VERSION ""

NS_ :

BS_:

BU_: GFM2_BCCMB ACCMB GFM3_DCACB FHCM SOBDMB_AWDC DCACA_GAS DCACA_HEV DCDC_LISB BCMC_CPDB DCMR_EAWD DCMR_ELSD BECMB_EPM PACM GFM_CPLR OBCC AFCM SOBDM_BCCM GWM _delete BCM ACCM GFM2_UIM ICM DCDC_HEV BECM SOBDMD_AHCM_PTC GENERIC TSTR

BO_ 533 APIM_Send_Signals_2_HS1: 8 GWM
 SG_ ClrExitAsstEnbl_D_RqMnu : 60|2@0+ (1,0) [0|3] "SED"  GENERIC
 SG_ PaakMyKey_D_Rq : 7|2@0+ (1,0) [0|3] "SED"  BCM
 SG_ AutoEpbZoomView_B_Stat : 32|1@0+ (1,0) [0|1] "SED"  GENERIC
 SG_ AutoEpbButtn_B_Stat : 19|1@0+ (1,0) [0|1] "SED"  GENERIC
 SG_ DcacPw_D_Rq : 62|2@0+ (1,0) [0|3] "SED"  GENERIC
 SG_ DcacPwReset_B_Rq : 63|1@0+ (1,0) [0|1] "SED"  GENERIC
 SG_ OtaTrg_D_Stat : 41|2@0+ (1,0) [0|3] "SED"  GENERIC
 SG_ DcacPwLoButtn_B_Stat : 13|1@0+ (1,0) [0|1] "SED"  GENERIC
 SG_ DcacPwOffButtn_B_Stat : 12|1@0+ (1,0) [0|1] "SED"  GENERIC
 SG_ DcacPwHiButtn_B_Stat : 14|1@0+ (1,0) [0|1] "SED"  GENERIC
 SG_ DcacPwResetButtn_B_Stat : 11|1@0+ (1,0) [0|1] "SED"  GENERIC
 SG_ DcacPwButtn_B_Falt : 15|1@0+ (1,0) [0|1] "SED"  GENERIC
 SG_ OnbChrgGoTTouch_D_Rq : 43|2@0+ (1,0) [0|3] "SED" Vector__XXX
 SG_ OnbChrgGoTPrcond_D_Rq : 34|2@0+ (1,0) [0|3] "SED" Vector__XXX
 SG_ OnbChrgGoTOn_D_Rq : 25|2@0+ (1,0) [0|3] "SED" Vector__XXX
 SG_ OnbChrgGoTMnte_D_Rq : 47|4@0+ (1,0) [0|15] "minute" Vector__XXX
 SG_ OnbChrgGoTHr_T_Rq : 39|5@0+ (1,0) [0|29] "hour" Vector__XXX
 SG_ OnbChrgGoTExtHtr_D_Rq : 27|2@0+ (1,0) [0|3] "SED" Vector__XXX
 SG_ OnbChrgGoTElement_D_Rq : 31|4@0+ (1,0) [0|15] "Unitless" Vector__XXX
 SG_ OnbChrgGoTDelete_B_Rq : 17|1@0+ (1,0) [0|1] "SED" Vector__XXX
 SG_ OnbChrgClearAll_B_Rq : 18|1@0+ (1,0) [0|1] "SED" Vector__XXX
 SG_ OnbChrgGoTUpdate_B_Rq : 16|1@0+ (1,0) [0|1] "SED" Vector__XXX
 SG_ TrlrAidMde_D_Rq : 5|2@0+ (1,0) [0|3] "SED"  GENERIC
 SG_ TCU_Init_Actvtn_St : 1|2@0+ (1,0) [0|3] "SED"  GENERIC
 SG_ TCU_Final_Actvtn_St : 3|2@0+ (1,0) [0|3] "SED"  GENERIC
 SG_ TrlrAlarmButtn_B_Stat : 50|1@0+ (1,0) [0|1] "SED"  GENERIC
 SG_ DcacMdeButtn_B_Stat : 8|1@0+ (1,0) [0|1] "SED"  GENERIC
 SG_ LghtAmbDrvMde_D_Rq : 49|2@0+ (1,0) [0|3] "SED"  BCM
 SG_ DcacGfciTestBttn_B_Stat : 9|1@0+ (1,0) [0|1] "SED"  GENERIC
 SG_ TrlrHitch_D_RqMnu : 23|4@0+ (1,0) [0|15] "SED"  GENERIC
 SG_ TrlrBrkGain_No_Rq : 55|5@0+ (0.5,0) [0|15.5] "unitless"  GENERIC
 SG_ DcacPwButtn_B_Stat : 10|1@0+ (1,0) [0|1] "SED"  GENERIC

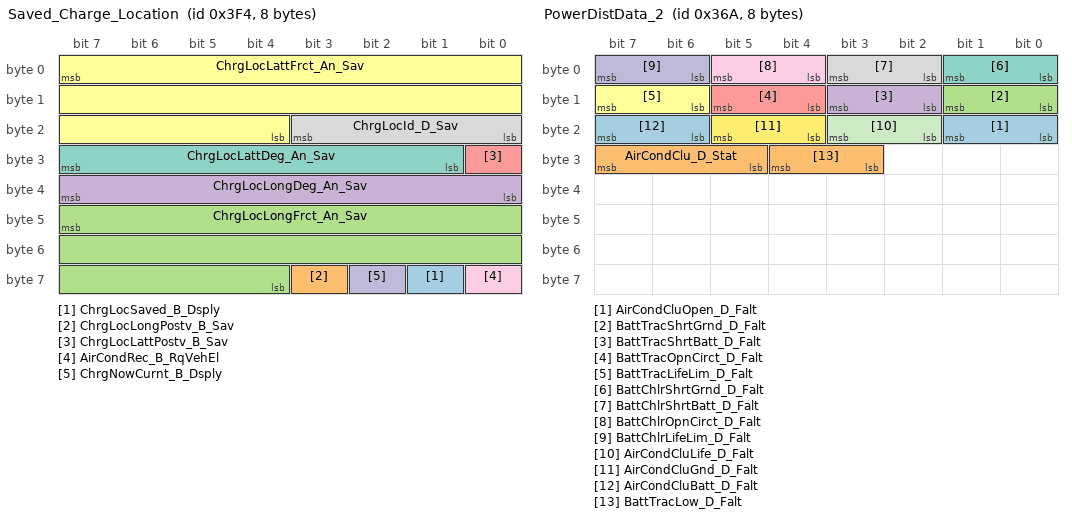
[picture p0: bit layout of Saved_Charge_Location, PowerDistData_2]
BO_ 1012 Saved_Charge_Location: 8 GWM
 SG_ ChrgLocSaved_B_Dsply : 57|1@0+ (1,0) [0|1] "SED"  GENERIC
 SG_ ChrgLocLongPostv_B_Sav : 59|1@0+ (1,0) [0|1] "SED"  GENERIC
 SG_ ChrgLocLongFrct_An_Sav : 47|20@0+ (1E-006,0) [0|1.048575] "degrees"  GENERIC
 SG_ ChrgLocLongDeg_An_Sav : 39|8@0+ (1,0) [0|255] "degrees"  GENERIC
 SG_ ChrgLocLattPostv_B_Sav : 24|1@0+ (1,0) [0|1] "SED"  GENERIC
 SG_ ChrgLocLattFrct_An_Sav : 7|20@0+ (1E-006,0) [0|1.048575] "degrees"  GENERIC
 SG_ ChrgLocLattDeg_An_Sav : 31|7@0+ (1,0) [0|127] "unitless"  GENERIC
 SG_ ChrgLocId_D_Sav : 19|4@0+ (1,0) [0|15] "unitless"  GENERIC
 SG_ AirCondRec_B_RqVehEl : 56|1@0+ (1,0) [0|1] "SED"  GENERIC
 SG_ ChrgNowCurnt_B_Dsply : 58|1@0+ (1,0) [0|1] "SED"  SOBDM_BCCM

BO_ 1711 DCMR_Rapid_Data_Response_4: 8 DCMR_EAWD
 SG_ UUDTDCMRResponse4 : 7|64@0+ (1,0) [0|1.84467440737096E+019] "unitless"  TSTR

BO_ 1710 DCMR_Rapid_Data_Response_3: 8 DCMR_EAWD
 SG_ UUDTDCMRResponse3 : 7|64@0+ (1,0) [0|1.84467440737096E+019] "unitless"  TSTR

BO_ 1709 DCMR_Rapid_Data_Response_2: 8 DCMR_EAWD
 SG_ UUDTDCMRResponse2 : 7|64@0+ (1,0) [0|1.84467440737096E+019] "unitless"  TSTR

BO_ 1708 DCMR_Rapid_Data_Response_1: 8 DCMR_EAWD
 SG_ UUDTDCMRResponse1 : 7|64@0+ (1,0) [0|1.84467440737096E+019] "unitless"  TSTR

BO_ 874 PowerDistData_2: 8 BCMC_CPDB
 SG_ AirCondCluOpen_D_Falt : 17|2@0+ (1,0) [0|3] "SED"  GWM
 SG_ AirCondClu_D_Stat : 31|3@0+ (1,0) [0|7] "SED"  GWM
 SG_ BattTracShrtGrnd_D_Falt : 9|2@0+ (1,0) [0|3] "SED"  GWM
 SG_ BattTracShrtBatt_D_Falt : 11|2@0+ (1,0) [0|3] "SED"  GWM
 SG_ BattTracOpnCirct_D_Falt : 13|2@0+ (1,0) [0|3] "SED"  GWM
 SG_ BattTracLifeLim_D_Falt : 15|2@0+ (1,0) [0|3] "SED"  GWM
 SG_ BattChlrShrtGrnd_D_Falt : 1|2@0+ (1,0) [0|3] "SED"  GWM
 SG_ BattChlrShrtBatt_D_Falt : 3|2@0+ (1,0) [0|3] "SED"  GWM
 SG_ BattChlrOpnCirct_D_Falt : 5|2@0+ (1,0) [0|3] "SED"  GWM
 SG_ BattChlrLifeLim_D_Falt : 7|2@0+ (1,0) [0|3] "SED"  GWM
 SG_ AirCondCluLife_D_Falt : 19|2@0+ (1,0) [0|3] "SED"  GWM
 SG_ AirCondCluGnd_D_Falt : 21|2@0+ (1,0) [0|3] "SED"  GWM
 SG_ AirCondCluBatt_D_Falt : 23|2@0+ (1,0) [0|3] "SED"  GWM
 SG_ BattTracLow_D_Falt : 28|2@0+ (1,0) [0|3] "SED"  GWM

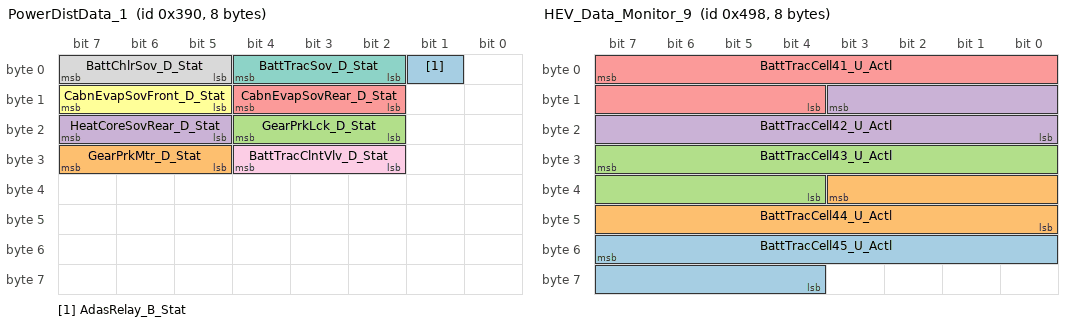
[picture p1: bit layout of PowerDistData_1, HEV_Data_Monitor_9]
BO_ 912 PowerDistData_1: 8 BCMC_CPDB
 SG_ AdasRelay_B_Stat : 1|1@0+ (1,0) [0|1] "SED"  GWM
 SG_ GearPrkMtr_D_Stat : 31|3@0+ (1,0) [0|7] "SED"  GWM
 SG_ GearPrkLck_D_Stat : 20|3@0+ (1,0) [0|7] "SED"  GWM
 SG_ HeatCoreSovRear_D_Stat : 23|3@0+ (1,0) [0|7] "SED"  GWM
 SG_ CabnEvapSovRear_D_Stat : 12|3@0+ (1,0) [0|7] "SED"  GWM
 SG_ CabnEvapSovFront_D_Stat : 15|3@0+ (1,0) [0|7] "SED"  GWM
 SG_ BattTracSov_D_Stat : 4|3@0+ (1,0) [0|7] "SED"  GWM
 SG_ BattChlrSov_D_Stat : 7|3@0+ (1,0) [0|7] "SED"  GWM
 SG_ BattTracClntVlv_D_Stat : 28|3@0+ (1,0) [0|7] "SED"  GWM

BO_ 1920 TesterPhysicalReqSGM: 8 TSTR
 SG_ TesterPhysicalReqSGM : 7|64@0+ (1,0) [0|1.84467E+019] "unitless" Vector__XXX

BO_ 1176 HEV_Data_Monitor_9: 8 BECM
 SG_ BattTracCell45_U_Actl : 55|12@0+ (0.001,1) [1|5.093] "volt"  GWM
 SG_ BattTracCell44_U_Actl : 35|12@0+ (0.001,1) [1|5.093] "volt"  GWM
 SG_ BattTracCell43_U_Actl : 31|12@0+ (0.001,1) [1|5.093] "volt"  GWM
 SG_ BattTracCell42_U_Actl : 11|12@0+ (0.001,1) [1|5.093] "volt"  GWM
 SG_ BattTracCell41_U_Actl : 7|12@0+ (0.001,1) [1|5.093] "volt"  GWM

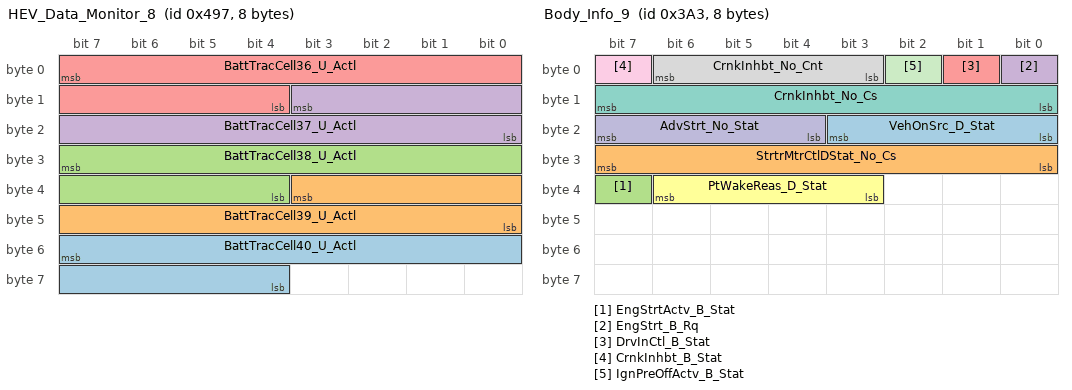
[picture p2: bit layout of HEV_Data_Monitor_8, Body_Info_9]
BO_ 1175 HEV_Data_Monitor_8: 8 BECM
 SG_ BattTracCell40_U_Actl : 55|12@0+ (0.001,1) [1|5.093] "volt"  GWM
 SG_ BattTracCell39_U_Actl : 35|12@0+ (0.001,1) [1|5.093] "volt"  GWM
 SG_ BattTracCell38_U_Actl : 31|12@0+ (0.001,1) [1|5.093] "volt"  GWM
 SG_ BattTracCell37_U_Actl : 11|12@0+ (0.001,1) [1|5.093] "volt"  GWM
 SG_ BattTracCell36_U_Actl : 7|12@0+ (0.001,1) [1|5.093] "volt"  GWM

BO_ 931 Body_Info_9: 8 BCM
 SG_ VehOnSrc_D_Stat : 19|4@0+ (1,0) [0|15] "SED"  BCMC_CPDB,GWM,FHCM,SOBDMB_AWDC
 SG_ StrtrMtrCtlDStat_No_Cs : 31|8@0+ (1,0) [0|255] "unitless"  GWM,SOBDMB_AWDC
 SG_ EngStrtActv_B_Stat : 39|1@0+ (1,0) [0|1] "SED"  GWM,SOBDMB_AWDC
 SG_ EngStrt_B_Rq : 0|1@0+ (1,0) [0|1] "SED"  GWM,SOBDMB_AWDC
 SG_ DrvInCtl_B_Stat : 1|1@0+ (1,0) [0|1] "SED"  GWM,SOBDMB_AWDC
 SG_ PtWakeReas_D_Stat : 38|4@0+ (1,0) [0|15] "SED"  GWM
 SG_ CrnkInhbt_No_Cs : 15|8@0+ (1,0) [0|255] "Unitless"  GWM
 SG_ CrnkInhbt_No_Cnt : 6|4@0+ (1,0) [0|15] "Unitless"  GWM,SOBDMB_AWDC
 SG_ CrnkInhbt_B_Stat : 7|1@0+ (1,0) [0|1] "SED"  GWM,SOBDMB_AWDC
 SG_ AdvStrt_No_Stat : 23|4@0+ (1,0) [0|15] "unitless"  GWM,SOBDMB_AWDC
 SG_ IgnPreOffActv_B_Stat : 2|1@0+ (1,0) [0|1] "SED"  GWM

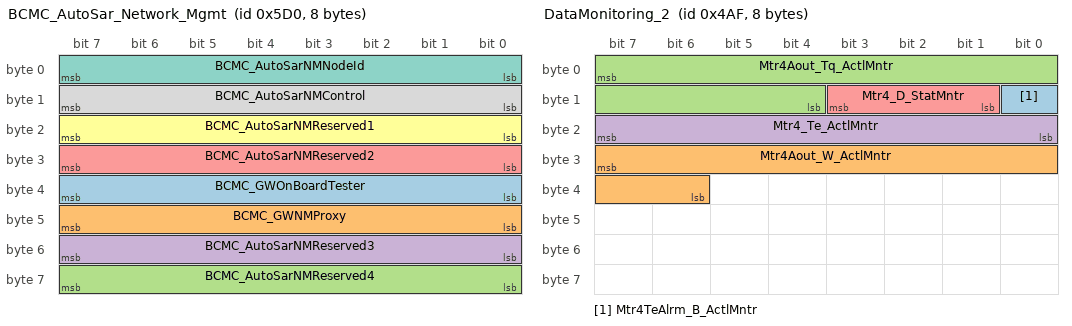
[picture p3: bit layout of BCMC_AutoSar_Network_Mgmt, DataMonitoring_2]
BO_ 1488 BCMC_AutoSar_Network_Mgmt: 8 BCMC_CPDB
 SG_ BCMC_GWOnBoardTester : 39|8@0+ (1,0) [0|255] "unitless"  GWM
 SG_ BCMC_GWNMProxy : 47|8@0+ (1,0) [0|255] "unitless"  GWM
 SG_ BCMC_AutoSarNMReserved4 : 63|8@0+ (1,0) [0|255] "unitless"  GWM
 SG_ BCMC_AutoSarNMReserved3 : 55|8@0+ (1,0) [0|255] "unitless"  GWM
 SG_ BCMC_AutoSarNMReserved2 : 31|8@0+ (1,0) [0|255] "unitless"  GWM
 SG_ BCMC_AutoSarNMReserved1 : 23|8@0+ (1,0) [0|255] "unitless"  GWM
 SG_ BCMC_AutoSarNMNodeId : 7|8@0+ (1,0) [0|255] "unitless"  GWM
 SG_ BCMC_AutoSarNMControl : 15|8@0+ (1,0) [0|255] "unitless"  GWM

BO_ 1776 TesterPhysicalReqBCMC_CPDB: 8 TSTR
 SG_ TesterPhysicalReqBCMC_CPDB : 7|64@0+ (1,0) [0|1.84467E+019] "unitless"  BCMC_CPDB

BO_ 1784 TesterPhysicalResBCMC_CPDB: 8 BCMC_CPDB
 SG_ TesterPhysicalResBCMC_CPDB : 7|64@0+ (1,0) [0|1.84467E+019] "unitless"  TSTR

BO_ 1247 PowerDistData_4: 8 BCMC_CPDB
 SG_ TrlrBrkCtl3_B_Falt : 2|1@0+ (1,0) [0|1] "SED"  GWM
 SG_ StopLampBRqTrlrAft_No_Cs : 15|8@0+ (1,0) [0|255] "Unitless"  GWM
 SG_ StopLampBRqTrlrAft_No_Cnt : 6|4@0+ (1,0) [0|15] "Unitless"  GWM
 SG_ StopLamp_B_RqTrlrAft : 7|1@0+ (1,0) [0|1] "SED"  GWM

BO_ 1167 DataMonitoring_1: 8 SOBDMB_AWDC
 SG_ PrplAxlScnd_Tq_ActlMntr : 31|16@0+ (4,-131072) [-131072|131060] "Nm"  GWM
 SG_ Inv4TeAlrm_B_ActlMntr : 16|1@0+ (1,0) [0|1] "SED"  GWM
 SG_ Inv4Ain_U_ActlMntr : 47|10@0+ (0.5,0) [0|510.5] "volt"  GWM
 SG_ Inv4Ain_I_ActlMntr : 15|15@0+ (0.1,-1000) [-1000|2276.5] "ampere"  GWM
 SG_ Inv4_Te_ActlMntr : 7|8@0+ (1,-40) [-40|213] "degC"  GWM

BO_ 1199 DataMonitoring_2: 8 SOBDMB_AWDC
 SG_ Mtr4TeAlrm_B_ActlMntr : 8|1@0+ (1,0) [0|1] "SED"  GWM
 SG_ Mtr4Aout_W_ActlMntr : 31|10@0+ (6.28,-3209) [-3209|3209.16] "radians/sec"  GWM
 SG_ Mtr4Aout_Tq_ActlMntr : 7|12@0+ (1,-2047) [-2047|2048] "Nm"  GWM
 SG_ Mtr4_Te_ActlMntr : 23|8@0+ (1,-40) [-40|213] "degC"  GWM
 SG_ Mtr4_D_StatMntr : 11|3@0+ (1,0) [0|7] "SED"  GWM

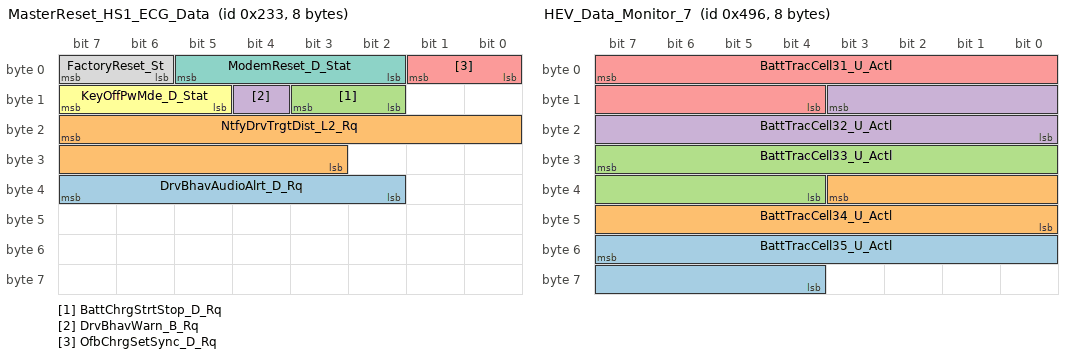
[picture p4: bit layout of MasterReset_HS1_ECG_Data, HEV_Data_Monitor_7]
BO_ 563 MasterReset_HS1_ECG_Data: 8 GWM
 SG_ DrvBhavAudioAlrt_D_Rq : 39|6@0+ (1,0) [0|63] "SED"  GENERIC
 SG_ NtfyDrvTrgtDist_L2_Rq : 23|13@0+ (0.1,0) [0|818.9] "Km"  GENERIC
 SG_ BattChrgStrtStop_D_Rq : 11|2@0+ (1,0) [0|3] "SED"  GENERIC
 SG_ DrvBhavWarn_B_Rq : 12|1@0+ (1,0) [0|1] "SED"  GENERIC
 SG_ OfbChrgSetSync_D_Rq : 1|2@0+ (1,0) [0|3] "SED"  GENERIC
 SG_ KeyOffPwMde_D_Stat : 15|3@0+ (1,0) [0|7] "SED"  GENERIC
 SG_ ModemReset_D_Stat : 5|4@0+ (1,0) [0|15] "SED"  GENERIC
 SG_ FactoryReset_St : 7|2@0+ (1,0) [0|3] "SED"  GENERIC

BO_ 1705 SOBDMB_RapidDataResponse_2: 8 SOBDMB_AWDC
 SG_ UUDTSOBDMBResponse2 : 7|64@0+ (1,0) [0|1.84467440737096E+019] "unitless"  TSTR

BO_ 1704 SOBDMB_RapidDataResponse_1: 8 SOBDMB_AWDC
 SG_ UUDTSOBDMBResponse1 : 7|64@0+ (1,0) [0|1.84467440737096E+019] "unitless"  TSTR

BO_ 1174 HEV_Data_Monitor_7: 8 BECM
 SG_ BattTracCell35_U_Actl : 55|12@0+ (0.001,1) [1|5.093] "volt"  GWM
 SG_ BattTracCell34_U_Actl : 35|12@0+ (0.001,1) [1|5.093] "volt"  GWM
 SG_ BattTracCell33_U_Actl : 31|12@0+ (0.001,1) [1|5.093] "volt"  GWM
 SG_ BattTracCell32_U_Actl : 11|12@0+ (0.001,1) [1|5.093] "volt"  GWM
 SG_ BattTracCell31_U_Actl : 7|12@0+ (0.001,1) [1|5.093] "volt"  GWM

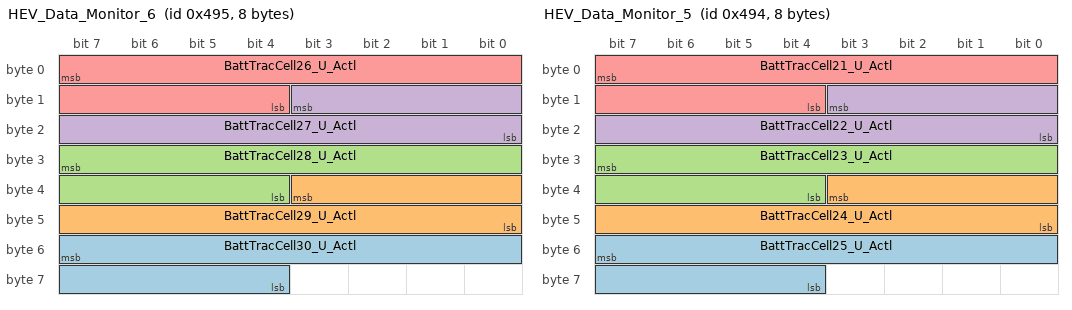
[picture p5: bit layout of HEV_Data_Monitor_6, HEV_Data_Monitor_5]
BO_ 1173 HEV_Data_Monitor_6: 8 BECM
 SG_ BattTracCell30_U_Actl : 55|12@0+ (0.001,1) [1|5.093] "volt"  GWM
 SG_ BattTracCell29_U_Actl : 35|12@0+ (0.001,1) [1|5.093] "volt"  GWM
 SG_ BattTracCell28_U_Actl : 31|12@0+ (0.001,1) [1|5.093] "volt"  GWM
 SG_ BattTracCell27_U_Actl : 11|12@0+ (0.001,1) [1|5.093] "volt"  GWM
 SG_ BattTracCell26_U_Actl : 7|12@0+ (0.001,1) [1|5.093] "volt"  GWM

BO_ 1172 HEV_Data_Monitor_5: 8 BECM
 SG_ BattTracCell25_U_Actl : 55|12@0+ (0.001,1) [1|5.093] "volt"  GWM
 SG_ BattTracCell24_U_Actl : 35|12@0+ (0.001,1) [1|5.093] "volt"  GWM
 SG_ BattTracCell23_U_Actl : 31|12@0+ (0.001,1) [1|5.093] "volt"  GWM
 SG_ BattTracCell22_U_Actl : 11|12@0+ (0.001,1) [1|5.093] "volt"  GWM
 SG_ BattTracCell21_U_Actl : 7|12@0+ (0.001,1) [1|5.093] "volt"  GWM

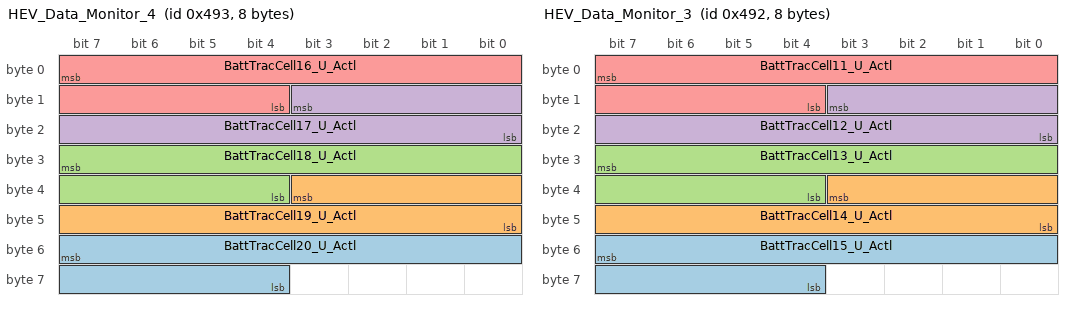
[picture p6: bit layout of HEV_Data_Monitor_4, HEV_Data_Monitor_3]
BO_ 1171 HEV_Data_Monitor_4: 8 BECM
 SG_ BattTracCell20_U_Actl : 55|12@0+ (0.001,1) [1|5.093] "volt"  GWM
 SG_ BattTracCell19_U_Actl : 35|12@0+ (0.001,1) [1|5.093] "volt"  GWM
 SG_ BattTracCell18_U_Actl : 31|12@0+ (0.001,1) [1|5.093] "volt"  GWM
 SG_ BattTracCell17_U_Actl : 11|12@0+ (0.001,1) [1|5.093] "volt"  GWM
 SG_ BattTracCell16_U_Actl : 7|12@0+ (0.001,1) [1|5.093] "volt"  GWM

BO_ 1170 HEV_Data_Monitor_3: 8 BECM
 SG_ BattTracCell15_U_Actl : 55|12@0+ (0.001,1) [1|5.093] "volt"  GWM
 SG_ BattTracCell14_U_Actl : 35|12@0+ (0.001,1) [1|5.093] "volt"  GWM
 SG_ BattTracCell13_U_Actl : 31|12@0+ (0.001,1) [1|5.093] "volt"  GWM
 SG_ BattTracCell12_U_Actl : 11|12@0+ (0.001,1) [1|5.093] "volt"  GWM
 SG_ BattTracCell11_U_Actl : 7|12@0+ (0.001,1) [1|5.093] "volt"  GWM

BO_ 1191 HEV_Data_Monitor_23: 8 BECM
 SG_ BattTracTe14_Te_Actl : 7|8@0+ (1,-50) [-50|203] "degC"  GWM
 SG_ BattTracTe19_Te_Actl : 47|8@0+ (1,-50) [-50|203] "degC"  GWM
 SG_ BattTracTe18_Te_Actl : 39|8@0+ (1,-50) [-50|203] "degC"  GWM
 SG_ BattTracTe17_Te_Actl : 31|8@0+ (1,-50) [-50|203] "degC"  GWM
 SG_ BattTracTe16_Te_Actl : 23|8@0+ (1,-50) [-50|203] "degC"  GWM
 SG_ BattTracTe15_Te_Actl : 15|8@0+ (1,-50) [-50|203] "degC"  GWM

BO_ 1189 HEV_Data_Monitor_22: 8 BECM
 SG_ BattTracUMxArry_No_Actl : 52|5@0+ (1,0) [0|30] "unitless"  GWM,OBCC
 SG_ BattTracCellUMx_No_Actl : 63|8@0+ (1,0) [0|253] "Unitless"  GWM,OBCC
 SG_ BattChrgUMx_B_Falt : 53|1@0+ (1,0) [0|1] "SED"  GWM
 SG_ BattTracCellUMn_No_Actl : 15|8@0+ (1,0) [0|253] "Unitless"  GWM
 SG_ BattTracCellCnt_No_Actl : 7|8@0+ (1,0) [0|253] "Unitless"  GWM
 SG_ BattChrgIsltn_B_Falt : 47|1@0+ (1,0) [0|1] "SED"  GWM,OBCC
 SG_ BattTracCellDiff_B_Falt : 43|1@0+ (1,0) [0|1] "SED"  GWM
 SG_ BattChrgSocMx_B_Falt : 44|1@0+ (1,0) [0|1] "SED"  GWM,OBCC
 SG_ BattChrgSocMn_B_Falt : 45|1@0+ (1,0) [0|1] "SED"  GWM,OBCC
 SG_ BattChrgSocErrtc_B_Falt : 46|1@0+ (1,0) [0|1] "SED"  GWM
 SG_ BattTracUMx_B_Falt : 54|1@0+ (1,0) [0|1] "SED"  GWM,OBCC
 SG_ BattTracUMn_B_Falt : 55|1@0+ (1,0) [0|1] "SED"  GWM,OBCC
 SG_ BattTracTeMx_No_Actl : 39|8@0+ (1,0) [0|253] "Unitless"  GWM,OBCC
 SG_ BattTracTeMx_B_Falt : 40|1@0+ (1,0) [0|1] "SED"  GWM,OBCC
 SG_ BattTracTeMn_No_Actl : 31|8@0+ (1,0) [0|253] "Unitless"  GWM,OBCC
 SG_ BattTracTeDelta_B_Falt : 41|1@0+ (1,0) [0|1] "SED"  GWM
 SG_ BattTracTeCnt_No_Actl : 23|8@0+ (1,0) [0|253] "Unitless"  GWM
 SG_ BattTracSoftware_B_Falt : 42|1@0+ (1,0) [0|1] "SED"  GWM

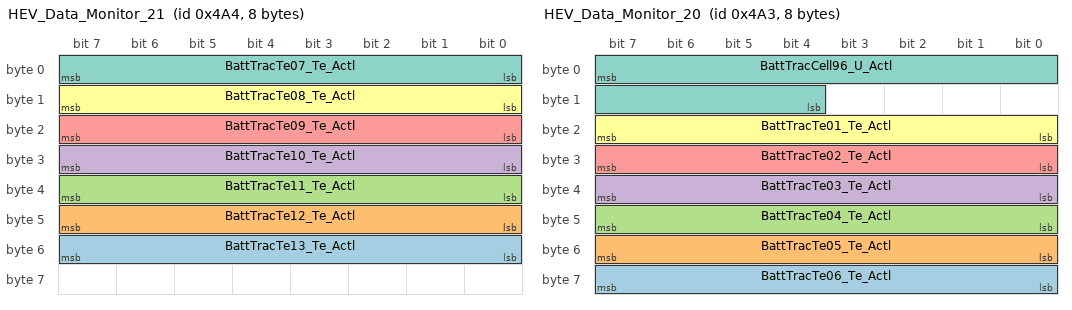
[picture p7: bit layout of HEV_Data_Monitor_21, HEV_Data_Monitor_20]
BO_ 1188 HEV_Data_Monitor_21: 8 BECM
 SG_ BattTracTe13_Te_Actl : 55|8@0+ (1,-50) [-50|203] "degC"  GWM
 SG_ BattTracTe12_Te_Actl : 47|8@0+ (1,-50) [-50|203] "degC"  GWM
 SG_ BattTracTe11_Te_Actl : 39|8@0+ (1,-50) [-50|203] "degC"  GWM
 SG_ BattTracTe10_Te_Actl : 31|8@0+ (1,-50) [-50|203] "degC"  GWM
 SG_ BattTracTe09_Te_Actl : 23|8@0+ (1,-50) [-50|203] "degC"  GWM
 SG_ BattTracTe08_Te_Actl : 15|8@0+ (1,-50) [-50|203] "degC"  GWM
 SG_ BattTracTe07_Te_Actl : 7|8@0+ (1,-50) [-50|203] "degC"  GWM

BO_ 1187 HEV_Data_Monitor_20: 8 BECM
 SG_ BattTracTe06_Te_Actl : 63|8@0+ (1,-50) [-50|203] "degC"  GWM
 SG_ BattTracTe05_Te_Actl : 55|8@0+ (1,-50) [-50|203] "degC"  GWM
 SG_ BattTracTe04_Te_Actl : 47|8@0+ (1,-50) [-50|203] "degC"  GWM
 SG_ BattTracTe03_Te_Actl : 39|8@0+ (1,-50) [-50|203] "degC"  GWM
 SG_ BattTracTe02_Te_Actl : 31|8@0+ (1,-50) [-50|203] "degC"  GWM
 SG_ BattTracTe01_Te_Actl : 23|8@0+ (1,-50) [-50|203] "degC"  GWM
 SG_ BattTracCell96_U_Actl : 7|12@0+ (0.001,1) [1|5.093] "volt"  GWM

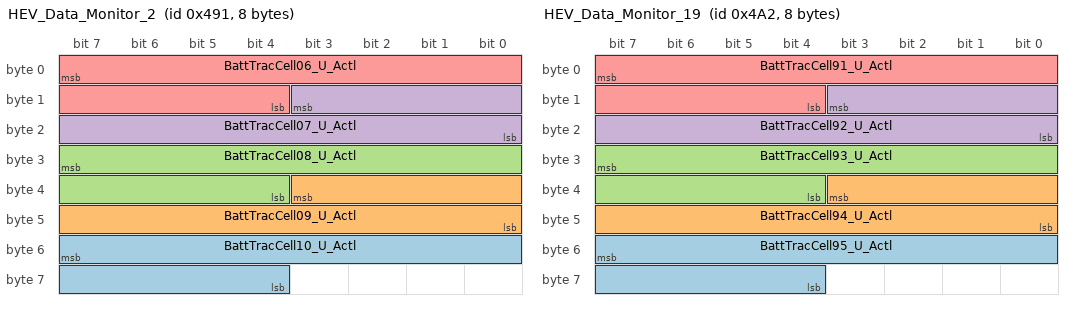
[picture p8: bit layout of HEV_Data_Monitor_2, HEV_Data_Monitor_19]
BO_ 1169 HEV_Data_Monitor_2: 8 BECM
 SG_ BattTracCell10_U_Actl : 55|12@0+ (0.001,1) [1|5.093] "volt"  GWM
 SG_ BattTracCell09_U_Actl : 35|12@0+ (0.001,1) [1|5.093] "volt"  GWM
 SG_ BattTracCell08_U_Actl : 31|12@0+ (0.001,1) [1|5.093] "volt"  GWM
 SG_ BattTracCell07_U_Actl : 11|12@0+ (0.001,1) [1|5.093] "volt"  GWM
 SG_ BattTracCell06_U_Actl : 7|12@0+ (0.001,1) [1|5.093] "volt"  GWM

BO_ 1186 HEV_Data_Monitor_19: 8 BECM
 SG_ BattTracCell95_U_Actl : 55|12@0+ (0.001,1) [1|5.093] "volt"  GWM
 SG_ BattTracCell94_U_Actl : 35|12@0+ (0.001,1) [1|5.093] "volt"  GWM
 SG_ BattTracCell93_U_Actl : 31|12@0+ (0.001,1) [1|5.093] "volt"  GWM
 SG_ BattTracCell92_U_Actl : 11|12@0+ (0.001,1) [1|5.093] "volt"  GWM
 SG_ BattTracCell91_U_Actl : 7|12@0+ (0.001,1) [1|5.093] "volt"  GWM

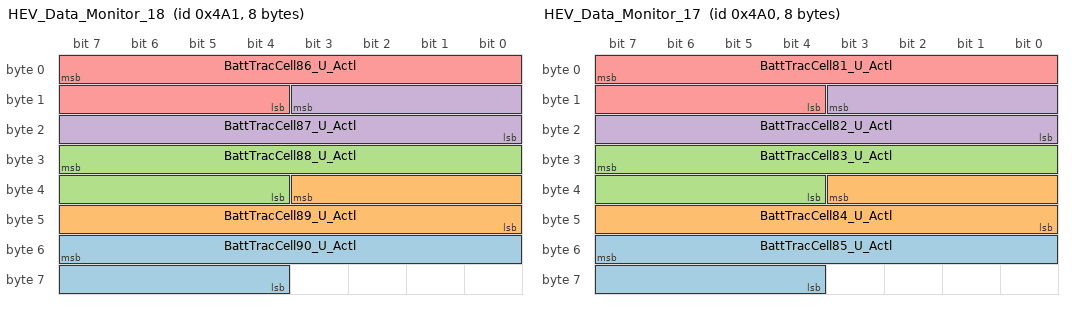
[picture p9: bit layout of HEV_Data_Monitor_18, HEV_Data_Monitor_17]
BO_ 1185 HEV_Data_Monitor_18: 8 BECM
 SG_ BattTracCell90_U_Actl : 55|12@0+ (0.001,1) [1|5.093] "volt"  GWM
 SG_ BattTracCell89_U_Actl : 35|12@0+ (0.001,1) [1|5.093] "volt"  GWM
 SG_ BattTracCell88_U_Actl : 31|12@0+ (0.001,1) [1|5.093] "volt"  GWM
 SG_ BattTracCell87_U_Actl : 11|12@0+ (0.001,1) [1|5.093] "volt"  GWM
 SG_ BattTracCell86_U_Actl : 7|12@0+ (0.001,1) [1|5.093] "volt"  GWM

BO_ 1184 HEV_Data_Monitor_17: 8 BECM
 SG_ BattTracCell85_U_Actl : 55|12@0+ (0.001,1) [1|5.093] "volt"  GWM
 SG_ BattTracCell84_U_Actl : 35|12@0+ (0.001,1) [1|5.093] "volt"  GWM
 SG_ BattTracCell83_U_Actl : 31|12@0+ (0.001,1) [1|5.093] "volt"  GWM
 SG_ BattTracCell82_U_Actl : 11|12@0+ (0.001,1) [1|5.093] "volt"  GWM
 SG_ BattTracCell81_U_Actl : 7|12@0+ (0.001,1) [1|5.093] "volt"  GWM

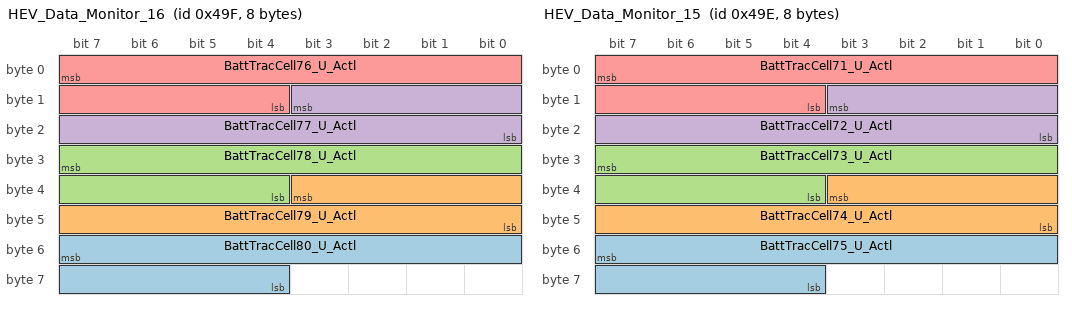
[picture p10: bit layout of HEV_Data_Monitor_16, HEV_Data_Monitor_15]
BO_ 1183 HEV_Data_Monitor_16: 8 BECM
 SG_ BattTracCell80_U_Actl : 55|12@0+ (0.001,1) [1|5.093] "volt"  GWM
 SG_ BattTracCell79_U_Actl : 35|12@0+ (0.001,1) [1|5.093] "volt"  GWM
 SG_ BattTracCell78_U_Actl : 31|12@0+ (0.001,1) [1|5.093] "volt"  GWM
 SG_ BattTracCell77_U_Actl : 11|12@0+ (0.001,1) [1|5.093] "volt"  GWM
 SG_ BattTracCell76_U_Actl : 7|12@0+ (0.001,1) [1|5.093] "volt"  GWM

BO_ 1182 HEV_Data_Monitor_15: 8 BECM
 SG_ BattTracCell75_U_Actl : 55|12@0+ (0.001,1) [1|5.093] "volt"  GWM
 SG_ BattTracCell74_U_Actl : 35|12@0+ (0.001,1) [1|5.093] "volt"  GWM
 SG_ BattTracCell73_U_Actl : 31|12@0+ (0.001,1) [1|5.093] "volt"  GWM
 SG_ BattTracCell72_U_Actl : 11|12@0+ (0.001,1) [1|5.093] "volt"  GWM
 SG_ BattTracCell71_U_Actl : 7|12@0+ (0.001,1) [1|5.093] "volt"  GWM

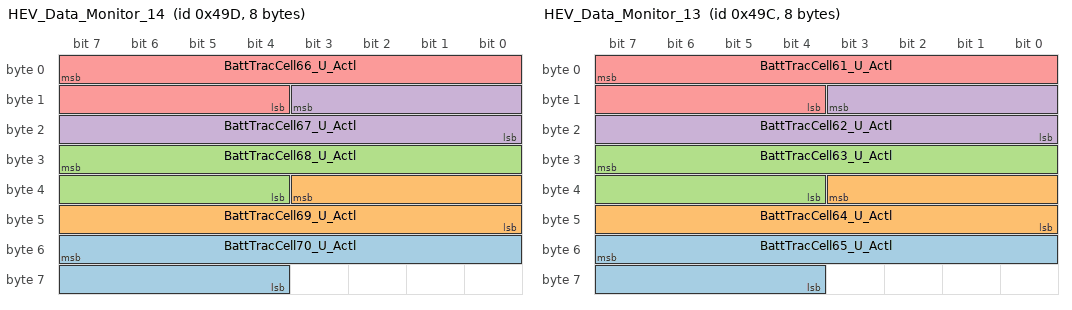
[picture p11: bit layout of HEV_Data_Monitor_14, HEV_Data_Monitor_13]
BO_ 1181 HEV_Data_Monitor_14: 8 BECM
 SG_ BattTracCell70_U_Actl : 55|12@0+ (0.001,1) [1|5.093] "volt"  GWM
 SG_ BattTracCell69_U_Actl : 35|12@0+ (0.001,1) [1|5.093] "volt"  GWM
 SG_ BattTracCell68_U_Actl : 31|12@0+ (0.001,1) [1|5.093] "volt"  GWM
 SG_ BattTracCell67_U_Actl : 11|12@0+ (0.001,1) [1|5.093] "volt"  GWM
 SG_ BattTracCell66_U_Actl : 7|12@0+ (0.001,1) [1|5.093] "volt"  GWM

BO_ 1180 HEV_Data_Monitor_13: 8 BECM
 SG_ BattTracCell65_U_Actl : 55|12@0+ (0.001,1) [1|5.093] "volt"  GWM
 SG_ BattTracCell64_U_Actl : 35|12@0+ (0.001,1) [1|5.093] "volt"  GWM
 SG_ BattTracCell63_U_Actl : 31|12@0+ (0.001,1) [1|5.093] "volt"  GWM
 SG_ BattTracCell62_U_Actl : 11|12@0+ (0.001,1) [1|5.093] "volt"  GWM
 SG_ BattTracCell61_U_Actl : 7|12@0+ (0.001,1) [1|5.093] "volt"  GWM

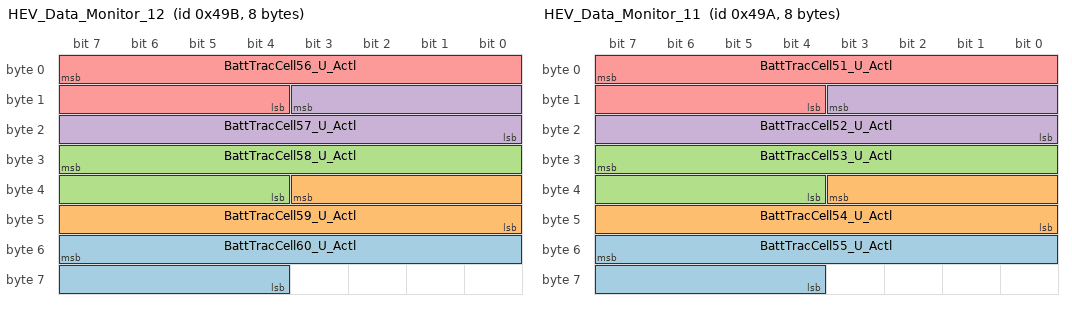
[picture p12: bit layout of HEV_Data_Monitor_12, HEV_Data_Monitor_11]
BO_ 1179 HEV_Data_Monitor_12: 8 BECM
 SG_ BattTracCell60_U_Actl : 55|12@0+ (0.001,1) [1|5.093] "volt"  GWM
 SG_ BattTracCell59_U_Actl : 35|12@0+ (0.001,1) [1|5.093] "volt"  GWM
 SG_ BattTracCell58_U_Actl : 31|12@0+ (0.001,1) [1|5.093] "volt"  GWM
 SG_ BattTracCell57_U_Actl : 11|12@0+ (0.001,1) [1|5.093] "volt"  GWM
 SG_ BattTracCell56_U_Actl : 7|12@0+ (0.001,1) [1|5.093] "volt"  GWM

BO_ 1178 HEV_Data_Monitor_11: 8 BECM
 SG_ BattTracCell55_U_Actl : 55|12@0+ (0.001,1) [1|5.093] "volt"  GWM
 SG_ BattTracCell54_U_Actl : 35|12@0+ (0.001,1) [1|5.093] "volt"  GWM
 SG_ BattTracCell53_U_Actl : 31|12@0+ (0.001,1) [1|5.093] "volt"  GWM
 SG_ BattTracCell52_U_Actl : 11|12@0+ (0.001,1) [1|5.093] "volt"  GWM
 SG_ BattTracCell51_U_Actl : 7|12@0+ (0.001,1) [1|5.093] "volt"  GWM

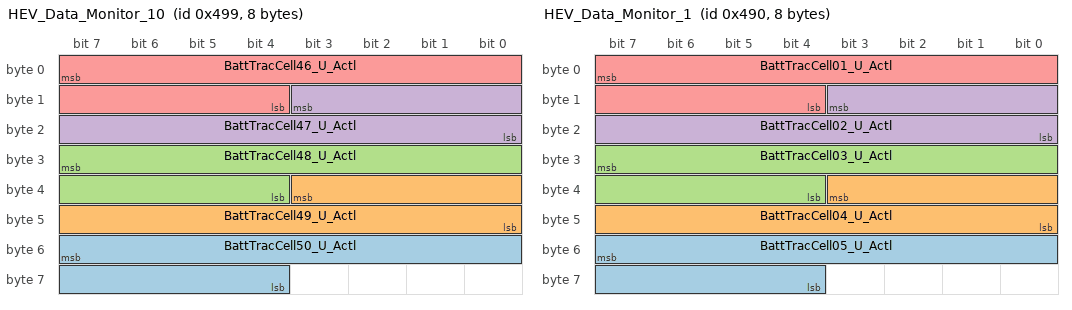
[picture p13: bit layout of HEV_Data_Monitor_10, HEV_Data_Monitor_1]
BO_ 1177 HEV_Data_Monitor_10: 8 BECM
 SG_ BattTracCell50_U_Actl : 55|12@0+ (0.001,1) [1|5.093] "volt"  GWM
 SG_ BattTracCell49_U_Actl : 35|12@0+ (0.001,1) [1|5.093] "volt"  GWM
 SG_ BattTracCell48_U_Actl : 31|12@0+ (0.001,1) [1|5.093] "volt"  GWM
 SG_ BattTracCell47_U_Actl : 11|12@0+ (0.001,1) [1|5.093] "volt"  GWM
 SG_ BattTracCell46_U_Actl : 7|12@0+ (0.001,1) [1|5.093] "volt"  GWM

BO_ 1168 HEV_Data_Monitor_1: 8 BECM
 SG_ BattTracCell05_U_Actl : 55|12@0+ (0.001,1) [1|5.093] "volt"  GWM
 SG_ BattTracCell04_U_Actl : 35|12@0+ (0.001,1) [1|5.093] "volt"  GWM
 SG_ BattTracCell03_U_Actl : 31|12@0+ (0.001,1) [1|5.093] "volt"  GWM
 SG_ BattTracCell02_U_Actl : 11|12@0+ (0.001,1) [1|5.093] "volt"  GWM
 SG_ BattTracCell01_U_Actl : 7|12@0+ (0.001,1) [1|5.093] "volt"  GWM

BO_ 1768 TesterPhysicalResACCMB: 8 ACCMB
 SG_ TesterPhysicalResACCMB : 7|64@0+ (1,0) [0|1.84467E+019] "unitless"  TSTR

BO_ 1760 TesterPhysicalReqACCMB: 8 TSTR
 SG_ TesterPhysicalReqACCMB : 7|64@0+ (1,0) [0|1.84467E+019] "unitless"  ACCMB

BO_ 1807 TesterPhysicalResGFM3DCACB: 8 GFM3_DCACB
 SG_ TesterPhysicalResGFM3DCACB : 7|64@0+ (1,0) [0|1.84467E+019] "unitless"  TSTR

BO_ 1799 TesterPhysicalReqGFM3DCACB: 8 TSTR
 SG_ TesterPhysicalReqGFM3DCACB : 7|64@0+ (1,0) [0|1.84467E+019] "unitless"  GFM3_DCACB

BO_ 2612224204 PARSEDPushDCDCtoGWM_ECG: 8 DCDC_LISB
 SG_ PARSEDPushDCDCtoGWM_ECG : 7|29@0+ (1,0) [0|536870911] "unitless"  GWM

BO_ 2611175628 PARSEDPhysDCDCtoGWM_ECG: 8 DCDC_LISB
 SG_ PARSEDPhysDCDCtoGWM_ECG : 7|29@0+ (1,0) [0|536870911] "unitless"  GWM

BO_ 2610114776 OTAPhysGWM_ECGtoDCDC: 8 GWM
 SG_ OTAPhysGWM_ECGtoDCDC : 7|29@0+ (1,0) [0|536870911] "unitless"  DCDC_LISB

BO_ 2610127052 OTAPhysDCDCtoGWM_ECG: 8 DCDC_LISB
 SG_ OTAPhysDCDCtoGWM_ECG : 7|29@0+ (1,0) [0|536870911] "unitless"  GWM

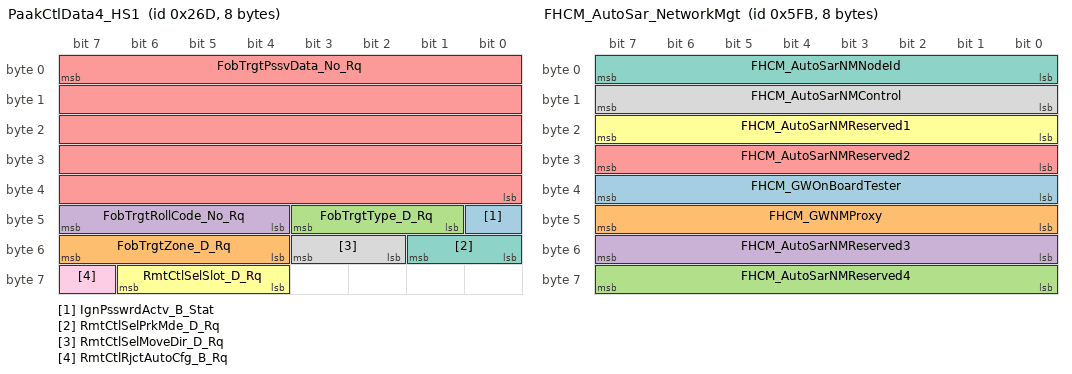
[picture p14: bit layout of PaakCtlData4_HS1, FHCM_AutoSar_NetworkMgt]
BO_ 621 PaakCtlData4_HS1: 8 GWM
 SG_ IgnPsswrdActv_B_Stat : 40|1@0+ (1,0) [0|1] "SED"  BCM
 SG_ FobTrgtZone_D_Rq : 55|4@0+ (1,0) [0|15] "SED"  BCM
 SG_ FobTrgtType_D_Rq : 43|3@0+ (1,0) [0|7] "SED"  BCM
 SG_ FobTrgtRollCode_No_Rq : 47|4@0+ (1,0) [0|15] "unitless"  BCM
 SG_ FobTrgtPssvData_No_Rq : 7|40@0+ (1,0) [0|1099511627775] "Encrypted"  BCM
 SG_ RmtCtlSelSlot_D_Rq : 62|3@0+ (1,0) [0|7] "SED"  GENERIC
 SG_ RmtCtlSelPrkMde_D_Rq : 49|2@0+ (1,0) [0|3] "SED"  GENERIC
 SG_ RmtCtlSelMoveDir_D_Rq : 51|2@0+ (1,0) [0|3] "SED"  GENERIC
 SG_ RmtCtlRjctAutoCfg_B_Rq : 63|1@0+ (1,0) [0|1] "SED"  GENERIC

BO_ 1763 TesterPhysicalReqFHCM: 8 TSTR
 SG_ TesterPhysicalReqFHCM : 7|64@0+ (1,0) [0|1.84467E+019] "unitless"  FHCM

BO_ 1771 TesterPhysicalResFHCM: 8 FHCM
 SG_ TesterPhysicalResFHCM : 7|64@0+ (1,0) [0|1.84467E+019] "unitless"  TSTR

BO_ 1531 FHCM_AutoSar_NetworkMgt: 8 FHCM
 SG_ FHCM_GWOnBoardTester : 39|8@0+ (1,0) [0|255] "unitless" Vector__XXX
 SG_ FHCM_GWNMProxy : 47|8@0+ (1,0) [0|255] "unitless" Vector__XXX
 SG_ FHCM_AutoSarNMReserved4 : 63|8@0+ (1,0) [0|255] "unitless" Vector__XXX
 SG_ FHCM_AutoSarNMReserved3 : 55|8@0+ (1,0) [0|255] "unitless" Vector__XXX
 SG_ FHCM_AutoSarNMReserved2 : 31|8@0+ (1,0) [0|255] "unitless" Vector__XXX
 SG_ FHCM_AutoSarNMReserved1 : 23|8@0+ (1,0) [0|255] "unitless" Vector__XXX
 SG_ FHCM_AutoSarNMNodeId : 7|8@0+ (1,0) [0|255] "unitless" Vector__XXX
 SG_ FHCM_AutoSarNMControl : 15|8@0+ (1,0) [0|255] "unitless" Vector__XXX

BO_ 2611163352 PARSEDPhysGWM_ECGtoDCDC: 8 GWM
 SG_ PARSEDPhysGWM_ECGtoDCDC : 7|29@0+ (1,0) [0|536870911] "unitless"  DCDC_LISB

BO_ 2612211928 PARSEDPushFcGWM_ECGtoDCDC: 8 GWM
 SG_ PARSEDPushFcGWM_ECGtoDCDC : 7|29@0+ (1,0) [0|536870911] "unitless"  DCDC_LISB

BO_ 1149 Battery_Traction_10: 8 BECM
 SG_ BattTracPerf_Pc_Dsply : 15|8@0+ (1,0) [0|253] "percent"  GWM
 SG_ BattTracPerf_Pc_Actl : 7|8@0+ (1,0) [0|253] "percent"  GWM

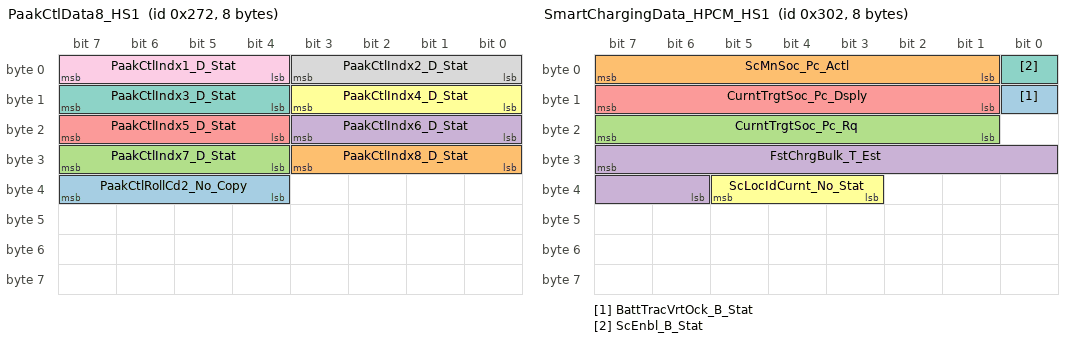
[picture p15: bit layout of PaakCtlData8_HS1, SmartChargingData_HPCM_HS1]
BO_ 626 PaakCtlData8_HS1: 8 GWM
 SG_ PaakCtlRollCd2_No_Copy : 39|4@0+ (1,0) [0|15] "unitless"  BCM
 SG_ PaakCtlIndx8_D_Stat : 27|4@0+ (1,0) [0|15] "SED"  BCM
 SG_ PaakCtlIndx7_D_Stat : 31|4@0+ (1,0) [0|15] "SED"  BCM
 SG_ PaakCtlIndx6_D_Stat : 19|4@0+ (1,0) [0|15] "SED"  BCM
 SG_ PaakCtlIndx5_D_Stat : 23|4@0+ (1,0) [0|15] "SED"  BCM
 SG_ PaakCtlIndx4_D_Stat : 11|4@0+ (1,0) [0|15] "SED"  BCM
 SG_ PaakCtlIndx3_D_Stat : 15|4@0+ (1,0) [0|15] "SED"  BCM
 SG_ PaakCtlIndx2_D_Stat : 3|4@0+ (1,0) [0|15] "SED"  BCM
 SG_ PaakCtlIndx1_D_Stat : 7|4@0+ (1,0) [0|15] "SED"  BCM

BO_ 1135 Battery_Traction_9: 8 BECM
 SG_ BattChrg_I2_Rq : 23|16@0+ (0.1,0) [0|6553.5] "ampere"  OBCC,SOBDM_BCCM
 SG_ BattChrg_I2_Mx : 7|16@0+ (0.1,0) [0|6553.5] "ampere"  OBCC,SOBDM_BCCM

BO_ 770 SmartChargingData_HPCM_HS1: 8 GWM
 SG_ BattTracVrtOck_B_Stat : 8|1@0+ (1,0) [0|1] "SED"  BECM
 SG_ ScMnSoc_Pc_Actl : 7|7@0+ (1,0) [0|127] "percent"  GENERIC
 SG_ CurntTrgtSoc_Pc_Rq : 23|7@0+ (1,0) [0|127] "percent"  BECM
 SG_ FstChrgBulk_T_Est : 31|10@0+ (1,0) [0|1023] "minute"  OBCC
 SG_ CurntTrgtSoc_Pc_Dsply : 15|7@0+ (1,0) [0|127] "percent"  GENERIC
 SG_ ScLocIdCurnt_No_Stat : 37|3@0+ (1,0) [0|7] "unitless"  GENERIC
 SG_ ScEnbl_B_Stat : 0|1@0+ (1,0) [0|1] "SED"  GENERIC

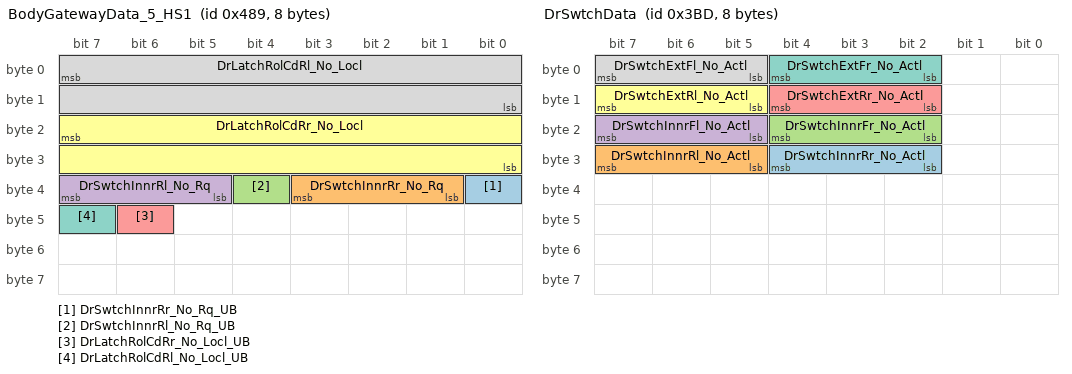
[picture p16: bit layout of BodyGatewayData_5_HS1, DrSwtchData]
BO_ 1161 BodyGatewayData_5_HS1: 8 GWM
 SG_ DrSwtchInnrRr_No_Rq_UB : 32|1@0+ (1,0) [0|1] "SED"  BCM
 SG_ DrSwtchInnrRr_No_Rq : 35|3@0+ (1,0) [0|7] "unitless"  BCM
 SG_ DrSwtchInnrRl_No_Rq_UB : 36|1@0+ (1,0) [0|1] "SED"  BCM
 SG_ DrSwtchInnrRl_No_Rq : 39|3@0+ (1,0) [0|7] "unitless"  BCM
 SG_ DrLatchRolCdRr_No_Locl_UB : 46|1@0+ (1,0) [0|1] "SED"  BCM
 SG_ DrLatchRolCdRr_No_Locl : 23|16@0+ (1,0) [0|65535] "unitless"  BCM
 SG_ DrLatchRolCdRl_No_Locl_UB : 47|1@0+ (1,0) [0|1] "SED"  BCM
 SG_ DrLatchRolCdRl_No_Locl : 7|16@0+ (1,0) [0|65535] "unitless"  BCM

BO_ 960 DrLatchRolCdData: 8 BCM
 SG_ DrLatchRolCdRr_No_Actl : 55|16@0+ (1,0) [0|65535] "unitless"  GWM
 SG_ DrLatchRolCdRl_No_Actl : 39|16@0+ (1,0) [0|65535] "unitless"  GWM
 SG_ DrLatchRolCdFr_No_Actl : 23|16@0+ (1,0) [0|65535] "unitless"  GWM
 SG_ DrLatchRolCdFl_No_Actl : 7|16@0+ (1,0) [0|65535] "unitless"  GWM

BO_ 957 DrSwtchData: 8 BCM
 SG_ DrSwtchInnrRr_No_Actl : 28|3@0+ (1,0) [0|7] "unitless"  GWM
 SG_ DrSwtchInnrRl_No_Actl : 31|3@0+ (1,0) [0|7] "unitless"  GWM
 SG_ DrSwtchInnrFr_No_Actl : 20|3@0+ (1,0) [0|7] "unitless"  GWM
 SG_ DrSwtchInnrFl_No_Actl : 23|3@0+ (1,0) [0|7] "unitless"  GWM
 SG_ DrSwtchExtRr_No_Actl : 12|3@0+ (1,0) [0|7] "unitless"  GWM
 SG_ DrSwtchExtRl_No_Actl : 15|3@0+ (1,0) [0|7] "unitless"  GWM
 SG_ DrSwtchExtFr_No_Actl : 4|3@0+ (1,0) [0|7] "unitless"  GWM
 SG_ DrSwtchExtFl_No_Actl : 7|3@0+ (1,0) [0|7] "unitless"  GWM

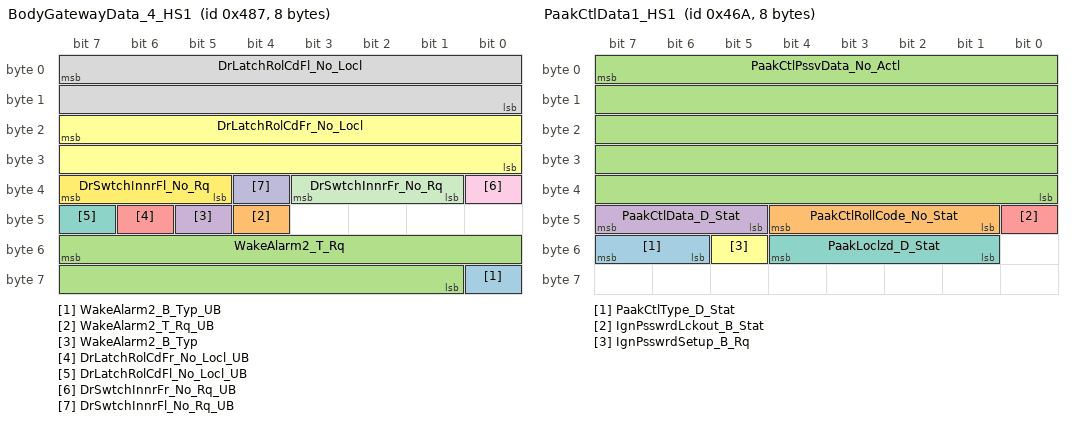
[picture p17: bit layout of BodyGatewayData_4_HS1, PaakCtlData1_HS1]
BO_ 1159 BodyGatewayData_4_HS1: 8 GWM
 SG_ WakeAlarm2_B_Typ_UB : 56|1@0+ (1,0) [0|1] "SED"  BCM
 SG_ WakeAlarm2_T_Rq_UB : 44|1@0+ (1,0) [0|1] "SED"  BCM
 SG_ WakeAlarm2_T_Rq : 55|15@0+ (1,0) [0|32767] "minute"  BCM
 SG_ WakeAlarm2_B_Typ : 45|1@0+ (1,0) [0|1] "SED"  BCM
 SG_ DrLatchRolCdFr_No_Locl_UB : 46|1@0+ (1,0) [0|1] "SED"  BCM
 SG_ DrLatchRolCdFr_No_Locl : 23|16@0+ (1,0) [0|65535] "unitless"  BCM
 SG_ DrLatchRolCdFl_No_Locl_UB : 47|1@0+ (1,0) [0|1] "SED"  BCM
 SG_ DrLatchRolCdFl_No_Locl : 7|16@0+ (1,0) [0|65535] "unitless"  BCM
 SG_ DrSwtchInnrFr_No_Rq_UB : 32|1@0+ (1,0) [0|1] "SED"  BCM
 SG_ DrSwtchInnrFl_No_Rq_UB : 36|1@0+ (1,0) [0|1] "SED"  BCM
 SG_ DrSwtchInnrFr_No_Rq : 35|3@0+ (1,0) [0|7] "unitless"  BCM
 SG_ DrSwtchInnrFl_No_Rq : 39|3@0+ (1,0) [0|7] "unitless"  BCM

BO_ 72 Global_PATS_Target2: 8 GWM
 SG_ immoTarget2Status : 7|3@0+ (1,0) [0|7] "SED"  BCM,GWM
 SG_ immoTarget2Data : 15|40@0+ (1,0) [0|1099511627775] "Encrypted"  BCM,GWM
 SG_ immoTarget2Cmd : 4|3@0+ (1,0) [0|7] "SED"  BCM,GWM

BO_ 2611175634 PARSEDPhysDCACAtoGWM_ECG: 8 DCACA_HEV
 SG_ PARSEDPhysDCACAtoGWM_ECG : 7|29@0+ (1,0) [0|536870911] "Unitless"  GWM

BO_ 2611169496 PARSEDPhysGWM_ECGtoDCACA: 8 GWM
 SG_ PARSEDPhysGWM_ECGtoDCACA : 7|29@0+ (1,0) [0|536870911] "unitless"  DCACA_GAS,DCACA_HEV

BO_ 2612224210 PARSEDPushDCACAtoGWM_ECG: 8 DCACA_HEV
 SG_ PARSEDPushDCACAtoGWM_ECG : 7|29@0+ (1,0) [0|536870911] "unitless"  GWM

BO_ 2612218072 PARSEDPushFcGWM_ECGtoDCACA: 8 GWM
 SG_ PARSEDPushFcGWM_ECGtoDCACA : 7|29@0+ (1,0) [0|536870911] "unitless"  DCACA_GAS,DCACA_HEV

BO_ 2610127058 OTAPhysDCACAtoGWM_ECG: 8 DCACA_HEV
 SG_ OTAPhysDCACAtoGWM_ECG : 7|29@0+ (1,0) [0|536870911] "unitless"  GWM

BO_ 2610120920 OTAPhysGWM_ECGtoDCACA: 8 GWM
 SG_ OTAPhysGWM_ECGtoDCACA : 7|29@0+ (1,0) [0|536870911] "unitless"  DCACA_GAS,DCACA_HEV

BO_ 1130 PaakCtlData1_HS1: 8 GWM
 SG_ PaakCtlType_D_Stat : 55|2@0+ (1,0) [0|3] "SED"  BCM
 SG_ PaakCtlRollCode_No_Stat : 44|4@0+ (1,0) [0|15] "unitless"  BCM
 SG_ PaakCtlPssvData_No_Actl : 7|40@0+ (1,0) [0|1099511627775] "unitless"  BCM
 SG_ PaakCtlData_D_Stat : 47|3@0+ (1,0) [0|7] "SED"  BCM
 SG_ IgnPsswrdLckout_B_Stat : 40|1@0+ (1,0) [0|1] "SED"  GENERIC
 SG_ IgnPsswrdSetup_B_Rq : 53|1@0+ (1,0) [0|1] "SED"  GENERIC
 SG_ PaakLoclzd_D_Stat : 52|4@0+ (1,0) [0|15] "SED"  BCM

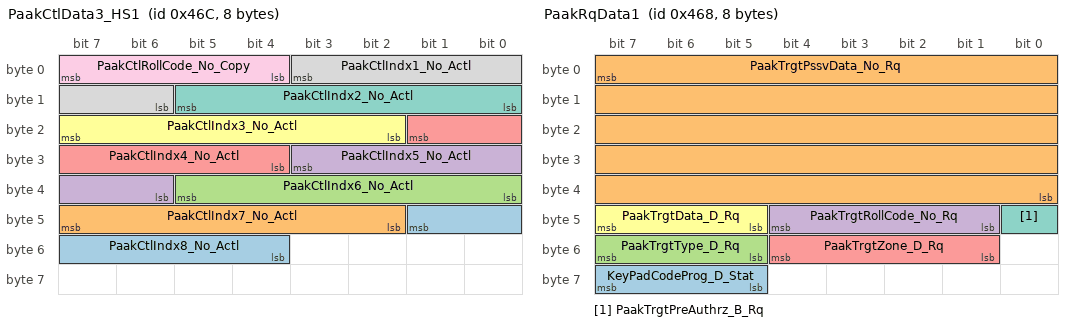
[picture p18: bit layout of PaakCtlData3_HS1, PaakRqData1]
BO_ 1132 PaakCtlData3_HS1: 8 GWM
 SG_ PaakCtlIndx8_No_Actl : 41|6@0+ (1,0) [0|63] "unitless"  BCM
 SG_ PaakCtlIndx7_No_Actl : 47|6@0+ (1,0) [0|63] "unitless"  BCM
 SG_ PaakCtlIndx6_No_Actl : 37|6@0+ (1,0) [0|63] "unitless"  BCM
 SG_ PaakCtlIndx5_No_Actl : 27|6@0+ (1,0) [0|63] "unitless"  BCM
 SG_ PaakCtlIndx4_No_Actl : 17|6@0+ (1,0) [0|63] "unitless"  BCM
 SG_ PaakCtlIndx3_No_Actl : 23|6@0+ (1,0) [0|63] "unitless"  BCM
 SG_ PaakCtlIndx2_No_Actl : 13|6@0+ (1,0) [0|63] "unitless"  BCM
 SG_ PaakCtlIndx1_No_Actl : 3|6@0+ (1,0) [0|63] "unitless"  BCM
 SG_ PaakCtlRollCode_No_Copy : 7|4@0+ (1,0) [0|15] "unitless"  BCM

BO_ 1129 PaakRqData2: 8 BCM
 SG_ PaaKMyKeyChng_D_Stat : 55|2@0+ (1,0) [0|3] "SED"  GWM
 SG_ PaaKMyKeyChng_No_Actl : 53|6@0+ (1,0) [0|63] "unitless"  GWM
 SG_ PaakAddEraseIndx_No_Actl : 45|6@0+ (1,0) [0|63] "unitless"  GWM
 SG_ PaakAddErase_D_Stat : 47|2@0+ (1,0) [0|3] "SED"  GWM
 SG_ PaakTrgtActvData_No_Rq : 7|40@0+ (1,0) [0|1099511627775] "unitless"  GWM

BO_ 1131 PaakCtlData2_HS1: 8 GWM
 SG_ KeyPadCodeProg_D_Rq : 50|3@0+ (1,0) [0|7] "SED"  BCM
 SG_ PaakCnnct_D_Stat : 52|2@0+ (1,0) [0|3] "SED"  GENERIC
 SG_ PaakCtlActv_No_Actl : 42|6@0+ (1,0) [0|63] "unitless"  BCM
 SG_ PaakCtlActv_D_Rq : 47|5@0+ (1,0) [0|31] "SED"  BCM
 SG_ PaakCtlActvData_No_Actl : 7|40@0+ (1,0) [0|1099511627775] "unitless"  BCM

BO_ 1128 PaakRqData1: 8 BCM
 SG_ KeyPadCodeProg_D_Stat : 63|3@0+ (1,0) [0|7] "SED"  GWM
 SG_ PaakTrgtPssvData_No_Rq : 7|40@0+ (1,0) [0|1099511627775] "unitless"  GWM
 SG_ PaakTrgtType_D_Rq : 55|3@0+ (1,0) [0|7] "SED"  GWM
 SG_ PaakTrgtRollCode_No_Rq : 44|4@0+ (1,0) [0|15] "unitless"  GWM
 SG_ PaakTrgtZone_D_Rq : 52|4@0+ (1,0) [0|15] "SED"  GWM
 SG_ PaakTrgtData_D_Rq : 47|3@0+ (1,0) [0|7] "SED"  GWM
 SG_ PaakTrgtPreAuthrz_B_Rq : 40|1@0+ (1,0) [0|1] "SED"  GWM

BO_ 123 Battery_Traction_2: 8 BECM
 SG_ BattTrac_U2_Actl : 21|12@0+ (0.5,0) [0|2046.5] "volt"  OBCC,SOBDM_BCCM,SOBDMB_AWDC,GWM,DCDC_HEV,DCMR_EAWD
 SG_ BattTrac_I2_Actl : 7|18@0+ (0.05,-6553.52) [-6553.52|6553.53] "ampere"  OBCC,SOBDM_BCCM,GWM

BO_ 2612070616 PARSEDPushFcGWM_ECGtoBCMC: 8 GWM
 SG_ PARSEDPushFcGWM_BCMC : 7|29@0+ (1,0) [0|536870911] "unitless"  BCMC_CPDB

BO_ 2612224077 PARSEDPushOBCCtoGWM_ECG: 8 OBCC
 SG_ PARSEDPushOBCCtoGWM_ECG : 7|29@0+ (1,0) [0|536870911] "unitless"  GWM

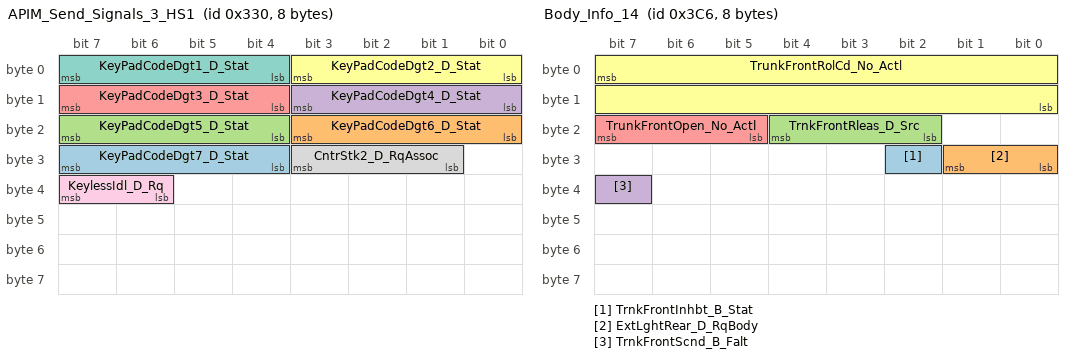
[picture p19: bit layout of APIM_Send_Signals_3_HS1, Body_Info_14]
BO_ 816 APIM_Send_Signals_3_HS1: 8 GWM
 SG_ KeyPadCodeDgt7_D_Stat : 31|4@0+ (1,0) [0|15] "SED"  BCM
 SG_ KeyPadCodeDgt6_D_Stat : 19|4@0+ (1,0) [0|15] "SED"  BCM
 SG_ KeyPadCodeDgt5_D_Stat : 23|4@0+ (1,0) [0|15] "SED"  BCM
 SG_ KeyPadCodeDgt4_D_Stat : 11|4@0+ (1,0) [0|15] "SED"  BCM
 SG_ KeyPadCodeDgt3_D_Stat : 15|4@0+ (1,0) [0|15] "SED"  BCM
 SG_ KeyPadCodeDgt2_D_Stat : 3|4@0+ (1,0) [0|15] "SED"  BCM
 SG_ KeyPadCodeDgt1_D_Stat : 7|4@0+ (1,0) [0|15] "SED"  BCM
 SG_ CntrStk2_D_RqAssoc : 27|3@0+ (1,0) [0|7] "SED"  BCM
 SG_ KeylessIdl_D_Rq : 39|2@0+ (1,0) [0|3] "SED"  BCM

BO_ 2611175501 PARSEDPhysOBCCtoGWM_ECG: 8 OBCC
 SG_ PARSEDPhysOBCCtoGWM_ECG : 7|29@0+ (1,0) [0|536870911] "Unitless"  GWM

BO_ 2611033304 PARSEDPhysGWM_ECGtoOBCC: 8 GWM
 SG_ PARSEDPhysGWM_ECGtoOBCC : 7|29@0+ (1,0) [0|536870911] "unitless"  OBCC

BO_ 2612066520 PARSEDPushFcGWM_ECGtoPACM: 8 GWM
 SG_ PARSEDPushFcGWM_ECGtoPACM : 7|29@0+ (1,0) [0|536870911] "unitless"  PACM

BO_ 2612081880 PARSEDPushFcGWM_ECGtoOBCC: 8 GWM
 SG_ PARSEDPushFcGWM_ECGtoOBCC : 7|29@0+ (1,0) [0|536870911] "unitless"  OBCC

BO_ 879 PowerDistData_3: 8 BCMC_CPDB
 SG_ WndwRearHeat_I_Actl : 7|11@0+ (0.1,0) [0|204.6] "ampere"  GWM
 SG_ WndwRearHeat_D_Stat : 12|3@0+ (1,0) [0|7] "SED"  GWM

BO_ 966 Body_Info_14: 8 BCM
 SG_ TrnkFrontInhbt_B_Stat : 26|1@0+ (1,0) [0|1] "SED"  GWM
 SG_ ExtLghtRear_D_RqBody : 25|2@0- (1,0) [0|3] "SED"  GWM
 SG_ TrnkFrontRleas_D_Src : 20|3@0+ (1,0) [0|7] "SED"  GWM
 SG_ TrnkFrontScnd_B_Falt : 39|1@0+ (1,0) [0|1] "SED"  GWM
 SG_ TrunkFrontOpen_No_Actl : 23|3@0+ (1,0) [0|7] "unitless"  FHCM,GWM
 SG_ TrunkFrontRolCd_No_Actl : 7|16@0+ (1,0) [0|65535] "unitless"  FHCM,GWM

BO_TX_BU_ 72 : DCMR_EAWD,SOBDMB_AWDC,GWM;
BO_TX_BU_ 2611175634 : DCACA_GAS,DCACA_HEV;
BO_TX_BU_ 2612224210 : DCACA_GAS,DCACA_HEV;
BO_TX_BU_ 2610127058 : DCACA_GAS,DCACA_HEV;
CM_ SG_ 931 CrnkInhbt_No_Cs "Signal not transmitted on gas and HEV variants.";
CM_ SG_ 931 CrnkInhbt_No_Cnt "Signal not transmitted on gas and HEV variants.";
CM_ SG_ 563 NtfyDrvTrgtDist_L2_Rq "Object.SetTripRangeAlert_Rq
This signal is meant to provide the customer settings for the target distance remote notification";
CM_ SG_ 1130 PaakCtlPssvData_No_Actl "Not transmitted on all vehicle variants";
CM_ SG_ 1129 PaakTrgtActvData_No_Rq "Not transmitted on all vehicle variants";
CM_ SG_ 1131 PaakCtlActvData_No_Actl "Not transmitted on all vehicle variants";
CM_ SG_ 1128 PaakTrgtPssvData_No_Rq "Not transmitted on all vehicle variants";
BA_DEF_ BO_  "FrameRouting" STRING ;
BA_DEF_ BO_  "FrameGatewayNetwork" STRING ;
BA_DEF_ BO_  "NetworkInitialization" ENUM  "No","Yes";
BA_DEF_ BO_  "FrameGatewayId" HEX 0 1407;
BA_DEF_ BO_  "EventRateOfChange" INT 10 10000;
BA_DEF_ BO_  "GenMsgStartDelayTime" INT 0 10000;
BA_DEF_ BO_  "GenMsgNrOfRepetition" INT 0 100;
BA_DEF_ BO_  "GenMsgDelayTime" INT 0 1000;
BA_DEF_ BO_  "GenMsgCycleTime" INT 0 100000;
BA_DEF_ BO_  "GenMsgSendType" ENUM  "FixedPeriodic","Event","EnabledPeriodic","NotUsed","NotUsed","EventPeriodic","NotUsed","NotUsed","NoMsgSendType";
BA_DEF_ SG_  "U_CD764_MY2022_Tx" ENUM  "No","Yes";
BA_DEF_ SG_  "U_U55X_MY2022_Tx" ENUM  "No","Yes";
BA_DEF_ SG_  "U_CD542_MY2021_Tx" ENUM  "No","Yes";
BA_DEF_ SG_  "ECGUsedTxSignal" ENUM  "No","Yes";
BA_DEF_ SG_  "U_T6_MCA_MY2020_Tx" ENUM  "No","Yes";
BA_DEF_ SG_  "U_P702_MY2021_Tx" ENUM  "No","Yes";
BA_DEF_ SG_  "U_CX727_MY2021_Tx" ENUM  "No","Yes";
BA_DEF_ SG_  "U_CD764_MY2022_Rx" ENUM  "No","Yes";
BA_DEF_ SG_  "U_U55X_MY2022_Rx" ENUM  "No","Yes";
BA_DEF_ SG_  "U_CD542_MY2021_Rx" ENUM  "No","Yes";
BA_DEF_ SG_  "ECGUsedRxSignal" ENUM  "No","Yes";
BA_DEF_ SG_  "U_T6_MCA_MY2020_Rx" ENUM  "No","Yes";
BA_DEF_ SG_  "U_P702_MY2021_Rx" ENUM  "No","Yes";
BA_DEF_ SG_  "U_CX727_MY2021_Rx" ENUM  "No","Yes";
BA_DEF_ SG_  "GenSigStartValue" HEX 0 268435455;
BA_DEF_ SG_  "MetaData" ENUM  "No","Yes";
BA_DEF_ SG_  "ContentDependant" ENUM  "No","Yes";
BA_DEF_ SG_  "GenSigStartValueInteger" INT 0 1000000000;
BA_DEF_ SG_  "UsedOnPgmDBC" ENUM  "No","Yes";
BA_DEF_ SG_  "WakeupSignal" ENUM  "No","Yes";
BA_DEF_ SG_  "GenSigInactiveValue" INT 0 100000;
BA_DEF_ SG_  "GenSigSendType" ENUM  "Cyclic","OnWrite","vector_leerstring","OnChange","vector_leerstring","IfActive","vector_leerstring","NoSigSendType";
BA_DEF_ BO_  "OvtpPushApplication" ENUM  "FALSE","TRUE";
BA_DEF_ BO_  "SCP_FreshnessValueLength" INT 0 512;
BA_DEF_ BO_  "SCP_FreshnessValueTxLength" INT 0 512;
BA_DEF_ BO_  "SCP_AuthInfoTxLength" INT 0 512;
BA_DEF_ BO_  "GenMsgRoutingTimeoutTime" INT 0 5000;
BA_DEF_ BO_  "MessageGateway" ENUM  "No","Yes";
BA_DEF_ BO_  "NmAsrMessage" ENUM  "No","Yes";
BA_DEF_ BO_  "TpApplType" STRING ;
BA_DEF_ BO_  "DiagState" ENUM  "No","Yes";
BA_DEF_ BO_  "TpTxIndex" INT 0 536870911;
BA_DEF_ BO_  "DiagRequest" ENUM  "No","Yes";
BA_DEF_ BO_  "DiagResponse" ENUM  "No","Yes";
BA_DEF_ BO_  "GenMsgILSupport" ENUM  "No","Yes";
BA_DEF_DEF_  "FrameRouting" "";
BA_DEF_DEF_  "FrameGatewayNetwork" "NONE";
BA_DEF_DEF_  "NetworkInitialization" "Yes";
BA_DEF_DEF_  "FrameGatewayId" 0;
BA_DEF_DEF_  "EventRateOfChange" 10000;
BA_DEF_DEF_  "GenMsgStartDelayTime" 0;
BA_DEF_DEF_  "GenMsgNrOfRepetition" 1;
BA_DEF_DEF_  "GenMsgDelayTime" 20;
BA_DEF_DEF_  "GenMsgCycleTime" 0;
BA_DEF_DEF_  "GenMsgSendType" "NoMsgSendType";
BA_DEF_DEF_  "U_CD764_MY2022_Tx" "No";
BA_DEF_DEF_  "U_U55X_MY2022_Tx" "No";
BA_DEF_DEF_  "U_CD542_MY2021_Tx" "No";
BA_DEF_DEF_  "ECGUsedTxSignal" "No";
BA_DEF_DEF_  "U_T6_MCA_MY2020_Tx" "No";
BA_DEF_DEF_  "U_P702_MY2021_Tx" "No";
BA_DEF_DEF_  "U_CX727_MY2021_Tx" "No";
BA_DEF_DEF_  "U_CD764_MY2022_Rx" "No";
BA_DEF_DEF_  "U_U55X_MY2022_Rx" "No";
BA_DEF_DEF_  "U_CD542_MY2021_Rx" "No";
BA_DEF_DEF_  "ECGUsedRxSignal" "No";
BA_DEF_DEF_  "U_T6_MCA_MY2020_Rx" "No";
BA_DEF_DEF_  "U_P702_MY2021_Rx" "No";
BA_DEF_DEF_  "U_CX727_MY2021_Rx" "No";
BA_DEF_DEF_  "GenSigStartValue" 0;
BA_DEF_DEF_  "MetaData" "No";
BA_DEF_DEF_  "ContentDependant" "No";
BA_DEF_DEF_  "GenSigStartValueInteger" 0;
BA_DEF_DEF_  "UsedOnPgmDBC" "Yes";
BA_DEF_DEF_  "WakeupSignal" "No";
BA_DEF_DEF_  "GenSigInactiveValue" 0;
BA_DEF_DEF_  "GenSigSendType" "NoSigSendType";
BA_DEF_DEF_  "OvtpPushApplication" "FALSE";
BA_DEF_DEF_  "SCP_FreshnessValueLength" 64;
BA_DEF_DEF_  "SCP_FreshnessValueTxLength" 11;
BA_DEF_DEF_  "SCP_AuthInfoTxLength" 53;
BA_DEF_DEF_  "GenMsgRoutingTimeoutTime" 0;
BA_DEF_DEF_  "MessageGateway" "No";
BA_DEF_DEF_  "NmAsrMessage" "No";
BA_DEF_DEF_  "TpApplType" "";
BA_DEF_DEF_  "DiagState" "No";
BA_DEF_DEF_  "TpTxIndex" 0;
BA_DEF_DEF_  "DiagRequest" "No";
BA_DEF_DEF_  "DiagResponse" "No";
BA_DEF_DEF_  "GenMsgILSupport" "Yes";
BA_ "FrameRouting" BO_ 533 "HS3_CAN,0x215;";
BA_ "FrameGatewayNetwork" BO_ 533 "HS3_CAN";
BA_ "FrameGatewayId" BO_ 533 533;
BA_ "FrameRouting" BO_ 1012 "FD1_CAN,0x3F4;";
BA_ "FrameGatewayNetwork" BO_ 1012 "FD1_CAN";
BA_ "FrameGatewayId" BO_ 1012 1012;
BA_ "NetworkInitialization" BO_ 1711 0;
BA_ "GenMsgSendType" BO_ 1711 1;
BA_ "TpApplType" BO_ 1711 "DiagUUDTResponse";
BA_ "GenMsgILSupport" BO_ 1711 0;
BA_ "NetworkInitialization" BO_ 1710 0;
BA_ "GenMsgSendType" BO_ 1710 1;
BA_ "TpApplType" BO_ 1710 "DiagUUDTResponse";
BA_ "GenMsgILSupport" BO_ 1710 0;
BA_ "NetworkInitialization" BO_ 1709 0;
BA_ "GenMsgSendType" BO_ 1709 1;
BA_ "TpApplType" BO_ 1709 "DiagUUDTResponse";
BA_ "GenMsgILSupport" BO_ 1709 0;
BA_ "NetworkInitialization" BO_ 1708 0;
BA_ "GenMsgSendType" BO_ 1708 1;
BA_ "TpApplType" BO_ 1708 "DiagUUDTResponse";
BA_ "GenMsgILSupport" BO_ 1708 0;
BA_ "GenMsgCycleTime" BO_ 874 1000;
BA_ "GenMsgSendType" BO_ 874 5;
BA_ "GenMsgCycleTime" BO_ 912 1000;
BA_ "GenMsgSendType" BO_ 912 5;
BA_ "NetworkInitialization" BO_ 1920 0;
BA_ "GenMsgDelayTime" BO_ 1920 0;
BA_ "GenMsgSendType" BO_ 1920 1;
BA_ "DiagRequest" BO_ 1920 1;
BA_ "GenMsgILSupport" BO_ 1920 0;
BA_ "GenMsgCycleTime" BO_ 1176 1000;
BA_ "GenMsgSendType" BO_ 1176 0;
BA_ "GenMsgCycleTime" BO_ 1175 1000;
BA_ "GenMsgSendType" BO_ 1175 0;
BA_ "GenMsgCycleTime" BO_ 931 60;
BA_ "GenMsgSendType" BO_ 931 0;
BA_ "NetworkInitialization" BO_ 1488 0;
BA_ "GenMsgCycleTime" BO_ 1488 1000;
BA_ "GenMsgSendType" BO_ 1488 0;
BA_ "NmAsrMessage" BO_ 1488 1;
BA_ "GenMsgILSupport" BO_ 1488 0;
BA_ "NetworkInitialization" BO_ 1776 0;
BA_ "GenMsgDelayTime" BO_ 1776 0;
BA_ "GenMsgSendType" BO_ 1776 1;
BA_ "DiagRequest" BO_ 1776 1;
BA_ "GenMsgILSupport" BO_ 1776 0;
BA_ "NetworkInitialization" BO_ 1784 0;
BA_ "GenMsgDelayTime" BO_ 1784 0;
BA_ "GenMsgSendType" BO_ 1784 1;
BA_ "DiagResponse" BO_ 1784 1;
BA_ "GenMsgILSupport" BO_ 1784 0;
BA_ "GenMsgCycleTime" BO_ 1247 100;
BA_ "GenMsgSendType" BO_ 1247 5;
BA_ "GenMsgCycleTime" BO_ 1167 1000;
BA_ "GenMsgSendType" BO_ 1167 0;
BA_ "GenMsgCycleTime" BO_ 1199 1000;
BA_ "GenMsgSendType" BO_ 1199 0;
BA_ "GenMsgCycleTime" BO_ 563 1000;
BA_ "GenMsgSendType" BO_ 563 5;
BA_ "NetworkInitialization" BO_ 1705 0;
BA_ "GenMsgDelayTime" BO_ 1705 0;
BA_ "GenMsgSendType" BO_ 1705 1;
BA_ "TpApplType" BO_ 1705 "DiagUUDTResponse";
BA_ "GenMsgILSupport" BO_ 1705 0;
BA_ "NetworkInitialization" BO_ 1704 0;
BA_ "GenMsgDelayTime" BO_ 1704 0;
BA_ "GenMsgSendType" BO_ 1704 1;
BA_ "TpApplType" BO_ 1704 "DiagUUDTResponse";
BA_ "GenMsgILSupport" BO_ 1704 0;
BA_ "GenMsgCycleTime" BO_ 1174 1000;
BA_ "GenMsgSendType" BO_ 1174 0;
BA_ "GenMsgCycleTime" BO_ 1173 1000;
BA_ "GenMsgSendType" BO_ 1173 0;
BA_ "GenMsgCycleTime" BO_ 1172 1000;
BA_ "GenMsgSendType" BO_ 1172 0;
BA_ "GenMsgCycleTime" BO_ 1171 1000;
BA_ "GenMsgSendType" BO_ 1171 0;
BA_ "GenMsgCycleTime" BO_ 1170 1000;
BA_ "GenMsgSendType" BO_ 1170 0;
BA_ "GenMsgCycleTime" BO_ 1191 1000;
BA_ "GenMsgSendType" BO_ 1191 0;
BA_ "GenMsgCycleTime" BO_ 1189 1000;
BA_ "GenMsgSendType" BO_ 1189 0;
BA_ "GenMsgCycleTime" BO_ 1188 1000;
BA_ "GenMsgSendType" BO_ 1188 0;
BA_ "GenMsgCycleTime" BO_ 1187 1000;
BA_ "GenMsgSendType" BO_ 1187 0;
BA_ "GenMsgCycleTime" BO_ 1169 1000;
BA_ "GenMsgSendType" BO_ 1169 0;
BA_ "GenMsgCycleTime" BO_ 1186 1000;
BA_ "GenMsgSendType" BO_ 1186 0;
BA_ "GenMsgCycleTime" BO_ 1185 1000;
BA_ "GenMsgSendType" BO_ 1185 0;
BA_ "GenMsgCycleTime" BO_ 1184 1000;
BA_ "GenMsgSendType" BO_ 1184 0;
BA_ "GenMsgCycleTime" BO_ 1183 1000;
BA_ "GenMsgSendType" BO_ 1183 0;
BA_ "GenMsgCycleTime" BO_ 1182 1000;
BA_ "GenMsgSendType" BO_ 1182 0;
BA_ "GenMsgCycleTime" BO_ 1181 1000;
BA_ "GenMsgSendType" BO_ 1181 0;
BA_ "GenMsgCycleTime" BO_ 1180 1000;
BA_ "GenMsgSendType" BO_ 1180 0;
BA_ "GenMsgCycleTime" BO_ 1179 1000;
BA_ "GenMsgSendType" BO_ 1179 0;
BA_ "GenMsgCycleTime" BO_ 1178 1000;
BA_ "GenMsgSendType" BO_ 1178 0;
BA_ "GenMsgCycleTime" BO_ 1177 1000;
BA_ "GenMsgSendType" BO_ 1177 0;
BA_ "GenMsgCycleTime" BO_ 1168 1000;
BA_ "GenMsgSendType" BO_ 1168 0;
BA_ "GenMsgDelayTime" BO_ 1768 0;
BA_ "GenMsgSendType" BO_ 1768 1;
BA_ "DiagResponse" BO_ 1768 1;
BA_ "GenMsgILSupport" BO_ 1768 0;
BA_ "NetworkInitialization" BO_ 1760 0;
BA_ "GenMsgDelayTime" BO_ 1760 0;
BA_ "GenMsgSendType" BO_ 1760 1;
BA_ "DiagRequest" BO_ 1760 1;
BA_ "GenMsgILSupport" BO_ 1760 0;
BA_ "GenMsgDelayTime" BO_ 1807 0;
BA_ "GenMsgSendType" BO_ 1807 1;
BA_ "DiagResponse" BO_ 1807 1;
BA_ "GenMsgILSupport" BO_ 1807 0;
BA_ "NetworkInitialization" BO_ 1799 0;
BA_ "GenMsgDelayTime" BO_ 1799 0;
BA_ "GenMsgSendType" BO_ 1799 1;
BA_ "DiagRequest" BO_ 1799 1;
BA_ "GenMsgILSupport" BO_ 1799 0;
BA_ "NetworkInitialization" BO_ 2612224204 0;
BA_ "GenMsgDelayTime" BO_ 2612224204 0;
BA_ "GenMsgSendType" BO_ 2612224204 1;
BA_ "OvtpPushApplication" BO_ 2612224204 1;
BA_ "TpTxIndex" BO_ 2612224204 464728280;
BA_ "NetworkInitialization" BO_ 2611175628 0;
BA_ "GenMsgDelayTime" BO_ 2611175628 0;
BA_ "GenMsgSendType" BO_ 2611175628 1;
BA_ "TpTxIndex" BO_ 2611175628 463679704;
BA_ "NetworkInitialization" BO_ 2610114776 0;
BA_ "GenMsgDelayTime" BO_ 2610114776 0;
BA_ "GenMsgSendType" BO_ 2610114776 1;
BA_ "TpTxIndex" BO_ 2610114776 462631128;
BA_ "NetworkInitialization" BO_ 2610127052 0;
BA_ "GenMsgDelayTime" BO_ 2610127052 0;
BA_ "GenMsgSendType" BO_ 2610127052 1;
BA_ "TpTxIndex" BO_ 2610127052 462631128;
BA_ "FrameRouting" BO_ 621 "HS4_CAN,0x26D;";
BA_ "FrameGatewayNetwork" BO_ 621 "HS4_CAN";
BA_ "FrameGatewayId" BO_ 621 621;
BA_ "NetworkInitialization" BO_ 1763 0;
BA_ "GenMsgDelayTime" BO_ 1763 0;
BA_ "GenMsgSendType" BO_ 1763 1;
BA_ "DiagRequest" BO_ 1763 1;
BA_ "GenMsgILSupport" BO_ 1763 0;
BA_ "NetworkInitialization" BO_ 1771 0;
BA_ "GenMsgDelayTime" BO_ 1771 0;
BA_ "GenMsgSendType" BO_ 1771 1;
BA_ "DiagResponse" BO_ 1771 1;
BA_ "GenMsgILSupport" BO_ 1771 0;
BA_ "NetworkInitialization" BO_ 1531 0;
BA_ "GenMsgCycleTime" BO_ 1531 1000;
BA_ "GenMsgSendType" BO_ 1531 0;
BA_ "NmAsrMessage" BO_ 1531 1;
BA_ "GenMsgILSupport" BO_ 1531 0;
BA_ "NetworkInitialization" BO_ 2611163352 0;
BA_ "GenMsgDelayTime" BO_ 2611163352 0;
BA_ "GenMsgSendType" BO_ 2611163352 1;
BA_ "TpTxIndex" BO_ 2611163352 463679704;
BA_ "NetworkInitialization" BO_ 2612211928 0;
BA_ "GenMsgDelayTime" BO_ 2612211928 0;
BA_ "GenMsgSendType" BO_ 2612211928 1;
BA_ "OvtpPushApplication" BO_ 2612211928 1;
BA_ "TpTxIndex" BO_ 2612211928 464728280;
BA_ "GenMsgCycleTime" BO_ 1149 1000;
BA_ "GenMsgSendType" BO_ 1149 0;
BA_ "FrameRouting" BO_ 626 "HS4_CAN,0x272;";
BA_ "FrameGatewayNetwork" BO_ 626 "HS4_CAN";
BA_ "FrameGatewayId" BO_ 626 626;
BA_ "GenMsgCycleTime" BO_ 1135 100;
BA_ "GenMsgSendType" BO_ 1135 0;
BA_ "FrameRouting" BO_ 770 "FD1_CAN,0x302;";
BA_ "FrameGatewayNetwork" BO_ 770 "FD1_CAN";
BA_ "FrameGatewayId" BO_ 770 770;
BA_ "GenMsgCycleTime" BO_ 1161 1000;
BA_ "GenMsgSendType" BO_ 1161 5;
BA_ "GenMsgCycleTime" BO_ 960 1000;
BA_ "GenMsgSendType" BO_ 960 5;
BA_ "GenMsgCycleTime" BO_ 957 1000;
BA_ "GenMsgSendType" BO_ 957 5;
BA_ "GenMsgCycleTime" BO_ 1159 1000;
BA_ "GenMsgSendType" BO_ 1159 5;
BA_ "FrameRouting" BO_ 72 "FD1_CAN,0x48;HS1_CAN,0x48";
BA_ "FrameGatewayNetwork" BO_ 72 "FD1_CAN";
BA_ "FrameGatewayId" BO_ 72 72;
BA_ "NetworkInitialization" BO_ 2611175634 0;
BA_ "GenMsgDelayTime" BO_ 2611175634 0;
BA_ "GenMsgSendType" BO_ 2611175634 1;
BA_ "TpTxIndex" BO_ 2611175634 463685848;
BA_ "NetworkInitialization" BO_ 2611169496 0;
BA_ "GenMsgDelayTime" BO_ 2611169496 0;
BA_ "GenMsgSendType" BO_ 2611169496 1;
BA_ "TpTxIndex" BO_ 2611169496 463685848;
BA_ "NetworkInitialization" BO_ 2612224210 0;
BA_ "GenMsgDelayTime" BO_ 2612224210 0;
BA_ "GenMsgSendType" BO_ 2612224210 1;
BA_ "OvtpPushApplication" BO_ 2612224210 1;
BA_ "TpTxIndex" BO_ 2612224210 464734424;
BA_ "NetworkInitialization" BO_ 2612218072 0;
BA_ "GenMsgDelayTime" BO_ 2612218072 0;
BA_ "GenMsgSendType" BO_ 2612218072 1;
BA_ "OvtpPushApplication" BO_ 2612218072 1;
BA_ "TpTxIndex" BO_ 2612218072 464734424;
BA_ "NetworkInitialization" BO_ 2610127058 0;
BA_ "GenMsgDelayTime" BO_ 2610127058 0;
BA_ "GenMsgSendType" BO_ 2610127058 1;
BA_ "TpTxIndex" BO_ 2610127058 462637272;
BA_ "NetworkInitialization" BO_ 2610120920 0;
BA_ "GenMsgDelayTime" BO_ 2610120920 0;
BA_ "GenMsgSendType" BO_ 2610120920 1;
BA_ "TpTxIndex" BO_ 2610120920 462637272;
BA_ "FrameRouting" BO_ 1130 "HS4_CAN,0x26A;";
BA_ "FrameGatewayNetwork" BO_ 1130 "HS4_CAN";
BA_ "FrameGatewayId" BO_ 1130 618;
BA_ "FrameRouting" BO_ 1132 "HS4_CAN,0x26C;";
BA_ "FrameGatewayNetwork" BO_ 1132 "HS4_CAN";
BA_ "FrameGatewayId" BO_ 1132 620;
BA_ "GenMsgCycleTime" BO_ 1129 200;
BA_ "GenMsgSendType" BO_ 1129 5;
BA_ "FrameRouting" BO_ 1131 "HS4_CAN,0x26B;";
BA_ "FrameGatewayNetwork" BO_ 1131 "HS4_CAN";
BA_ "FrameGatewayId" BO_ 1131 619;
BA_ "GenMsgCycleTime" BO_ 1128 200;
BA_ "GenMsgSendType" BO_ 1128 5;
BA_ "GenMsgDelayTime" BO_ 123 0;
BA_ "GenMsgCycleTime" BO_ 123 10;
BA_ "GenMsgSendType" BO_ 123 0;
BA_ "NetworkInitialization" BO_ 2612070616 0;
BA_ "GenMsgDelayTime" BO_ 2612070616 0;
BA_ "GenMsgSendType" BO_ 2612070616 1;
BA_ "OvtpPushApplication" BO_ 2612070616 1;
BA_ "TpTxIndex" BO_ 2612070616 464586968;
BA_ "NetworkInitialization" BO_ 2612224077 0;
BA_ "GenMsgDelayTime" BO_ 2612224077 0;
BA_ "GenMsgSendType" BO_ 2612224077 1;
BA_ "OvtpPushApplication" BO_ 2612224077 1;
BA_ "TpTxIndex" BO_ 2612224077 464598232;
BA_ "FrameRouting" BO_ 816 "HS3_CAN,0x330;";
BA_ "FrameGatewayNetwork" BO_ 816 "HS3_CAN";
BA_ "FrameGatewayId" BO_ 816 816;
BA_ "NetworkInitialization" BO_ 2611175501 0;
BA_ "GenMsgDelayTime" BO_ 2611175501 0;
BA_ "GenMsgSendType" BO_ 2611175501 1;
BA_ "TpTxIndex" BO_ 2611175501 463549656;
BA_ "NetworkInitialization" BO_ 2611033304 0;
BA_ "GenMsgDelayTime" BO_ 2611033304 0;
BA_ "GenMsgSendType" BO_ 2611033304 1;
BA_ "TpTxIndex" BO_ 2611033304 463549656;
BA_ "NetworkInitialization" BO_ 2612066520 0;
BA_ "GenMsgDelayTime" BO_ 2612066520 0;
BA_ "GenMsgSendType" BO_ 2612066520 1;
BA_ "OvtpPushApplication" BO_ 2612066520 1;
BA_ "TpTxIndex" BO_ 2612066520 464535768;
BA_ "NetworkInitialization" BO_ 2612081880 0;
BA_ "GenMsgDelayTime" BO_ 2612081880 0;
BA_ "GenMsgSendType" BO_ 2612081880 1;
BA_ "OvtpPushApplication" BO_ 2612081880 1;
BA_ "TpTxIndex" BO_ 2612081880 464598232;
BA_ "GenMsgCycleTime" BO_ 879 200;
BA_ "GenMsgSendType" BO_ 879 0;
BA_ "GenMsgCycleTime" BO_ 966 1000;
BA_ "GenMsgSendType" BO_ 966 5;
BA_ "U_CD764_MY2022_Rx" SG_ 533 PaakMyKey_D_Rq 1;
BA_ "U_U55X_MY2022_Rx" SG_ 533 PaakMyKey_D_Rq 1;
BA_ "U_CD542_MY2021_Rx" SG_ 533 PaakMyKey_D_Rq 1;
BA_ "U_T6_MCA_MY2020_Rx" SG_ 533 PaakMyKey_D_Rq 1;
BA_ "U_CX727_MY2021_Rx" SG_ 533 PaakMyKey_D_Rq 1;
BA_ "GenSigStartValue" SG_ 533 OnbChrgGoTOn_D_Rq 2;
BA_ "GenSigStartValueInteger" SG_ 533 OnbChrgGoTOn_D_Rq 2;
BA_ "GenSigStartValue" SG_ 533 OnbChrgGoTHr_T_Rq 30;
BA_ "GenSigStartValueInteger" SG_ 533 OnbChrgGoTHr_T_Rq 30;
BA_ "U_CD764_MY2022_Rx" SG_ 533 LghtAmbDrvMde_D_Rq 1;
BA_ "U_CD542_MY2021_Rx" SG_ 533 LghtAmbDrvMde_D_Rq 1;
BA_ "WakeupSignal" SG_ 533 LghtAmbDrvMde_D_Rq 1;
BA_ "GenSigStartValue" SG_ 1012 ChrgLocLongFrct_An_Sav 1048575;
BA_ "GenSigStartValueInteger" SG_ 1012 ChrgLocLongFrct_An_Sav 1048575;
BA_ "GenSigStartValue" SG_ 1012 ChrgLocLattFrct_An_Sav 1048575;
BA_ "GenSigStartValueInteger" SG_ 1012 ChrgLocLattFrct_An_Sav 1048575;
BA_ "U_CD542_MY2021_Rx" SG_ 1012 ChrgNowCurnt_B_Dsply 1;
BA_ "U_CX727_MY2021_Rx" SG_ 1012 ChrgNowCurnt_B_Dsply 1;
BA_ "U_CX727_MY2021_Tx" SG_ 1711 UUDTDCMRResponse4 1;
BA_ "GenSigSendType" SG_ 1711 UUDTDCMRResponse4 3;
BA_ "U_CX727_MY2021_Tx" SG_ 1710 UUDTDCMRResponse3 1;
BA_ "GenSigSendType" SG_ 1710 UUDTDCMRResponse3 3;
BA_ "U_CX727_MY2021_Tx" SG_ 1709 UUDTDCMRResponse2 1;
BA_ "GenSigSendType" SG_ 1709 UUDTDCMRResponse2 3;
BA_ "U_CX727_MY2021_Tx" SG_ 1708 UUDTDCMRResponse1 1;
BA_ "GenSigSendType" SG_ 1708 UUDTDCMRResponse1 3;
BA_ "U_CD764_MY2022_Tx" SG_ 874 AirCondCluOpen_D_Falt 1;
BA_ "U_U55X_MY2022_Tx" SG_ 874 AirCondCluOpen_D_Falt 1;
BA_ "U_CD542_MY2021_Tx" SG_ 874 AirCondCluOpen_D_Falt 1;
BA_ "U_T6_MCA_MY2020_Tx" SG_ 874 AirCondCluOpen_D_Falt 1;
BA_ "U_P702_MY2021_Tx" SG_ 874 AirCondCluOpen_D_Falt 1;
BA_ "GenSigSendType" SG_ 874 AirCondCluOpen_D_Falt 3;
BA_ "U_CD764_MY2022_Tx" SG_ 874 AirCondClu_D_Stat 1;
BA_ "U_U55X_MY2022_Tx" SG_ 874 AirCondClu_D_Stat 1;
BA_ "U_CD542_MY2021_Tx" SG_ 874 AirCondClu_D_Stat 1;
BA_ "U_T6_MCA_MY2020_Tx" SG_ 874 AirCondClu_D_Stat 1;
BA_ "U_P702_MY2021_Tx" SG_ 874 AirCondClu_D_Stat 1;
BA_ "GenSigSendType" SG_ 874 AirCondClu_D_Stat 3;
BA_ "U_U55X_MY2022_Tx" SG_ 874 BattTracShrtGrnd_D_Falt 1;
BA_ "U_CD542_MY2021_Tx" SG_ 874 BattTracShrtGrnd_D_Falt 1;
BA_ "U_P702_MY2021_Tx" SG_ 874 BattTracShrtGrnd_D_Falt 1;
BA_ "GenSigSendType" SG_ 874 BattTracShrtGrnd_D_Falt 3;
BA_ "U_U55X_MY2022_Tx" SG_ 874 BattTracShrtBatt_D_Falt 1;
BA_ "U_CD542_MY2021_Tx" SG_ 874 BattTracShrtBatt_D_Falt 1;
BA_ "U_P702_MY2021_Tx" SG_ 874 BattTracShrtBatt_D_Falt 1;
BA_ "GenSigSendType" SG_ 874 BattTracShrtBatt_D_Falt 3;
BA_ "U_U55X_MY2022_Tx" SG_ 874 BattTracOpnCirct_D_Falt 1;
BA_ "U_CD542_MY2021_Tx" SG_ 874 BattTracOpnCirct_D_Falt 1;
BA_ "U_P702_MY2021_Tx" SG_ 874 BattTracOpnCirct_D_Falt 1;
BA_ "GenSigSendType" SG_ 874 BattTracOpnCirct_D_Falt 3;
BA_ "U_U55X_MY2022_Tx" SG_ 874 BattTracLifeLim_D_Falt 1;
BA_ "U_CD542_MY2021_Tx" SG_ 874 BattTracLifeLim_D_Falt 1;
BA_ "U_P702_MY2021_Tx" SG_ 874 BattTracLifeLim_D_Falt 1;
BA_ "GenSigSendType" SG_ 874 BattTracLifeLim_D_Falt 3;
BA_ "U_U55X_MY2022_Tx" SG_ 874 BattChlrShrtGrnd_D_Falt 1;
BA_ "U_CD542_MY2021_Tx" SG_ 874 BattChlrShrtGrnd_D_Falt 1;
BA_ "U_P702_MY2021_Tx" SG_ 874 BattChlrShrtGrnd_D_Falt 1;
BA_ "U_CX727_MY2021_Tx" SG_ 874 BattChlrShrtGrnd_D_Falt 1;
BA_ "GenSigSendType" SG_ 874 BattChlrShrtGrnd_D_Falt 3;
BA_ "U_U55X_MY2022_Tx" SG_ 874 BattChlrShrtBatt_D_Falt 1;
BA_ "U_CD542_MY2021_Tx" SG_ 874 BattChlrShrtBatt_D_Falt 1;
BA_ "U_P702_MY2021_Tx" SG_ 874 BattChlrShrtBatt_D_Falt 1;
BA_ "U_CX727_MY2021_Tx" SG_ 874 BattChlrShrtBatt_D_Falt 1;
BA_ "GenSigSendType" SG_ 874 BattChlrShrtBatt_D_Falt 3;
BA_ "U_U55X_MY2022_Tx" SG_ 874 BattChlrOpnCirct_D_Falt 1;
BA_ "U_CD542_MY2021_Tx" SG_ 874 BattChlrOpnCirct_D_Falt 1;
BA_ "U_P702_MY2021_Tx" SG_ 874 BattChlrOpnCirct_D_Falt 1;
BA_ "U_CX727_MY2021_Tx" SG_ 874 BattChlrOpnCirct_D_Falt 1;
BA_ "GenSigSendType" SG_ 874 BattChlrOpnCirct_D_Falt 3;
BA_ "U_U55X_MY2022_Tx" SG_ 874 BattChlrLifeLim_D_Falt 1;
BA_ "U_CD542_MY2021_Tx" SG_ 874 BattChlrLifeLim_D_Falt 1;
BA_ "U_P702_MY2021_Tx" SG_ 874 BattChlrLifeLim_D_Falt 1;
BA_ "U_CX727_MY2021_Tx" SG_ 874 BattChlrLifeLim_D_Falt 1;
BA_ "GenSigSendType" SG_ 874 BattChlrLifeLim_D_Falt 3;
BA_ "U_CD764_MY2022_Tx" SG_ 874 AirCondCluLife_D_Falt 1;
BA_ "U_U55X_MY2022_Tx" SG_ 874 AirCondCluLife_D_Falt 1;
BA_ "U_CD542_MY2021_Tx" SG_ 874 AirCondCluLife_D_Falt 1;
BA_ "U_T6_MCA_MY2020_Tx" SG_ 874 AirCondCluLife_D_Falt 1;
BA_ "U_P702_MY2021_Tx" SG_ 874 AirCondCluLife_D_Falt 1;
BA_ "GenSigSendType" SG_ 874 AirCondCluLife_D_Falt 3;
BA_ "U_CD764_MY2022_Tx" SG_ 874 AirCondCluGnd_D_Falt 1;
BA_ "U_U55X_MY2022_Tx" SG_ 874 AirCondCluGnd_D_Falt 1;
BA_ "U_CD542_MY2021_Tx" SG_ 874 AirCondCluGnd_D_Falt 1;
BA_ "U_T6_MCA_MY2020_Tx" SG_ 874 AirCondCluGnd_D_Falt 1;
BA_ "U_P702_MY2021_Tx" SG_ 874 AirCondCluGnd_D_Falt 1;
BA_ "GenSigSendType" SG_ 874 AirCondCluGnd_D_Falt 3;
BA_ "U_CD764_MY2022_Tx" SG_ 874 AirCondCluBatt_D_Falt 1;
BA_ "U_U55X_MY2022_Tx" SG_ 874 AirCondCluBatt_D_Falt 1;
BA_ "U_CD542_MY2021_Tx" SG_ 874 AirCondCluBatt_D_Falt 1;
BA_ "U_T6_MCA_MY2020_Tx" SG_ 874 AirCondCluBatt_D_Falt 1;
BA_ "U_P702_MY2021_Tx" SG_ 874 AirCondCluBatt_D_Falt 1;
BA_ "GenSigSendType" SG_ 874 AirCondCluBatt_D_Falt 3;
BA_ "U_U55X_MY2022_Tx" SG_ 874 BattTracLow_D_Falt 1;
BA_ "U_CD542_MY2021_Tx" SG_ 874 BattTracLow_D_Falt 1;
BA_ "U_P702_MY2021_Tx" SG_ 874 BattTracLow_D_Falt 1;
BA_ "GenSigSendType" SG_ 874 BattTracLow_D_Falt 3;
BA_ "U_CD764_MY2022_Tx" SG_ 912 AdasRelay_B_Stat 1;
BA_ "U_U55X_MY2022_Tx" SG_ 912 AdasRelay_B_Stat 1;
BA_ "U_CD764_MY2022_Rx" SG_ 912 AdasRelay_B_Stat 1;
BA_ "U_CD542_MY2021_Rx" SG_ 912 AdasRelay_B_Stat 1;
BA_ "ECGUsedRxSignal" SG_ 912 AdasRelay_B_Stat 1;
BA_ "GenSigSendType" SG_ 912 AdasRelay_B_Stat 3;
BA_ "U_CD542_MY2021_Tx" SG_ 912 GearPrkMtr_D_Stat 1;
BA_ "U_CX727_MY2021_Tx" SG_ 912 GearPrkMtr_D_Stat 1;
BA_ "GenSigSendType" SG_ 912 GearPrkMtr_D_Stat 3;
BA_ "U_CD542_MY2021_Tx" SG_ 912 GearPrkLck_D_Stat 1;
BA_ "U_CX727_MY2021_Tx" SG_ 912 GearPrkLck_D_Stat 1;
BA_ "GenSigSendType" SG_ 912 GearPrkLck_D_Stat 3;
BA_ "GenSigSendType" SG_ 912 HeatCoreSovRear_D_Stat 3;
BA_ "U_U55X_MY2022_Tx" SG_ 912 CabnEvapSovRear_D_Stat 1;
BA_ "GenSigSendType" SG_ 912 CabnEvapSovRear_D_Stat 3;
BA_ "U_U55X_MY2022_Tx" SG_ 912 CabnEvapSovFront_D_Stat 1;
BA_ "U_CD542_MY2021_Tx" SG_ 912 CabnEvapSovFront_D_Stat 1;
BA_ "U_P702_MY2021_Tx" SG_ 912 CabnEvapSovFront_D_Stat 1;
BA_ "U_CX727_MY2021_Tx" SG_ 912 CabnEvapSovFront_D_Stat 1;
BA_ "GenSigSendType" SG_ 912 CabnEvapSovFront_D_Stat 3;
BA_ "GenSigSendType" SG_ 912 BattTracSov_D_Stat 3;
BA_ "U_U55X_MY2022_Tx" SG_ 912 BattChlrSov_D_Stat 1;
BA_ "U_CD542_MY2021_Tx" SG_ 912 BattChlrSov_D_Stat 1;
BA_ "U_P702_MY2021_Tx" SG_ 912 BattChlrSov_D_Stat 1;
BA_ "U_CX727_MY2021_Tx" SG_ 912 BattChlrSov_D_Stat 1;
BA_ "GenSigSendType" SG_ 912 BattChlrSov_D_Stat 3;
BA_ "U_U55X_MY2022_Tx" SG_ 912 BattTracClntVlv_D_Stat 1;
BA_ "U_CD542_MY2021_Tx" SG_ 912 BattTracClntVlv_D_Stat 1;
BA_ "U_P702_MY2021_Tx" SG_ 912 BattTracClntVlv_D_Stat 1;
BA_ "GenSigSendType" SG_ 912 BattTracClntVlv_D_Stat 3;
BA_ "GenSigSendType" SG_ 1920 TesterPhysicalReqSGM 3;
BA_ "U_CD542_MY2021_Tx" SG_ 1176 BattTracCell45_U_Actl 1;
BA_ "U_CX727_MY2021_Tx" SG_ 1176 BattTracCell45_U_Actl 1;
BA_ "U_U55X_MY2022_Rx" SG_ 1176 BattTracCell45_U_Actl 1;
BA_ "U_CD542_MY2021_Rx" SG_ 1176 BattTracCell45_U_Actl 1;
BA_ "ECGUsedRxSignal" SG_ 1176 BattTracCell45_U_Actl 1;
BA_ "GenSigStartValue" SG_ 1176 BattTracCell45_U_Actl 4094;
BA_ "GenSigStartValueInteger" SG_ 1176 BattTracCell45_U_Actl 4094;
BA_ "U_CD542_MY2021_Tx" SG_ 1176 BattTracCell44_U_Actl 1;
BA_ "U_CX727_MY2021_Tx" SG_ 1176 BattTracCell44_U_Actl 1;
BA_ "U_U55X_MY2022_Rx" SG_ 1176 BattTracCell44_U_Actl 1;
BA_ "U_CD542_MY2021_Rx" SG_ 1176 BattTracCell44_U_Actl 1;
BA_ "ECGUsedRxSignal" SG_ 1176 BattTracCell44_U_Actl 1;
BA_ "GenSigStartValue" SG_ 1176 BattTracCell44_U_Actl 4094;
BA_ "GenSigStartValueInteger" SG_ 1176 BattTracCell44_U_Actl 4094;
BA_ "U_CD542_MY2021_Tx" SG_ 1176 BattTracCell43_U_Actl 1;
BA_ "U_CX727_MY2021_Tx" SG_ 1176 BattTracCell43_U_Actl 1;
BA_ "U_U55X_MY2022_Rx" SG_ 1176 BattTracCell43_U_Actl 1;
BA_ "U_CD542_MY2021_Rx" SG_ 1176 BattTracCell43_U_Actl 1;
BA_ "ECGUsedRxSignal" SG_ 1176 BattTracCell43_U_Actl 1;
BA_ "GenSigStartValue" SG_ 1176 BattTracCell43_U_Actl 4094;
BA_ "GenSigStartValueInteger" SG_ 1176 BattTracCell43_U_Actl 4094;
BA_ "U_CD542_MY2021_Tx" SG_ 1176 BattTracCell42_U_Actl 1;
BA_ "U_CX727_MY2021_Tx" SG_ 1176 BattTracCell42_U_Actl 1;
BA_ "U_U55X_MY2022_Rx" SG_ 1176 BattTracCell42_U_Actl 1;
BA_ "U_CD542_MY2021_Rx" SG_ 1176 BattTracCell42_U_Actl 1;
BA_ "ECGUsedRxSignal" SG_ 1176 BattTracCell42_U_Actl 1;
BA_ "GenSigStartValue" SG_ 1176 BattTracCell42_U_Actl 4094;
BA_ "GenSigStartValueInteger" SG_ 1176 BattTracCell42_U_Actl 4094;
BA_ "U_CD542_MY2021_Tx" SG_ 1176 BattTracCell41_U_Actl 1;
BA_ "U_CX727_MY2021_Tx" SG_ 1176 BattTracCell41_U_Actl 1;
BA_ "U_U55X_MY2022_Rx" SG_ 1176 BattTracCell41_U_Actl 1;
BA_ "U_CD542_MY2021_Rx" SG_ 1176 BattTracCell41_U_Actl 1;
BA_ "ECGUsedRxSignal" SG_ 1176 BattTracCell41_U_Actl 1;
BA_ "GenSigStartValue" SG_ 1176 BattTracCell41_U_Actl 4094;
BA_ "GenSigStartValueInteger" SG_ 1176 BattTracCell41_U_Actl 4094;
BA_ "U_CD542_MY2021_Tx" SG_ 1175 BattTracCell40_U_Actl 1;
BA_ "U_CX727_MY2021_Tx" SG_ 1175 BattTracCell40_U_Actl 1;
BA_ "U_U55X_MY2022_Rx" SG_ 1175 BattTracCell40_U_Actl 1;
BA_ "U_CD542_MY2021_Rx" SG_ 1175 BattTracCell40_U_Actl 1;
BA_ "ECGUsedRxSignal" SG_ 1175 BattTracCell40_U_Actl 1;
BA_ "GenSigStartValue" SG_ 1175 BattTracCell40_U_Actl 4094;
BA_ "GenSigStartValueInteger" SG_ 1175 BattTracCell40_U_Actl 4094;
BA_ "U_CD542_MY2021_Tx" SG_ 1175 BattTracCell39_U_Actl 1;
BA_ "U_CX727_MY2021_Tx" SG_ 1175 BattTracCell39_U_Actl 1;
BA_ "U_U55X_MY2022_Rx" SG_ 1175 BattTracCell39_U_Actl 1;
BA_ "U_CD542_MY2021_Rx" SG_ 1175 BattTracCell39_U_Actl 1;
BA_ "ECGUsedRxSignal" SG_ 1175 BattTracCell39_U_Actl 1;
BA_ "GenSigStartValue" SG_ 1175 BattTracCell39_U_Actl 4094;
BA_ "GenSigStartValueInteger" SG_ 1175 BattTracCell39_U_Actl 4094;
BA_ "U_CD542_MY2021_Tx" SG_ 1175 BattTracCell38_U_Actl 1;
BA_ "U_CX727_MY2021_Tx" SG_ 1175 BattTracCell38_U_Actl 1;
BA_ "U_U55X_MY2022_Rx" SG_ 1175 BattTracCell38_U_Actl 1;
BA_ "U_CD542_MY2021_Rx" SG_ 1175 BattTracCell38_U_Actl 1;
BA_ "ECGUsedRxSignal" SG_ 1175 BattTracCell38_U_Actl 1;
BA_ "GenSigStartValue" SG_ 1175 BattTracCell38_U_Actl 4094;
BA_ "GenSigStartValueInteger" SG_ 1175 BattTracCell38_U_Actl 4094;
BA_ "U_CD542_MY2021_Tx" SG_ 1175 BattTracCell37_U_Actl 1;
BA_ "U_CX727_MY2021_Tx" SG_ 1175 BattTracCell37_U_Actl 1;
BA_ "U_U55X_MY2022_Rx" SG_ 1175 BattTracCell37_U_Actl 1;
BA_ "U_CD542_MY2021_Rx" SG_ 1175 BattTracCell37_U_Actl 1;
BA_ "ECGUsedRxSignal" SG_ 1175 BattTracCell37_U_Actl 1;
BA_ "GenSigStartValue" SG_ 1175 BattTracCell37_U_Actl 4094;
BA_ "GenSigStartValueInteger" SG_ 1175 BattTracCell37_U_Actl 4094;
BA_ "U_CD542_MY2021_Tx" SG_ 1175 BattTracCell36_U_Actl 1;
BA_ "U_CX727_MY2021_Tx" SG_ 1175 BattTracCell36_U_Actl 1;
BA_ "U_U55X_MY2022_Rx" SG_ 1175 BattTracCell36_U_Actl 1;
BA_ "U_CD542_MY2021_Rx" SG_ 1175 BattTracCell36_U_Actl 1;
BA_ "ECGUsedRxSignal" SG_ 1175 BattTracCell36_U_Actl 1;
BA_ "GenSigStartValue" SG_ 1175 BattTracCell36_U_Actl 4094;
BA_ "GenSigStartValueInteger" SG_ 1175 BattTracCell36_U_Actl 4094;
BA_ "U_CD764_MY2022_Tx" SG_ 931 VehOnSrc_D_Stat 1;
BA_ "U_U55X_MY2022_Tx" SG_ 931 VehOnSrc_D_Stat 1;
BA_ "U_CD542_MY2021_Tx" SG_ 931 VehOnSrc_D_Stat 1;
BA_ "U_T6_MCA_MY2020_Tx" SG_ 931 VehOnSrc_D_Stat 1;
BA_ "U_P702_MY2021_Tx" SG_ 931 VehOnSrc_D_Stat 1;
BA_ "U_CD764_MY2022_Rx" SG_ 931 VehOnSrc_D_Stat 1;
BA_ "U_U55X_MY2022_Rx" SG_ 931 VehOnSrc_D_Stat 1;
BA_ "U_T6_MCA_MY2020_Rx" SG_ 931 VehOnSrc_D_Stat 1;
BA_ "U_CD764_MY2022_Tx" SG_ 931 StrtrMtrCtlDStat_No_Cs 1;
BA_ "U_U55X_MY2022_Tx" SG_ 931 StrtrMtrCtlDStat_No_Cs 1;
BA_ "U_CD542_MY2021_Tx" SG_ 931 StrtrMtrCtlDStat_No_Cs 1;
BA_ "U_T6_MCA_MY2020_Tx" SG_ 931 StrtrMtrCtlDStat_No_Cs 1;
BA_ "U_P702_MY2021_Tx" SG_ 931 StrtrMtrCtlDStat_No_Cs 1;
BA_ "MetaData" SG_ 931 StrtrMtrCtlDStat_No_Cs 1;
BA_ "U_CD764_MY2022_Tx" SG_ 931 EngStrtActv_B_Stat 1;
BA_ "U_U55X_MY2022_Tx" SG_ 931 EngStrtActv_B_Stat 1;
BA_ "U_CD542_MY2021_Tx" SG_ 931 EngStrtActv_B_Stat 1;
BA_ "U_T6_MCA_MY2020_Tx" SG_ 931 EngStrtActv_B_Stat 1;
BA_ "U_P702_MY2021_Tx" SG_ 931 EngStrtActv_B_Stat 1;
BA_ "U_CD764_MY2022_Tx" SG_ 931 EngStrt_B_Rq 1;
BA_ "U_U55X_MY2022_Tx" SG_ 931 EngStrt_B_Rq 1;
BA_ "U_CD542_MY2021_Tx" SG_ 931 EngStrt_B_Rq 1;
BA_ "U_T6_MCA_MY2020_Tx" SG_ 931 EngStrt_B_Rq 1;
BA_ "U_P702_MY2021_Tx" SG_ 931 EngStrt_B_Rq 1;
BA_ "U_CD764_MY2022_Tx" SG_ 931 DrvInCtl_B_Stat 1;
BA_ "U_U55X_MY2022_Tx" SG_ 931 DrvInCtl_B_Stat 1;
BA_ "U_CD542_MY2021_Tx" SG_ 931 DrvInCtl_B_Stat 1;
BA_ "U_T6_MCA_MY2020_Tx" SG_ 931 DrvInCtl_B_Stat 1;
BA_ "U_P702_MY2021_Tx" SG_ 931 DrvInCtl_B_Stat 1;
BA_ "U_CD764_MY2022_Tx" SG_ 931 PtWakeReas_D_Stat 1;
BA_ "U_U55X_MY2022_Tx" SG_ 931 PtWakeReas_D_Stat 1;
BA_ "U_CD542_MY2021_Tx" SG_ 931 PtWakeReas_D_Stat 1;
BA_ "U_T6_MCA_MY2020_Tx" SG_ 931 PtWakeReas_D_Stat 1;
BA_ "U_P702_MY2021_Tx" SG_ 931 PtWakeReas_D_Stat 1;
BA_ "GenSigSendType" SG_ 931 PtWakeReas_D_Stat 3;
BA_ "U_CD764_MY2022_Tx" SG_ 931 CrnkInhbt_No_Cs 1;
BA_ "U_U55X_MY2022_Tx" SG_ 931 CrnkInhbt_No_Cs 1;
BA_ "U_CD542_MY2021_Tx" SG_ 931 CrnkInhbt_No_Cs 1;
BA_ "U_T6_MCA_MY2020_Tx" SG_ 931 CrnkInhbt_No_Cs 1;
BA_ "U_P702_MY2021_Tx" SG_ 931 CrnkInhbt_No_Cs 1;
BA_ "U_CX727_MY2021_Tx" SG_ 931 CrnkInhbt_No_Cs 1;
BA_ "MetaData" SG_ 931 CrnkInhbt_No_Cs 1;
BA_ "ContentDependant" SG_ 931 CrnkInhbt_No_Cs 1;
BA_ "U_CD764_MY2022_Tx" SG_ 931 CrnkInhbt_No_Cnt 1;
BA_ "U_U55X_MY2022_Tx" SG_ 931 CrnkInhbt_No_Cnt 1;
BA_ "U_CD542_MY2021_Tx" SG_ 931 CrnkInhbt_No_Cnt 1;
BA_ "U_T6_MCA_MY2020_Tx" SG_ 931 CrnkInhbt_No_Cnt 1;
BA_ "U_P702_MY2021_Tx" SG_ 931 CrnkInhbt_No_Cnt 1;
BA_ "U_CX727_MY2021_Tx" SG_ 931 CrnkInhbt_No_Cnt 1;
BA_ "MetaData" SG_ 931 CrnkInhbt_No_Cnt 1;
BA_ "ContentDependant" SG_ 931 CrnkInhbt_No_Cnt 1;
BA_ "U_CD764_MY2022_Tx" SG_ 931 CrnkInhbt_B_Stat 1;
BA_ "U_U55X_MY2022_Tx" SG_ 931 CrnkInhbt_B_Stat 1;
BA_ "U_CD542_MY2021_Tx" SG_ 931 CrnkInhbt_B_Stat 1;
BA_ "U_T6_MCA_MY2020_Tx" SG_ 931 CrnkInhbt_B_Stat 1;
BA_ "U_P702_MY2021_Tx" SG_ 931 CrnkInhbt_B_Stat 1;
BA_ "U_CX727_MY2021_Tx" SG_ 931 CrnkInhbt_B_Stat 1;
BA_ "GenSigStartValue" SG_ 931 CrnkInhbt_B_Stat 1;
BA_ "GenSigStartValueInteger" SG_ 931 CrnkInhbt_B_Stat 1;
BA_ "U_CD764_MY2022_Tx" SG_ 931 AdvStrt_No_Stat 1;
BA_ "U_U55X_MY2022_Tx" SG_ 931 AdvStrt_No_Stat 1;
BA_ "U_CD542_MY2021_Tx" SG_ 931 AdvStrt_No_Stat 1;
BA_ "U_T6_MCA_MY2020_Tx" SG_ 931 AdvStrt_No_Stat 1;
BA_ "U_CD764_MY2022_Tx" SG_ 931 IgnPreOffActv_B_Stat 1;
BA_ "U_U55X_MY2022_Tx" SG_ 931 IgnPreOffActv_B_Stat 1;
BA_ "U_CD542_MY2021_Tx" SG_ 931 IgnPreOffActv_B_Stat 1;
BA_ "U_T6_MCA_MY2020_Tx" SG_ 931 IgnPreOffActv_B_Stat 1;
BA_ "U_P702_MY2021_Tx" SG_ 931 IgnPreOffActv_B_Stat 1;
BA_ "U_CX727_MY2021_Tx" SG_ 931 IgnPreOffActv_B_Stat 1;
BA_ "U_CD764_MY2022_Tx" SG_ 1488 BCMC_GWOnBoardTester 1;
BA_ "U_U55X_MY2022_Tx" SG_ 1488 BCMC_GWOnBoardTester 1;
BA_ "U_CD542_MY2021_Tx" SG_ 1488 BCMC_GWOnBoardTester 1;
BA_ "U_T6_MCA_MY2020_Tx" SG_ 1488 BCMC_GWOnBoardTester 1;
BA_ "U_P702_MY2021_Tx" SG_ 1488 BCMC_GWOnBoardTester 1;
BA_ "U_CX727_MY2021_Tx" SG_ 1488 BCMC_GWOnBoardTester 1;
BA_ "GenSigStartValue" SG_ 1488 BCMC_GWOnBoardTester 255;
BA_ "ContentDependant" SG_ 1488 BCMC_GWOnBoardTester 1;
BA_ "GenSigStartValueInteger" SG_ 1488 BCMC_GWOnBoardTester 255;
BA_ "U_CD764_MY2022_Tx" SG_ 1488 BCMC_GWNMProxy 1;
BA_ "U_U55X_MY2022_Tx" SG_ 1488 BCMC_GWNMProxy 1;
BA_ "U_CD542_MY2021_Tx" SG_ 1488 BCMC_GWNMProxy 1;
BA_ "U_T6_MCA_MY2020_Tx" SG_ 1488 BCMC_GWNMProxy 1;
BA_ "U_P702_MY2021_Tx" SG_ 1488 BCMC_GWNMProxy 1;
BA_ "U_CX727_MY2021_Tx" SG_ 1488 BCMC_GWNMProxy 1;
BA_ "GenSigStartValue" SG_ 1488 BCMC_GWNMProxy 255;
BA_ "ContentDependant" SG_ 1488 BCMC_GWNMProxy 1;
BA_ "GenSigStartValueInteger" SG_ 1488 BCMC_GWNMProxy 255;
BA_ "U_CD764_MY2022_Tx" SG_ 1488 BCMC_AutoSarNMReserved4 1;
BA_ "U_U55X_MY2022_Tx" SG_ 1488 BCMC_AutoSarNMReserved4 1;
BA_ "U_CD542_MY2021_Tx" SG_ 1488 BCMC_AutoSarNMReserved4 1;
BA_ "U_T6_MCA_MY2020_Tx" SG_ 1488 BCMC_AutoSarNMReserved4 1;
BA_ "U_P702_MY2021_Tx" SG_ 1488 BCMC_AutoSarNMReserved4 1;
BA_ "U_CX727_MY2021_Tx" SG_ 1488 BCMC_AutoSarNMReserved4 1;
BA_ "GenSigStartValue" SG_ 1488 BCMC_AutoSarNMReserved4 255;
BA_ "ContentDependant" SG_ 1488 BCMC_AutoSarNMReserved4 1;
BA_ "GenSigStartValueInteger" SG_ 1488 BCMC_AutoSarNMReserved4 255;
BA_ "U_CD764_MY2022_Tx" SG_ 1488 BCMC_AutoSarNMReserved3 1;
BA_ "U_U55X_MY2022_Tx" SG_ 1488 BCMC_AutoSarNMReserved3 1;
BA_ "U_CD542_MY2021_Tx" SG_ 1488 BCMC_AutoSarNMReserved3 1;
BA_ "U_T6_MCA_MY2020_Tx" SG_ 1488 BCMC_AutoSarNMReserved3 1;
BA_ "U_P702_MY2021_Tx" SG_ 1488 BCMC_AutoSarNMReserved3 1;
BA_ "U_CX727_MY2021_Tx" SG_ 1488 BCMC_AutoSarNMReserved3 1;
BA_ "GenSigStartValue" SG_ 1488 BCMC_AutoSarNMReserved3 255;
BA_ "ContentDependant" SG_ 1488 BCMC_AutoSarNMReserved3 1;
BA_ "GenSigStartValueInteger" SG_ 1488 BCMC_AutoSarNMReserved3 255;
BA_ "U_CD764_MY2022_Tx" SG_ 1488 BCMC_AutoSarNMReserved2 1;
BA_ "U_U55X_MY2022_Tx" SG_ 1488 BCMC_AutoSarNMReserved2 1;
BA_ "U_CD542_MY2021_Tx" SG_ 1488 BCMC_AutoSarNMReserved2 1;
BA_ "U_T6_MCA_MY2020_Tx" SG_ 1488 BCMC_AutoSarNMReserved2 1;
BA_ "U_P702_MY2021_Tx" SG_ 1488 BCMC_AutoSarNMReserved2 1;
BA_ "U_CX727_MY2021_Tx" SG_ 1488 BCMC_AutoSarNMReserved2 1;
BA_ "GenSigStartValue" SG_ 1488 BCMC_AutoSarNMReserved2 255;
BA_ "ContentDependant" SG_ 1488 BCMC_AutoSarNMReserved2 1;
BA_ "GenSigStartValueInteger" SG_ 1488 BCMC_AutoSarNMReserved2 255;
BA_ "U_CD764_MY2022_Tx" SG_ 1488 BCMC_AutoSarNMReserved1 1;
BA_ "U_U55X_MY2022_Tx" SG_ 1488 BCMC_AutoSarNMReserved1 1;
BA_ "U_CD542_MY2021_Tx" SG_ 1488 BCMC_AutoSarNMReserved1 1;
BA_ "U_T6_MCA_MY2020_Tx" SG_ 1488 BCMC_AutoSarNMReserved1 1;
BA_ "U_P702_MY2021_Tx" SG_ 1488 BCMC_AutoSarNMReserved1 1;
BA_ "U_CX727_MY2021_Tx" SG_ 1488 BCMC_AutoSarNMReserved1 1;
BA_ "GenSigStartValue" SG_ 1488 BCMC_AutoSarNMReserved1 255;
BA_ "ContentDependant" SG_ 1488 BCMC_AutoSarNMReserved1 1;
BA_ "GenSigStartValueInteger" SG_ 1488 BCMC_AutoSarNMReserved1 255;
BA_ "U_CD764_MY2022_Tx" SG_ 1488 BCMC_AutoSarNMNodeId 1;
BA_ "U_U55X_MY2022_Tx" SG_ 1488 BCMC_AutoSarNMNodeId 1;
BA_ "U_CD542_MY2021_Tx" SG_ 1488 BCMC_AutoSarNMNodeId 1;
BA_ "U_T6_MCA_MY2020_Tx" SG_ 1488 BCMC_AutoSarNMNodeId 1;
BA_ "U_P702_MY2021_Tx" SG_ 1488 BCMC_AutoSarNMNodeId 1;
BA_ "U_CX727_MY2021_Tx" SG_ 1488 BCMC_AutoSarNMNodeId 1;
BA_ "GenSigStartValue" SG_ 1488 BCMC_AutoSarNMNodeId 208;
BA_ "ContentDependant" SG_ 1488 BCMC_AutoSarNMNodeId 1;
BA_ "GenSigStartValueInteger" SG_ 1488 BCMC_AutoSarNMNodeId 208;
BA_ "U_CD764_MY2022_Tx" SG_ 1488 BCMC_AutoSarNMControl 1;
BA_ "U_U55X_MY2022_Tx" SG_ 1488 BCMC_AutoSarNMControl 1;
BA_ "U_CD542_MY2021_Tx" SG_ 1488 BCMC_AutoSarNMControl 1;
BA_ "U_T6_MCA_MY2020_Tx" SG_ 1488 BCMC_AutoSarNMControl 1;
BA_ "U_P702_MY2021_Tx" SG_ 1488 BCMC_AutoSarNMControl 1;
BA_ "U_CX727_MY2021_Tx" SG_ 1488 BCMC_AutoSarNMControl 1;
BA_ "ContentDependant" SG_ 1488 BCMC_AutoSarNMControl 1;
BA_ "U_CD764_MY2022_Rx" SG_ 1776 TesterPhysicalReqBCMC_CPDB 1;
BA_ "U_U55X_MY2022_Rx" SG_ 1776 TesterPhysicalReqBCMC_CPDB 1;
BA_ "U_CD542_MY2021_Rx" SG_ 1776 TesterPhysicalReqBCMC_CPDB 1;
BA_ "U_T6_MCA_MY2020_Rx" SG_ 1776 TesterPhysicalReqBCMC_CPDB 1;
BA_ "U_P702_MY2021_Rx" SG_ 1776 TesterPhysicalReqBCMC_CPDB 1;
BA_ "U_CX727_MY2021_Rx" SG_ 1776 TesterPhysicalReqBCMC_CPDB 1;
BA_ "GenSigSendType" SG_ 1776 TesterPhysicalReqBCMC_CPDB 3;
BA_ "U_CD764_MY2022_Tx" SG_ 1784 TesterPhysicalResBCMC_CPDB 1;
BA_ "U_U55X_MY2022_Tx" SG_ 1784 TesterPhysicalResBCMC_CPDB 1;
BA_ "U_CD542_MY2021_Tx" SG_ 1784 TesterPhysicalResBCMC_CPDB 1;
BA_ "U_T6_MCA_MY2020_Tx" SG_ 1784 TesterPhysicalResBCMC_CPDB 1;
BA_ "U_P702_MY2021_Tx" SG_ 1784 TesterPhysicalResBCMC_CPDB 1;
BA_ "U_CX727_MY2021_Tx" SG_ 1784 TesterPhysicalResBCMC_CPDB 1;
BA_ "GenSigSendType" SG_ 1784 TesterPhysicalResBCMC_CPDB 3;
BA_ "GenSigSendType" SG_ 1247 TrlrBrkCtl3_B_Falt 3;
BA_ "MetaData" SG_ 1247 StopLampBRqTrlrAft_No_Cs 1;
BA_ "MetaData" SG_ 1247 StopLampBRqTrlrAft_No_Cnt 1;
BA_ "U_T6_MCA_MY2020_Tx" SG_ 1247 StopLamp_B_RqTrlrAft 1;
BA_ "GenSigSendType" SG_ 1247 StopLamp_B_RqTrlrAft 3;
BA_ "U_CD764_MY2022_Rx" SG_ 1167 PrplAxlScnd_Tq_ActlMntr 1;
BA_ "U_CD542_MY2021_Rx" SG_ 1167 PrplAxlScnd_Tq_ActlMntr 1;
BA_ "ECGUsedRxSignal" SG_ 1167 PrplAxlScnd_Tq_ActlMntr 1;
BA_ "GenSigStartValue" SG_ 1167 PrplAxlScnd_Tq_ActlMntr 32768;
BA_ "U_CD764_MY2022_Rx" SG_ 1167 Inv4TeAlrm_B_ActlMntr 1;
BA_ "U_CD542_MY2021_Rx" SG_ 1167 Inv4TeAlrm_B_ActlMntr 1;
BA_ "ECGUsedRxSignal" SG_ 1167 Inv4TeAlrm_B_ActlMntr 1;
BA_ "U_CD764_MY2022_Rx" SG_ 1167 Inv4Ain_U_ActlMntr 1;
BA_ "U_CD542_MY2021_Rx" SG_ 1167 Inv4Ain_U_ActlMntr 1;
BA_ "ECGUsedRxSignal" SG_ 1167 Inv4Ain_U_ActlMntr 1;
BA_ "U_CD764_MY2022_Rx" SG_ 1167 Inv4Ain_I_ActlMntr 1;
BA_ "U_CD542_MY2021_Rx" SG_ 1167 Inv4Ain_I_ActlMntr 1;
BA_ "ECGUsedRxSignal" SG_ 1167 Inv4Ain_I_ActlMntr 1;
BA_ "GenSigStartValue" SG_ 1167 Inv4Ain_I_ActlMntr 32766;
BA_ "U_CD764_MY2022_Rx" SG_ 1167 Inv4_Te_ActlMntr 1;
BA_ "U_CD542_MY2021_Rx" SG_ 1167 Inv4_Te_ActlMntr 1;
BA_ "ECGUsedRxSignal" SG_ 1167 Inv4_Te_ActlMntr 1;
BA_ "GenSigStartValue" SG_ 1167 Inv4_Te_ActlMntr 254;
BA_ "U_CD764_MY2022_Rx" SG_ 1199 Mtr4TeAlrm_B_ActlMntr 1;
BA_ "U_CD542_MY2021_Rx" SG_ 1199 Mtr4TeAlrm_B_ActlMntr 1;
BA_ "ECGUsedRxSignal" SG_ 1199 Mtr4TeAlrm_B_ActlMntr 1;
BA_ "U_CD764_MY2022_Rx" SG_ 1199 Mtr4Aout_W_ActlMntr 1;
BA_ "U_CD542_MY2021_Rx" SG_ 1199 Mtr4Aout_W_ActlMntr 1;
BA_ "ECGUsedRxSignal" SG_ 1199 Mtr4Aout_W_ActlMntr 1;
BA_ "GenSigStartValue" SG_ 1199 Mtr4Aout_W_ActlMntr 1023;
BA_ "U_CD764_MY2022_Rx" SG_ 1199 Mtr4Aout_Tq_ActlMntr 1;
BA_ "U_CD542_MY2021_Rx" SG_ 1199 Mtr4Aout_Tq_ActlMntr 1;
BA_ "ECGUsedRxSignal" SG_ 1199 Mtr4Aout_Tq_ActlMntr 1;
BA_ "GenSigStartValue" SG_ 1199 Mtr4Aout_Tq_ActlMntr 2047;
BA_ "U_CD764_MY2022_Rx" SG_ 1199 Mtr4_Te_ActlMntr 1;
BA_ "U_CD542_MY2021_Rx" SG_ 1199 Mtr4_Te_ActlMntr 1;
BA_ "ECGUsedRxSignal" SG_ 1199 Mtr4_Te_ActlMntr 1;
BA_ "GenSigStartValue" SG_ 1199 Mtr4_Te_ActlMntr 254;
BA_ "U_CD764_MY2022_Rx" SG_ 1199 Mtr4_D_StatMntr 1;
BA_ "U_CD542_MY2021_Rx" SG_ 1199 Mtr4_D_StatMntr 1;
BA_ "ECGUsedRxSignal" SG_ 1199 Mtr4_D_StatMntr 1;
BA_ "U_CD764_MY2022_Tx" SG_ 563 DrvBhavAudioAlrt_D_Rq 1;
BA_ "ECGUsedTxSignal" SG_ 563 DrvBhavAudioAlrt_D_Rq 1;
BA_ "GenSigSendType" SG_ 563 DrvBhavAudioAlrt_D_Rq 3;
BA_ "U_CD764_MY2022_Tx" SG_ 563 NtfyDrvTrgtDist_L2_Rq 1;
BA_ "U_CD542_MY2021_Tx" SG_ 563 NtfyDrvTrgtDist_L2_Rq 1;
BA_ "ECGUsedTxSignal" SG_ 563 NtfyDrvTrgtDist_L2_Rq 1;
BA_ "GenSigSendType" SG_ 563 NtfyDrvTrgtDist_L2_Rq 3;
BA_ "GenSigStartValue" SG_ 563 NtfyDrvTrgtDist_L2_Rq 8190;
BA_ "GenSigStartValueInteger" SG_ 563 NtfyDrvTrgtDist_L2_Rq 1;
BA_ "WakeupSignal" SG_ 563 NtfyDrvTrgtDist_L2_Rq 1;
BA_ "U_CD764_MY2022_Tx" SG_ 563 BattChrgStrtStop_D_Rq 1;
BA_ "U_CD542_MY2021_Tx" SG_ 563 BattChrgStrtStop_D_Rq 1;
BA_ "ECGUsedTxSignal" SG_ 563 BattChrgStrtStop_D_Rq 1;
BA_ "GenSigSendType" SG_ 563 BattChrgStrtStop_D_Rq 3;
BA_ "U_CD764_MY2022_Tx" SG_ 563 DrvBhavWarn_B_Rq 1;
BA_ "U_CD542_MY2021_Tx" SG_ 563 DrvBhavWarn_B_Rq 1;
BA_ "ECGUsedTxSignal" SG_ 563 DrvBhavWarn_B_Rq 1;
BA_ "GenSigSendType" SG_ 563 DrvBhavWarn_B_Rq 3;
BA_ "U_CD764_MY2022_Tx" SG_ 563 OfbChrgSetSync_D_Rq 1;
BA_ "U_CD542_MY2021_Tx" SG_ 563 OfbChrgSetSync_D_Rq 1;
BA_ "ECGUsedTxSignal" SG_ 563 OfbChrgSetSync_D_Rq 1;
BA_ "GenSigSendType" SG_ 563 OfbChrgSetSync_D_Rq 3;
BA_ "U_CD764_MY2022_Tx" SG_ 563 KeyOffPwMde_D_Stat 1;
BA_ "U_CD542_MY2021_Tx" SG_ 563 KeyOffPwMde_D_Stat 1;
BA_ "ECGUsedTxSignal" SG_ 563 KeyOffPwMde_D_Stat 1;
BA_ "GenSigSendType" SG_ 563 KeyOffPwMde_D_Stat 3;
BA_ "U_CD764_MY2022_Tx" SG_ 563 ModemReset_D_Stat 1;
BA_ "U_CD542_MY2021_Tx" SG_ 563 ModemReset_D_Stat 1;
BA_ "ECGUsedTxSignal" SG_ 563 ModemReset_D_Stat 1;
BA_ "GenSigSendType" SG_ 563 ModemReset_D_Stat 3;
BA_ "U_CD764_MY2022_Tx" SG_ 563 FactoryReset_St 1;
BA_ "U_CD542_MY2021_Tx" SG_ 563 FactoryReset_St 1;
BA_ "ECGUsedTxSignal" SG_ 563 FactoryReset_St 1;
BA_ "GenSigSendType" SG_ 563 FactoryReset_St 3;
BA_ "GenSigSendType" SG_ 1705 UUDTSOBDMBResponse2 3;
BA_ "GenSigSendType" SG_ 1704 UUDTSOBDMBResponse1 3;
BA_ "U_CD542_MY2021_Tx" SG_ 1174 BattTracCell35_U_Actl 1;
BA_ "U_CX727_MY2021_Tx" SG_ 1174 BattTracCell35_U_Actl 1;
BA_ "U_U55X_MY2022_Rx" SG_ 1174 BattTracCell35_U_Actl 1;
BA_ "U_CD542_MY2021_Rx" SG_ 1174 BattTracCell35_U_Actl 1;
BA_ "ECGUsedRxSignal" SG_ 1174 BattTracCell35_U_Actl 1;
BA_ "GenSigStartValue" SG_ 1174 BattTracCell35_U_Actl 4094;
BA_ "GenSigStartValueInteger" SG_ 1174 BattTracCell35_U_Actl 4094;
BA_ "U_CD542_MY2021_Tx" SG_ 1174 BattTracCell34_U_Actl 1;
BA_ "U_CX727_MY2021_Tx" SG_ 1174 BattTracCell34_U_Actl 1;
BA_ "U_U55X_MY2022_Rx" SG_ 1174 BattTracCell34_U_Actl 1;
BA_ "U_CD542_MY2021_Rx" SG_ 1174 BattTracCell34_U_Actl 1;
BA_ "ECGUsedRxSignal" SG_ 1174 BattTracCell34_U_Actl 1;
BA_ "GenSigStartValue" SG_ 1174 BattTracCell34_U_Actl 4094;
BA_ "GenSigStartValueInteger" SG_ 1174 BattTracCell34_U_Actl 4094;
BA_ "U_CD542_MY2021_Tx" SG_ 1174 BattTracCell33_U_Actl 1;
BA_ "U_CX727_MY2021_Tx" SG_ 1174 BattTracCell33_U_Actl 1;
BA_ "U_U55X_MY2022_Rx" SG_ 1174 BattTracCell33_U_Actl 1;
BA_ "U_CD542_MY2021_Rx" SG_ 1174 BattTracCell33_U_Actl 1;
BA_ "ECGUsedRxSignal" SG_ 1174 BattTracCell33_U_Actl 1;
BA_ "GenSigStartValue" SG_ 1174 BattTracCell33_U_Actl 4094;
BA_ "GenSigStartValueInteger" SG_ 1174 BattTracCell33_U_Actl 4094;
BA_ "U_CD542_MY2021_Tx" SG_ 1174 BattTracCell32_U_Actl 1;
BA_ "U_CX727_MY2021_Tx" SG_ 1174 BattTracCell32_U_Actl 1;
BA_ "U_U55X_MY2022_Rx" SG_ 1174 BattTracCell32_U_Actl 1;
BA_ "U_CD542_MY2021_Rx" SG_ 1174 BattTracCell32_U_Actl 1;
BA_ "ECGUsedRxSignal" SG_ 1174 BattTracCell32_U_Actl 1;
BA_ "GenSigStartValue" SG_ 1174 BattTracCell32_U_Actl 4094;
BA_ "GenSigStartValueInteger" SG_ 1174 BattTracCell32_U_Actl 4094;
BA_ "U_CD542_MY2021_Tx" SG_ 1174 BattTracCell31_U_Actl 1;
BA_ "U_CX727_MY2021_Tx" SG_ 1174 BattTracCell31_U_Actl 1;
BA_ "U_U55X_MY2022_Rx" SG_ 1174 BattTracCell31_U_Actl 1;
BA_ "U_CD542_MY2021_Rx" SG_ 1174 BattTracCell31_U_Actl 1;
BA_ "ECGUsedRxSignal" SG_ 1174 BattTracCell31_U_Actl 1;
BA_ "GenSigStartValue" SG_ 1174 BattTracCell31_U_Actl 4094;
BA_ "GenSigStartValueInteger" SG_ 1174 BattTracCell31_U_Actl 4094;
BA_ "U_CD542_MY2021_Tx" SG_ 1173 BattTracCell30_U_Actl 1;
BA_ "U_CX727_MY2021_Tx" SG_ 1173 BattTracCell30_U_Actl 1;
BA_ "U_U55X_MY2022_Rx" SG_ 1173 BattTracCell30_U_Actl 1;
BA_ "U_CD542_MY2021_Rx" SG_ 1173 BattTracCell30_U_Actl 1;
BA_ "ECGUsedRxSignal" SG_ 1173 BattTracCell30_U_Actl 1;
BA_ "GenSigStartValue" SG_ 1173 BattTracCell30_U_Actl 4094;
BA_ "GenSigStartValueInteger" SG_ 1173 BattTracCell30_U_Actl 4094;
BA_ "U_CD542_MY2021_Tx" SG_ 1173 BattTracCell29_U_Actl 1;
BA_ "U_CX727_MY2021_Tx" SG_ 1173 BattTracCell29_U_Actl 1;
BA_ "U_U55X_MY2022_Rx" SG_ 1173 BattTracCell29_U_Actl 1;
BA_ "U_CD542_MY2021_Rx" SG_ 1173 BattTracCell29_U_Actl 1;
BA_ "ECGUsedRxSignal" SG_ 1173 BattTracCell29_U_Actl 1;
BA_ "GenSigStartValue" SG_ 1173 BattTracCell29_U_Actl 4094;
BA_ "GenSigStartValueInteger" SG_ 1173 BattTracCell29_U_Actl 4094;
BA_ "U_CD542_MY2021_Tx" SG_ 1173 BattTracCell28_U_Actl 1;
BA_ "U_CX727_MY2021_Tx" SG_ 1173 BattTracCell28_U_Actl 1;
BA_ "U_U55X_MY2022_Rx" SG_ 1173 BattTracCell28_U_Actl 1;
BA_ "U_CD542_MY2021_Rx" SG_ 1173 BattTracCell28_U_Actl 1;
BA_ "ECGUsedRxSignal" SG_ 1173 BattTracCell28_U_Actl 1;
BA_ "GenSigStartValue" SG_ 1173 BattTracCell28_U_Actl 4094;
BA_ "GenSigStartValueInteger" SG_ 1173 BattTracCell28_U_Actl 4094;
BA_ "U_CD542_MY2021_Tx" SG_ 1173 BattTracCell27_U_Actl 1;
BA_ "U_CX727_MY2021_Tx" SG_ 1173 BattTracCell27_U_Actl 1;
BA_ "U_U55X_MY2022_Rx" SG_ 1173 BattTracCell27_U_Actl 1;
BA_ "U_CD542_MY2021_Rx" SG_ 1173 BattTracCell27_U_Actl 1;
BA_ "ECGUsedRxSignal" SG_ 1173 BattTracCell27_U_Actl 1;
BA_ "GenSigStartValue" SG_ 1173 BattTracCell27_U_Actl 4094;
BA_ "GenSigStartValueInteger" SG_ 1173 BattTracCell27_U_Actl 4094;
BA_ "U_CD542_MY2021_Tx" SG_ 1173 BattTracCell26_U_Actl 1;
BA_ "U_CX727_MY2021_Tx" SG_ 1173 BattTracCell26_U_Actl 1;
BA_ "U_U55X_MY2022_Rx" SG_ 1173 BattTracCell26_U_Actl 1;
BA_ "U_CD542_MY2021_Rx" SG_ 1173 BattTracCell26_U_Actl 1;
BA_ "ECGUsedRxSignal" SG_ 1173 BattTracCell26_U_Actl 1;
BA_ "GenSigStartValue" SG_ 1173 BattTracCell26_U_Actl 4094;
BA_ "GenSigStartValueInteger" SG_ 1173 BattTracCell26_U_Actl 4094;
BA_ "U_CD542_MY2021_Tx" SG_ 1172 BattTracCell25_U_Actl 1;
BA_ "U_CX727_MY2021_Tx" SG_ 1172 BattTracCell25_U_Actl 1;
BA_ "U_U55X_MY2022_Rx" SG_ 1172 BattTracCell25_U_Actl 1;
BA_ "U_CD542_MY2021_Rx" SG_ 1172 BattTracCell25_U_Actl 1;
BA_ "ECGUsedRxSignal" SG_ 1172 BattTracCell25_U_Actl 1;
BA_ "GenSigStartValue" SG_ 1172 BattTracCell25_U_Actl 4094;
BA_ "GenSigStartValueInteger" SG_ 1172 BattTracCell25_U_Actl 4094;
BA_ "U_CD542_MY2021_Tx" SG_ 1172 BattTracCell24_U_Actl 1;
BA_ "U_CX727_MY2021_Tx" SG_ 1172 BattTracCell24_U_Actl 1;
BA_ "U_U55X_MY2022_Rx" SG_ 1172 BattTracCell24_U_Actl 1;
BA_ "U_CD542_MY2021_Rx" SG_ 1172 BattTracCell24_U_Actl 1;
BA_ "ECGUsedRxSignal" SG_ 1172 BattTracCell24_U_Actl 1;
BA_ "GenSigStartValue" SG_ 1172 BattTracCell24_U_Actl 4094;
BA_ "GenSigStartValueInteger" SG_ 1172 BattTracCell24_U_Actl 4094;
BA_ "U_CD542_MY2021_Tx" SG_ 1172 BattTracCell23_U_Actl 1;
BA_ "U_CX727_MY2021_Tx" SG_ 1172 BattTracCell23_U_Actl 1;
BA_ "U_U55X_MY2022_Rx" SG_ 1172 BattTracCell23_U_Actl 1;
BA_ "U_CD542_MY2021_Rx" SG_ 1172 BattTracCell23_U_Actl 1;
BA_ "ECGUsedRxSignal" SG_ 1172 BattTracCell23_U_Actl 1;
BA_ "GenSigStartValue" SG_ 1172 BattTracCell23_U_Actl 4094;
BA_ "GenSigStartValueInteger" SG_ 1172 BattTracCell23_U_Actl 4094;
BA_ "U_CD542_MY2021_Tx" SG_ 1172 BattTracCell22_U_Actl 1;
BA_ "U_CX727_MY2021_Tx" SG_ 1172 BattTracCell22_U_Actl 1;
BA_ "U_U55X_MY2022_Rx" SG_ 1172 BattTracCell22_U_Actl 1;
BA_ "U_CD542_MY2021_Rx" SG_ 1172 BattTracCell22_U_Actl 1;
BA_ "ECGUsedRxSignal" SG_ 1172 BattTracCell22_U_Actl 1;
BA_ "GenSigStartValue" SG_ 1172 BattTracCell22_U_Actl 4094;
BA_ "GenSigStartValueInteger" SG_ 1172 BattTracCell22_U_Actl 4094;
BA_ "U_CD542_MY2021_Tx" SG_ 1172 BattTracCell21_U_Actl 1;
BA_ "U_CX727_MY2021_Tx" SG_ 1172 BattTracCell21_U_Actl 1;
BA_ "U_U55X_MY2022_Rx" SG_ 1172 BattTracCell21_U_Actl 1;
BA_ "U_CD542_MY2021_Rx" SG_ 1172 BattTracCell21_U_Actl 1;
BA_ "ECGUsedRxSignal" SG_ 1172 BattTracCell21_U_Actl 1;
BA_ "GenSigStartValue" SG_ 1172 BattTracCell21_U_Actl 4094;
BA_ "GenSigStartValueInteger" SG_ 1172 BattTracCell21_U_Actl 4094;
BA_ "U_CD542_MY2021_Tx" SG_ 1171 BattTracCell20_U_Actl 1;
BA_ "U_CX727_MY2021_Tx" SG_ 1171 BattTracCell20_U_Actl 1;
BA_ "U_U55X_MY2022_Rx" SG_ 1171 BattTracCell20_U_Actl 1;
BA_ "U_CD542_MY2021_Rx" SG_ 1171 BattTracCell20_U_Actl 1;
BA_ "ECGUsedRxSignal" SG_ 1171 BattTracCell20_U_Actl 1;
BA_ "GenSigStartValue" SG_ 1171 BattTracCell20_U_Actl 4094;
BA_ "GenSigStartValueInteger" SG_ 1171 BattTracCell20_U_Actl 4094;
BA_ "U_CD542_MY2021_Tx" SG_ 1171 BattTracCell19_U_Actl 1;
BA_ "U_CX727_MY2021_Tx" SG_ 1171 BattTracCell19_U_Actl 1;
BA_ "U_U55X_MY2022_Rx" SG_ 1171 BattTracCell19_U_Actl 1;
BA_ "U_CD542_MY2021_Rx" SG_ 1171 BattTracCell19_U_Actl 1;
BA_ "ECGUsedRxSignal" SG_ 1171 BattTracCell19_U_Actl 1;
BA_ "GenSigStartValue" SG_ 1171 BattTracCell19_U_Actl 4094;
BA_ "GenSigStartValueInteger" SG_ 1171 BattTracCell19_U_Actl 4094;
BA_ "U_CD542_MY2021_Tx" SG_ 1171 BattTracCell18_U_Actl 1;
BA_ "U_CX727_MY2021_Tx" SG_ 1171 BattTracCell18_U_Actl 1;
BA_ "U_U55X_MY2022_Rx" SG_ 1171 BattTracCell18_U_Actl 1;
BA_ "U_CD542_MY2021_Rx" SG_ 1171 BattTracCell18_U_Actl 1;
BA_ "ECGUsedRxSignal" SG_ 1171 BattTracCell18_U_Actl 1;
BA_ "GenSigStartValue" SG_ 1171 BattTracCell18_U_Actl 4094;
BA_ "GenSigStartValueInteger" SG_ 1171 BattTracCell18_U_Actl 4094;
BA_ "U_CD542_MY2021_Tx" SG_ 1171 BattTracCell17_U_Actl 1;
BA_ "U_CX727_MY2021_Tx" SG_ 1171 BattTracCell17_U_Actl 1;
BA_ "U_U55X_MY2022_Rx" SG_ 1171 BattTracCell17_U_Actl 1;
BA_ "U_CD542_MY2021_Rx" SG_ 1171 BattTracCell17_U_Actl 1;
BA_ "ECGUsedRxSignal" SG_ 1171 BattTracCell17_U_Actl 1;
BA_ "GenSigStartValue" SG_ 1171 BattTracCell17_U_Actl 4094;
BA_ "GenSigStartValueInteger" SG_ 1171 BattTracCell17_U_Actl 4094;
BA_ "U_CD542_MY2021_Tx" SG_ 1171 BattTracCell16_U_Actl 1;
BA_ "U_CX727_MY2021_Tx" SG_ 1171 BattTracCell16_U_Actl 1;
BA_ "U_U55X_MY2022_Rx" SG_ 1171 BattTracCell16_U_Actl 1;
BA_ "U_CD542_MY2021_Rx" SG_ 1171 BattTracCell16_U_Actl 1;
BA_ "ECGUsedRxSignal" SG_ 1171 BattTracCell16_U_Actl 1;
BA_ "GenSigStartValue" SG_ 1171 BattTracCell16_U_Actl 4094;
BA_ "GenSigStartValueInteger" SG_ 1171 BattTracCell16_U_Actl 4094;
BA_ "U_CD542_MY2021_Tx" SG_ 1170 BattTracCell15_U_Actl 1;
BA_ "U_CX727_MY2021_Tx" SG_ 1170 BattTracCell15_U_Actl 1;
BA_ "U_U55X_MY2022_Rx" SG_ 1170 BattTracCell15_U_Actl 1;
BA_ "U_CD542_MY2021_Rx" SG_ 1170 BattTracCell15_U_Actl 1;
BA_ "ECGUsedRxSignal" SG_ 1170 BattTracCell15_U_Actl 1;
BA_ "GenSigStartValue" SG_ 1170 BattTracCell15_U_Actl 4094;
BA_ "GenSigStartValueInteger" SG_ 1170 BattTracCell15_U_Actl 4094;
BA_ "U_CD542_MY2021_Tx" SG_ 1170 BattTracCell14_U_Actl 1;
BA_ "U_CX727_MY2021_Tx" SG_ 1170 BattTracCell14_U_Actl 1;
BA_ "U_U55X_MY2022_Rx" SG_ 1170 BattTracCell14_U_Actl 1;
BA_ "U_CD542_MY2021_Rx" SG_ 1170 BattTracCell14_U_Actl 1;
BA_ "ECGUsedRxSignal" SG_ 1170 BattTracCell14_U_Actl 1;
BA_ "GenSigStartValue" SG_ 1170 BattTracCell14_U_Actl 4094;
BA_ "GenSigStartValueInteger" SG_ 1170 BattTracCell14_U_Actl 4094;
BA_ "U_CD542_MY2021_Tx" SG_ 1170 BattTracCell13_U_Actl 1;
BA_ "U_CX727_MY2021_Tx" SG_ 1170 BattTracCell13_U_Actl 1;
BA_ "U_U55X_MY2022_Rx" SG_ 1170 BattTracCell13_U_Actl 1;
BA_ "U_CD542_MY2021_Rx" SG_ 1170 BattTracCell13_U_Actl 1;
BA_ "ECGUsedRxSignal" SG_ 1170 BattTracCell13_U_Actl 1;
BA_ "GenSigStartValue" SG_ 1170 BattTracCell13_U_Actl 4094;
BA_ "GenSigStartValueInteger" SG_ 1170 BattTracCell13_U_Actl 4094;
BA_ "U_CD542_MY2021_Tx" SG_ 1170 BattTracCell12_U_Actl 1;
BA_ "U_CX727_MY2021_Tx" SG_ 1170 BattTracCell12_U_Actl 1;
BA_ "U_U55X_MY2022_Rx" SG_ 1170 BattTracCell12_U_Actl 1;
BA_ "U_CD542_MY2021_Rx" SG_ 1170 BattTracCell12_U_Actl 1;
BA_ "ECGUsedRxSignal" SG_ 1170 BattTracCell12_U_Actl 1;
BA_ "GenSigStartValue" SG_ 1170 BattTracCell12_U_Actl 4094;
BA_ "GenSigStartValueInteger" SG_ 1170 BattTracCell12_U_Actl 4094;
BA_ "U_CD542_MY2021_Tx" SG_ 1170 BattTracCell11_U_Actl 1;
BA_ "U_CX727_MY2021_Tx" SG_ 1170 BattTracCell11_U_Actl 1;
BA_ "U_U55X_MY2022_Rx" SG_ 1170 BattTracCell11_U_Actl 1;
BA_ "U_CD542_MY2021_Rx" SG_ 1170 BattTracCell11_U_Actl 1;
BA_ "ECGUsedRxSignal" SG_ 1170 BattTracCell11_U_Actl 1;
BA_ "GenSigStartValue" SG_ 1170 BattTracCell11_U_Actl 4094;
BA_ "GenSigStartValueInteger" SG_ 1170 BattTracCell11_U_Actl 4094;
BA_ "U_CD542_MY2021_Tx" SG_ 1191 BattTracTe14_Te_Actl 1;
BA_ "U_CX727_MY2021_Tx" SG_ 1191 BattTracTe14_Te_Actl 1;
BA_ "U_U55X_MY2022_Rx" SG_ 1191 BattTracTe14_Te_Actl 1;
BA_ "U_CD542_MY2021_Rx" SG_ 1191 BattTracTe14_Te_Actl 1;
BA_ "ECGUsedRxSignal" SG_ 1191 BattTracTe14_Te_Actl 1;
BA_ "GenSigStartValue" SG_ 1191 BattTracTe14_Te_Actl 254;
BA_ "GenSigStartValueInteger" SG_ 1191 BattTracTe14_Te_Actl 254;
BA_ "U_CD542_MY2021_Tx" SG_ 1191 BattTracTe19_Te_Actl 1;
BA_ "U_CX727_MY2021_Tx" SG_ 1191 BattTracTe19_Te_Actl 1;
BA_ "U_U55X_MY2022_Rx" SG_ 1191 BattTracTe19_Te_Actl 1;
BA_ "U_CD542_MY2021_Rx" SG_ 1191 BattTracTe19_Te_Actl 1;
BA_ "ECGUsedRxSignal" SG_ 1191 BattTracTe19_Te_Actl 1;
BA_ "GenSigStartValue" SG_ 1191 BattTracTe19_Te_Actl 254;
BA_ "GenSigStartValueInteger" SG_ 1191 BattTracTe19_Te_Actl 254;
BA_ "U_CD542_MY2021_Tx" SG_ 1191 BattTracTe18_Te_Actl 1;
BA_ "U_CX727_MY2021_Tx" SG_ 1191 BattTracTe18_Te_Actl 1;
BA_ "U_U55X_MY2022_Rx" SG_ 1191 BattTracTe18_Te_Actl 1;
BA_ "U_CD542_MY2021_Rx" SG_ 1191 BattTracTe18_Te_Actl 1;
BA_ "ECGUsedRxSignal" SG_ 1191 BattTracTe18_Te_Actl 1;
BA_ "GenSigStartValue" SG_ 1191 BattTracTe18_Te_Actl 254;
BA_ "GenSigStartValueInteger" SG_ 1191 BattTracTe18_Te_Actl 254;
BA_ "U_CD542_MY2021_Tx" SG_ 1191 BattTracTe17_Te_Actl 1;
BA_ "U_CX727_MY2021_Tx" SG_ 1191 BattTracTe17_Te_Actl 1;
BA_ "U_U55X_MY2022_Rx" SG_ 1191 BattTracTe17_Te_Actl 1;
BA_ "U_CD542_MY2021_Rx" SG_ 1191 BattTracTe17_Te_Actl 1;
BA_ "ECGUsedRxSignal" SG_ 1191 BattTracTe17_Te_Actl 1;
BA_ "GenSigStartValue" SG_ 1191 BattTracTe17_Te_Actl 254;
BA_ "GenSigStartValueInteger" SG_ 1191 BattTracTe17_Te_Actl 254;
BA_ "U_CD542_MY2021_Tx" SG_ 1191 BattTracTe16_Te_Actl 1;
BA_ "U_CX727_MY2021_Tx" SG_ 1191 BattTracTe16_Te_Actl 1;
BA_ "U_U55X_MY2022_Rx" SG_ 1191 BattTracTe16_Te_Actl 1;
BA_ "U_CD542_MY2021_Rx" SG_ 1191 BattTracTe16_Te_Actl 1;
BA_ "ECGUsedRxSignal" SG_ 1191 BattTracTe16_Te_Actl 1;
BA_ "GenSigStartValue" SG_ 1191 BattTracTe16_Te_Actl 254;
BA_ "GenSigStartValueInteger" SG_ 1191 BattTracTe16_Te_Actl 254;
BA_ "U_CD542_MY2021_Tx" SG_ 1191 BattTracTe15_Te_Actl 1;
BA_ "U_CX727_MY2021_Tx" SG_ 1191 BattTracTe15_Te_Actl 1;
BA_ "U_U55X_MY2022_Rx" SG_ 1191 BattTracTe15_Te_Actl 1;
BA_ "U_CD542_MY2021_Rx" SG_ 1191 BattTracTe15_Te_Actl 1;
BA_ "ECGUsedRxSignal" SG_ 1191 BattTracTe15_Te_Actl 1;
BA_ "GenSigStartValue" SG_ 1191 BattTracTe15_Te_Actl 254;
BA_ "GenSigStartValueInteger" SG_ 1191 BattTracTe15_Te_Actl 254;
BA_ "U_CX727_MY2021_Tx" SG_ 1189 BattTracUMxArry_No_Actl 1;
BA_ "U_U55X_MY2022_Rx" SG_ 1189 BattTracUMxArry_No_Actl 1;
BA_ "U_CD542_MY2021_Rx" SG_ 1189 BattTracUMxArry_No_Actl 1;
BA_ "ECGUsedRxSignal" SG_ 1189 BattTracUMxArry_No_Actl 1;
BA_ "GenSigStartValue" SG_ 1189 BattTracUMxArry_No_Actl 31;
BA_ "GenSigStartValueInteger" SG_ 1189 BattTracUMxArry_No_Actl 31;
BA_ "U_CD542_MY2021_Tx" SG_ 1189 BattTracCellUMx_No_Actl 1;
BA_ "U_CX727_MY2021_Tx" SG_ 1189 BattTracCellUMx_No_Actl 1;
BA_ "U_U55X_MY2022_Rx" SG_ 1189 BattTracCellUMx_No_Actl 1;
BA_ "U_CD542_MY2021_Rx" SG_ 1189 BattTracCellUMx_No_Actl 1;
BA_ "ECGUsedRxSignal" SG_ 1189 BattTracCellUMx_No_Actl 1;
BA_ "GenSigStartValue" SG_ 1189 BattTracCellUMx_No_Actl 254;
BA_ "GenSigStartValueInteger" SG_ 1189 BattTracCellUMx_No_Actl 254;
BA_ "U_CD542_MY2021_Tx" SG_ 1189 BattChrgUMx_B_Falt 1;
BA_ "U_CX727_MY2021_Tx" SG_ 1189 BattChrgUMx_B_Falt 1;
BA_ "U_U55X_MY2022_Rx" SG_ 1189 BattChrgUMx_B_Falt 1;
BA_ "U_CD542_MY2021_Rx" SG_ 1189 BattChrgUMx_B_Falt 1;
BA_ "ECGUsedRxSignal" SG_ 1189 BattChrgUMx_B_Falt 1;
BA_ "U_CD542_MY2021_Tx" SG_ 1189 BattTracCellUMn_No_Actl 1;
BA_ "U_CX727_MY2021_Tx" SG_ 1189 BattTracCellUMn_No_Actl 1;
BA_ "U_U55X_MY2022_Rx" SG_ 1189 BattTracCellUMn_No_Actl 1;
BA_ "U_CD542_MY2021_Rx" SG_ 1189 BattTracCellUMn_No_Actl 1;
BA_ "ECGUsedRxSignal" SG_ 1189 BattTracCellUMn_No_Actl 1;
BA_ "GenSigStartValue" SG_ 1189 BattTracCellUMn_No_Actl 254;
BA_ "GenSigStartValueInteger" SG_ 1189 BattTracCellUMn_No_Actl 254;
BA_ "U_CD542_MY2021_Tx" SG_ 1189 BattTracCellCnt_No_Actl 1;
BA_ "U_CX727_MY2021_Tx" SG_ 1189 BattTracCellCnt_No_Actl 1;
BA_ "U_U55X_MY2022_Rx" SG_ 1189 BattTracCellCnt_No_Actl 1;
BA_ "U_CD542_MY2021_Rx" SG_ 1189 BattTracCellCnt_No_Actl 1;
BA_ "ECGUsedRxSignal" SG_ 1189 BattTracCellCnt_No_Actl 1;
BA_ "GenSigStartValue" SG_ 1189 BattTracCellCnt_No_Actl 254;
BA_ "GenSigStartValueInteger" SG_ 1189 BattTracCellCnt_No_Actl 254;
BA_ "U_CX727_MY2021_Tx" SG_ 1189 BattChrgIsltn_B_Falt 1;
BA_ "U_U55X_MY2022_Rx" SG_ 1189 BattChrgIsltn_B_Falt 1;
BA_ "U_CD542_MY2021_Rx" SG_ 1189 BattChrgIsltn_B_Falt 1;
BA_ "ECGUsedRxSignal" SG_ 1189 BattChrgIsltn_B_Falt 1;
BA_ "U_CD542_MY2021_Tx" SG_ 1189 BattTracCellDiff_B_Falt 1;
BA_ "U_CX727_MY2021_Tx" SG_ 1189 BattTracCellDiff_B_Falt 1;
BA_ "U_U55X_MY2022_Rx" SG_ 1189 BattTracCellDiff_B_Falt 1;
BA_ "U_CD542_MY2021_Rx" SG_ 1189 BattTracCellDiff_B_Falt 1;
BA_ "ECGUsedRxSignal" SG_ 1189 BattTracCellDiff_B_Falt 1;
BA_ "U_CD542_MY2021_Tx" SG_ 1189 BattChrgSocMx_B_Falt 1;
BA_ "U_CX727_MY2021_Tx" SG_ 1189 BattChrgSocMx_B_Falt 1;
BA_ "U_U55X_MY2022_Rx" SG_ 1189 BattChrgSocMx_B_Falt 1;
BA_ "U_CD542_MY2021_Rx" SG_ 1189 BattChrgSocMx_B_Falt 1;
BA_ "ECGUsedRxSignal" SG_ 1189 BattChrgSocMx_B_Falt 1;
BA_ "U_CD542_MY2021_Tx" SG_ 1189 BattChrgSocMn_B_Falt 1;
BA_ "U_CX727_MY2021_Tx" SG_ 1189 BattChrgSocMn_B_Falt 1;
BA_ "U_U55X_MY2022_Rx" SG_ 1189 BattChrgSocMn_B_Falt 1;
BA_ "U_CD542_MY2021_Rx" SG_ 1189 BattChrgSocMn_B_Falt 1;
BA_ "ECGUsedRxSignal" SG_ 1189 BattChrgSocMn_B_Falt 1;
BA_ "U_CD542_MY2021_Tx" SG_ 1189 BattChrgSocErrtc_B_Falt 1;
BA_ "U_CX727_MY2021_Tx" SG_ 1189 BattChrgSocErrtc_B_Falt 1;
BA_ "U_U55X_MY2022_Rx" SG_ 1189 BattChrgSocErrtc_B_Falt 1;
BA_ "U_CD542_MY2021_Rx" SG_ 1189 BattChrgSocErrtc_B_Falt 1;
BA_ "ECGUsedRxSignal" SG_ 1189 BattChrgSocErrtc_B_Falt 1;
BA_ "U_CD542_MY2021_Tx" SG_ 1189 BattTracUMx_B_Falt 1;
BA_ "U_CX727_MY2021_Tx" SG_ 1189 BattTracUMx_B_Falt 1;
BA_ "U_U55X_MY2022_Rx" SG_ 1189 BattTracUMx_B_Falt 1;
BA_ "U_CD542_MY2021_Rx" SG_ 1189 BattTracUMx_B_Falt 1;
BA_ "ECGUsedRxSignal" SG_ 1189 BattTracUMx_B_Falt 1;
BA_ "U_CD542_MY2021_Tx" SG_ 1189 BattTracUMn_B_Falt 1;
BA_ "U_CX727_MY2021_Tx" SG_ 1189 BattTracUMn_B_Falt 1;
BA_ "U_U55X_MY2022_Rx" SG_ 1189 BattTracUMn_B_Falt 1;
BA_ "U_CD542_MY2021_Rx" SG_ 1189 BattTracUMn_B_Falt 1;
BA_ "ECGUsedRxSignal" SG_ 1189 BattTracUMn_B_Falt 1;
BA_ "U_CD542_MY2021_Tx" SG_ 1189 BattTracTeMx_No_Actl 1;
BA_ "U_CX727_MY2021_Tx" SG_ 1189 BattTracTeMx_No_Actl 1;
BA_ "U_U55X_MY2022_Rx" SG_ 1189 BattTracTeMx_No_Actl 1;
BA_ "U_CD542_MY2021_Rx" SG_ 1189 BattTracTeMx_No_Actl 1;
BA_ "ECGUsedRxSignal" SG_ 1189 BattTracTeMx_No_Actl 1;
BA_ "GenSigStartValue" SG_ 1189 BattTracTeMx_No_Actl 254;
BA_ "GenSigStartValueInteger" SG_ 1189 BattTracTeMx_No_Actl 254;
BA_ "U_CD542_MY2021_Tx" SG_ 1189 BattTracTeMx_B_Falt 1;
BA_ "U_CX727_MY2021_Tx" SG_ 1189 BattTracTeMx_B_Falt 1;
BA_ "U_U55X_MY2022_Rx" SG_ 1189 BattTracTeMx_B_Falt 1;
BA_ "U_CD542_MY2021_Rx" SG_ 1189 BattTracTeMx_B_Falt 1;
BA_ "ECGUsedRxSignal" SG_ 1189 BattTracTeMx_B_Falt 1;
BA_ "U_CD542_MY2021_Tx" SG_ 1189 BattTracTeMn_No_Actl 1;
BA_ "U_CX727_MY2021_Tx" SG_ 1189 BattTracTeMn_No_Actl 1;
BA_ "U_U55X_MY2022_Rx" SG_ 1189 BattTracTeMn_No_Actl 1;
BA_ "U_CD542_MY2021_Rx" SG_ 1189 BattTracTeMn_No_Actl 1;
BA_ "ECGUsedRxSignal" SG_ 1189 BattTracTeMn_No_Actl 1;
BA_ "GenSigStartValue" SG_ 1189 BattTracTeMn_No_Actl 254;
BA_ "GenSigStartValueInteger" SG_ 1189 BattTracTeMn_No_Actl 254;
BA_ "U_CD542_MY2021_Tx" SG_ 1189 BattTracTeDelta_B_Falt 1;
BA_ "U_CX727_MY2021_Tx" SG_ 1189 BattTracTeDelta_B_Falt 1;
BA_ "U_U55X_MY2022_Rx" SG_ 1189 BattTracTeDelta_B_Falt 1;
BA_ "U_CD542_MY2021_Rx" SG_ 1189 BattTracTeDelta_B_Falt 1;
BA_ "ECGUsedRxSignal" SG_ 1189 BattTracTeDelta_B_Falt 1;
BA_ "U_CD542_MY2021_Tx" SG_ 1189 BattTracTeCnt_No_Actl 1;
BA_ "U_CX727_MY2021_Tx" SG_ 1189 BattTracTeCnt_No_Actl 1;
BA_ "U_U55X_MY2022_Rx" SG_ 1189 BattTracTeCnt_No_Actl 1;
BA_ "U_CD542_MY2021_Rx" SG_ 1189 BattTracTeCnt_No_Actl 1;
BA_ "ECGUsedRxSignal" SG_ 1189 BattTracTeCnt_No_Actl 1;
BA_ "GenSigStartValue" SG_ 1189 BattTracTeCnt_No_Actl 254;
BA_ "GenSigStartValueInteger" SG_ 1189 BattTracTeCnt_No_Actl 254;
BA_ "U_CD542_MY2021_Tx" SG_ 1189 BattTracSoftware_B_Falt 1;
BA_ "U_CX727_MY2021_Tx" SG_ 1189 BattTracSoftware_B_Falt 1;
BA_ "U_U55X_MY2022_Rx" SG_ 1189 BattTracSoftware_B_Falt 1;
BA_ "U_CD542_MY2021_Rx" SG_ 1189 BattTracSoftware_B_Falt 1;
BA_ "ECGUsedRxSignal" SG_ 1189 BattTracSoftware_B_Falt 1;
BA_ "U_CD542_MY2021_Tx" SG_ 1188 BattTracTe13_Te_Actl 1;
BA_ "U_CX727_MY2021_Tx" SG_ 1188 BattTracTe13_Te_Actl 1;
BA_ "U_U55X_MY2022_Rx" SG_ 1188 BattTracTe13_Te_Actl 1;
BA_ "U_CD542_MY2021_Rx" SG_ 1188 BattTracTe13_Te_Actl 1;
BA_ "ECGUsedRxSignal" SG_ 1188 BattTracTe13_Te_Actl 1;
BA_ "GenSigStartValue" SG_ 1188 BattTracTe13_Te_Actl 254;
BA_ "GenSigStartValueInteger" SG_ 1188 BattTracTe13_Te_Actl 254;
BA_ "U_CD542_MY2021_Tx" SG_ 1188 BattTracTe12_Te_Actl 1;
BA_ "U_CX727_MY2021_Tx" SG_ 1188 BattTracTe12_Te_Actl 1;
BA_ "U_U55X_MY2022_Rx" SG_ 1188 BattTracTe12_Te_Actl 1;
BA_ "U_CD542_MY2021_Rx" SG_ 1188 BattTracTe12_Te_Actl 1;
BA_ "ECGUsedRxSignal" SG_ 1188 BattTracTe12_Te_Actl 1;
BA_ "GenSigStartValue" SG_ 1188 BattTracTe12_Te_Actl 254;
BA_ "GenSigStartValueInteger" SG_ 1188 BattTracTe12_Te_Actl 254;
BA_ "U_CD542_MY2021_Tx" SG_ 1188 BattTracTe11_Te_Actl 1;
BA_ "U_CX727_MY2021_Tx" SG_ 1188 BattTracTe11_Te_Actl 1;
BA_ "U_U55X_MY2022_Rx" SG_ 1188 BattTracTe11_Te_Actl 1;
BA_ "U_CD542_MY2021_Rx" SG_ 1188 BattTracTe11_Te_Actl 1;
BA_ "ECGUsedRxSignal" SG_ 1188 BattTracTe11_Te_Actl 1;
BA_ "GenSigStartValue" SG_ 1188 BattTracTe11_Te_Actl 254;
BA_ "GenSigStartValueInteger" SG_ 1188 BattTracTe11_Te_Actl 254;
BA_ "U_CD542_MY2021_Tx" SG_ 1188 BattTracTe10_Te_Actl 1;
BA_ "U_CX727_MY2021_Tx" SG_ 1188 BattTracTe10_Te_Actl 1;
BA_ "U_U55X_MY2022_Rx" SG_ 1188 BattTracTe10_Te_Actl 1;
BA_ "U_CD542_MY2021_Rx" SG_ 1188 BattTracTe10_Te_Actl 1;
BA_ "ECGUsedRxSignal" SG_ 1188 BattTracTe10_Te_Actl 1;
BA_ "GenSigStartValue" SG_ 1188 BattTracTe10_Te_Actl 254;
BA_ "GenSigStartValueInteger" SG_ 1188 BattTracTe10_Te_Actl 254;
BA_ "U_CD542_MY2021_Tx" SG_ 1188 BattTracTe09_Te_Actl 1;
BA_ "U_CX727_MY2021_Tx" SG_ 1188 BattTracTe09_Te_Actl 1;
BA_ "U_U55X_MY2022_Rx" SG_ 1188 BattTracTe09_Te_Actl 1;
BA_ "U_CD542_MY2021_Rx" SG_ 1188 BattTracTe09_Te_Actl 1;
BA_ "ECGUsedRxSignal" SG_ 1188 BattTracTe09_Te_Actl 1;
BA_ "GenSigStartValue" SG_ 1188 BattTracTe09_Te_Actl 254;
BA_ "GenSigStartValueInteger" SG_ 1188 BattTracTe09_Te_Actl 254;
BA_ "U_CD542_MY2021_Tx" SG_ 1188 BattTracTe08_Te_Actl 1;
BA_ "U_CX727_MY2021_Tx" SG_ 1188 BattTracTe08_Te_Actl 1;
BA_ "U_U55X_MY2022_Rx" SG_ 1188 BattTracTe08_Te_Actl 1;
BA_ "U_CD542_MY2021_Rx" SG_ 1188 BattTracTe08_Te_Actl 1;
BA_ "ECGUsedRxSignal" SG_ 1188 BattTracTe08_Te_Actl 1;
BA_ "GenSigStartValue" SG_ 1188 BattTracTe08_Te_Actl 254;
BA_ "GenSigStartValueInteger" SG_ 1188 BattTracTe08_Te_Actl 254;
BA_ "U_CD542_MY2021_Tx" SG_ 1188 BattTracTe07_Te_Actl 1;
BA_ "U_CX727_MY2021_Tx" SG_ 1188 BattTracTe07_Te_Actl 1;
BA_ "U_U55X_MY2022_Rx" SG_ 1188 BattTracTe07_Te_Actl 1;
BA_ "U_CD542_MY2021_Rx" SG_ 1188 BattTracTe07_Te_Actl 1;
BA_ "ECGUsedRxSignal" SG_ 1188 BattTracTe07_Te_Actl 1;
BA_ "GenSigStartValue" SG_ 1188 BattTracTe07_Te_Actl 254;
BA_ "GenSigStartValueInteger" SG_ 1188 BattTracTe07_Te_Actl 254;
BA_ "U_CD542_MY2021_Tx" SG_ 1187 BattTracTe06_Te_Actl 1;
BA_ "U_CX727_MY2021_Tx" SG_ 1187 BattTracTe06_Te_Actl 1;
BA_ "U_U55X_MY2022_Rx" SG_ 1187 BattTracTe06_Te_Actl 1;
BA_ "U_CD542_MY2021_Rx" SG_ 1187 BattTracTe06_Te_Actl 1;
BA_ "ECGUsedRxSignal" SG_ 1187 BattTracTe06_Te_Actl 1;
BA_ "GenSigStartValue" SG_ 1187 BattTracTe06_Te_Actl 254;
BA_ "GenSigStartValueInteger" SG_ 1187 BattTracTe06_Te_Actl 254;
BA_ "U_CD542_MY2021_Tx" SG_ 1187 BattTracTe05_Te_Actl 1;
BA_ "U_CX727_MY2021_Tx" SG_ 1187 BattTracTe05_Te_Actl 1;
BA_ "U_U55X_MY2022_Rx" SG_ 1187 BattTracTe05_Te_Actl 1;
BA_ "U_CD542_MY2021_Rx" SG_ 1187 BattTracTe05_Te_Actl 1;
BA_ "ECGUsedRxSignal" SG_ 1187 BattTracTe05_Te_Actl 1;
BA_ "GenSigStartValue" SG_ 1187 BattTracTe05_Te_Actl 254;
BA_ "GenSigStartValueInteger" SG_ 1187 BattTracTe05_Te_Actl 254;
BA_ "U_CD542_MY2021_Tx" SG_ 1187 BattTracTe04_Te_Actl 1;
BA_ "U_CX727_MY2021_Tx" SG_ 1187 BattTracTe04_Te_Actl 1;
BA_ "U_U55X_MY2022_Rx" SG_ 1187 BattTracTe04_Te_Actl 1;
BA_ "U_CD542_MY2021_Rx" SG_ 1187 BattTracTe04_Te_Actl 1;
BA_ "ECGUsedRxSignal" SG_ 1187 BattTracTe04_Te_Actl 1;
BA_ "GenSigStartValue" SG_ 1187 BattTracTe04_Te_Actl 254;
BA_ "GenSigStartValueInteger" SG_ 1187 BattTracTe04_Te_Actl 254;
BA_ "U_CD542_MY2021_Tx" SG_ 1187 BattTracTe03_Te_Actl 1;
BA_ "U_CX727_MY2021_Tx" SG_ 1187 BattTracTe03_Te_Actl 1;
BA_ "U_U55X_MY2022_Rx" SG_ 1187 BattTracTe03_Te_Actl 1;
BA_ "U_CD542_MY2021_Rx" SG_ 1187 BattTracTe03_Te_Actl 1;
BA_ "ECGUsedRxSignal" SG_ 1187 BattTracTe03_Te_Actl 1;
BA_ "GenSigStartValue" SG_ 1187 BattTracTe03_Te_Actl 254;
BA_ "GenSigStartValueInteger" SG_ 1187 BattTracTe03_Te_Actl 254;
BA_ "U_CD542_MY2021_Tx" SG_ 1187 BattTracTe02_Te_Actl 1;
BA_ "U_CX727_MY2021_Tx" SG_ 1187 BattTracTe02_Te_Actl 1;
BA_ "U_U55X_MY2022_Rx" SG_ 1187 BattTracTe02_Te_Actl 1;
BA_ "U_CD542_MY2021_Rx" SG_ 1187 BattTracTe02_Te_Actl 1;
BA_ "ECGUsedRxSignal" SG_ 1187 BattTracTe02_Te_Actl 1;
BA_ "GenSigStartValue" SG_ 1187 BattTracTe02_Te_Actl 254;
BA_ "GenSigStartValueInteger" SG_ 1187 BattTracTe02_Te_Actl 254;
BA_ "U_CD542_MY2021_Tx" SG_ 1187 BattTracTe01_Te_Actl 1;
BA_ "U_CX727_MY2021_Tx" SG_ 1187 BattTracTe01_Te_Actl 1;
BA_ "U_U55X_MY2022_Rx" SG_ 1187 BattTracTe01_Te_Actl 1;
BA_ "U_CD542_MY2021_Rx" SG_ 1187 BattTracTe01_Te_Actl 1;
BA_ "ECGUsedRxSignal" SG_ 1187 BattTracTe01_Te_Actl 1;
BA_ "GenSigStartValue" SG_ 1187 BattTracTe01_Te_Actl 254;
BA_ "GenSigStartValueInteger" SG_ 1187 BattTracTe01_Te_Actl 254;
BA_ "U_CD542_MY2021_Tx" SG_ 1187 BattTracCell96_U_Actl 1;
BA_ "U_CX727_MY2021_Tx" SG_ 1187 BattTracCell96_U_Actl 1;
BA_ "U_U55X_MY2022_Rx" SG_ 1187 BattTracCell96_U_Actl 1;
BA_ "U_CD542_MY2021_Rx" SG_ 1187 BattTracCell96_U_Actl 1;
BA_ "ECGUsedRxSignal" SG_ 1187 BattTracCell96_U_Actl 1;
BA_ "GenSigStartValue" SG_ 1187 BattTracCell96_U_Actl 4094;
BA_ "GenSigStartValueInteger" SG_ 1187 BattTracCell96_U_Actl 4094;
BA_ "U_CD542_MY2021_Tx" SG_ 1169 BattTracCell10_U_Actl 1;
BA_ "U_CX727_MY2021_Tx" SG_ 1169 BattTracCell10_U_Actl 1;
BA_ "U_U55X_MY2022_Rx" SG_ 1169 BattTracCell10_U_Actl 1;
BA_ "U_CD542_MY2021_Rx" SG_ 1169 BattTracCell10_U_Actl 1;
BA_ "ECGUsedRxSignal" SG_ 1169 BattTracCell10_U_Actl 1;
BA_ "GenSigStartValue" SG_ 1169 BattTracCell10_U_Actl 4094;
BA_ "GenSigStartValueInteger" SG_ 1169 BattTracCell10_U_Actl 4094;
BA_ "U_CD542_MY2021_Tx" SG_ 1169 BattTracCell09_U_Actl 1;
BA_ "U_CX727_MY2021_Tx" SG_ 1169 BattTracCell09_U_Actl 1;
BA_ "U_U55X_MY2022_Rx" SG_ 1169 BattTracCell09_U_Actl 1;
BA_ "U_CD542_MY2021_Rx" SG_ 1169 BattTracCell09_U_Actl 1;
BA_ "ECGUsedRxSignal" SG_ 1169 BattTracCell09_U_Actl 1;
BA_ "GenSigStartValue" SG_ 1169 BattTracCell09_U_Actl 4094;
BA_ "GenSigStartValueInteger" SG_ 1169 BattTracCell09_U_Actl 4094;
BA_ "U_CD542_MY2021_Tx" SG_ 1169 BattTracCell08_U_Actl 1;
BA_ "U_CX727_MY2021_Tx" SG_ 1169 BattTracCell08_U_Actl 1;
BA_ "U_U55X_MY2022_Rx" SG_ 1169 BattTracCell08_U_Actl 1;
BA_ "U_CD542_MY2021_Rx" SG_ 1169 BattTracCell08_U_Actl 1;
BA_ "ECGUsedRxSignal" SG_ 1169 BattTracCell08_U_Actl 1;
BA_ "GenSigStartValue" SG_ 1169 BattTracCell08_U_Actl 4094;
BA_ "GenSigStartValueInteger" SG_ 1169 BattTracCell08_U_Actl 4094;
BA_ "U_CD542_MY2021_Tx" SG_ 1169 BattTracCell07_U_Actl 1;
BA_ "U_CX727_MY2021_Tx" SG_ 1169 BattTracCell07_U_Actl 1;
BA_ "U_U55X_MY2022_Rx" SG_ 1169 BattTracCell07_U_Actl 1;
BA_ "U_CD542_MY2021_Rx" SG_ 1169 BattTracCell07_U_Actl 1;
BA_ "ECGUsedRxSignal" SG_ 1169 BattTracCell07_U_Actl 1;
BA_ "GenSigStartValue" SG_ 1169 BattTracCell07_U_Actl 4094;
BA_ "GenSigStartValueInteger" SG_ 1169 BattTracCell07_U_Actl 4094;
BA_ "U_CD542_MY2021_Tx" SG_ 1169 BattTracCell06_U_Actl 1;
BA_ "U_CX727_MY2021_Tx" SG_ 1169 BattTracCell06_U_Actl 1;
BA_ "U_U55X_MY2022_Rx" SG_ 1169 BattTracCell06_U_Actl 1;
BA_ "U_CD542_MY2021_Rx" SG_ 1169 BattTracCell06_U_Actl 1;
BA_ "ECGUsedRxSignal" SG_ 1169 BattTracCell06_U_Actl 1;
BA_ "GenSigStartValue" SG_ 1169 BattTracCell06_U_Actl 4094;
BA_ "GenSigStartValueInteger" SG_ 1169 BattTracCell06_U_Actl 4094;
BA_ "U_CD542_MY2021_Tx" SG_ 1186 BattTracCell95_U_Actl 1;
BA_ "U_CX727_MY2021_Tx" SG_ 1186 BattTracCell95_U_Actl 1;
BA_ "U_U55X_MY2022_Rx" SG_ 1186 BattTracCell95_U_Actl 1;
BA_ "U_CD542_MY2021_Rx" SG_ 1186 BattTracCell95_U_Actl 1;
BA_ "ECGUsedRxSignal" SG_ 1186 BattTracCell95_U_Actl 1;
BA_ "GenSigStartValue" SG_ 1186 BattTracCell95_U_Actl 4094;
BA_ "GenSigStartValueInteger" SG_ 1186 BattTracCell95_U_Actl 4094;
BA_ "U_CD542_MY2021_Tx" SG_ 1186 BattTracCell94_U_Actl 1;
BA_ "U_CX727_MY2021_Tx" SG_ 1186 BattTracCell94_U_Actl 1;
BA_ "U_U55X_MY2022_Rx" SG_ 1186 BattTracCell94_U_Actl 1;
BA_ "U_CD542_MY2021_Rx" SG_ 1186 BattTracCell94_U_Actl 1;
BA_ "ECGUsedRxSignal" SG_ 1186 BattTracCell94_U_Actl 1;
BA_ "GenSigStartValue" SG_ 1186 BattTracCell94_U_Actl 4094;
BA_ "GenSigStartValueInteger" SG_ 1186 BattTracCell94_U_Actl 4094;
BA_ "U_CD542_MY2021_Tx" SG_ 1186 BattTracCell93_U_Actl 1;
BA_ "U_CX727_MY2021_Tx" SG_ 1186 BattTracCell93_U_Actl 1;
BA_ "U_U55X_MY2022_Rx" SG_ 1186 BattTracCell93_U_Actl 1;
BA_ "U_CD542_MY2021_Rx" SG_ 1186 BattTracCell93_U_Actl 1;
BA_ "ECGUsedRxSignal" SG_ 1186 BattTracCell93_U_Actl 1;
BA_ "GenSigStartValue" SG_ 1186 BattTracCell93_U_Actl 4094;
BA_ "GenSigStartValueInteger" SG_ 1186 BattTracCell93_U_Actl 4094;
BA_ "U_CD542_MY2021_Tx" SG_ 1186 BattTracCell92_U_Actl 1;
BA_ "U_CX727_MY2021_Tx" SG_ 1186 BattTracCell92_U_Actl 1;
BA_ "U_U55X_MY2022_Rx" SG_ 1186 BattTracCell92_U_Actl 1;
BA_ "U_CD542_MY2021_Rx" SG_ 1186 BattTracCell92_U_Actl 1;
BA_ "ECGUsedRxSignal" SG_ 1186 BattTracCell92_U_Actl 1;
BA_ "GenSigStartValue" SG_ 1186 BattTracCell92_U_Actl 4094;
BA_ "GenSigStartValueInteger" SG_ 1186 BattTracCell92_U_Actl 4094;
BA_ "U_CD542_MY2021_Tx" SG_ 1186 BattTracCell91_U_Actl 1;
BA_ "U_CX727_MY2021_Tx" SG_ 1186 BattTracCell91_U_Actl 1;
BA_ "U_U55X_MY2022_Rx" SG_ 1186 BattTracCell91_U_Actl 1;
BA_ "U_CD542_MY2021_Rx" SG_ 1186 BattTracCell91_U_Actl 1;
BA_ "ECGUsedRxSignal" SG_ 1186 BattTracCell91_U_Actl 1;
BA_ "GenSigStartValue" SG_ 1186 BattTracCell91_U_Actl 4094;
BA_ "GenSigStartValueInteger" SG_ 1186 BattTracCell91_U_Actl 4094;
BA_ "U_CD542_MY2021_Tx" SG_ 1185 BattTracCell90_U_Actl 1;
BA_ "U_CX727_MY2021_Tx" SG_ 1185 BattTracCell90_U_Actl 1;
BA_ "U_U55X_MY2022_Rx" SG_ 1185 BattTracCell90_U_Actl 1;
BA_ "U_CD542_MY2021_Rx" SG_ 1185 BattTracCell90_U_Actl 1;
BA_ "ECGUsedRxSignal" SG_ 1185 BattTracCell90_U_Actl 1;
BA_ "GenSigStartValue" SG_ 1185 BattTracCell90_U_Actl 4094;
BA_ "GenSigStartValueInteger" SG_ 1185 BattTracCell90_U_Actl 4094;
BA_ "U_CD542_MY2021_Tx" SG_ 1185 BattTracCell89_U_Actl 1;
BA_ "U_CX727_MY2021_Tx" SG_ 1185 BattTracCell89_U_Actl 1;
BA_ "U_U55X_MY2022_Rx" SG_ 1185 BattTracCell89_U_Actl 1;
BA_ "U_CD542_MY2021_Rx" SG_ 1185 BattTracCell89_U_Actl 1;
BA_ "ECGUsedRxSignal" SG_ 1185 BattTracCell89_U_Actl 1;
BA_ "GenSigStartValue" SG_ 1185 BattTracCell89_U_Actl 4094;
BA_ "GenSigStartValueInteger" SG_ 1185 BattTracCell89_U_Actl 4094;
BA_ "U_CD542_MY2021_Tx" SG_ 1185 BattTracCell88_U_Actl 1;
BA_ "U_CX727_MY2021_Tx" SG_ 1185 BattTracCell88_U_Actl 1;
BA_ "U_U55X_MY2022_Rx" SG_ 1185 BattTracCell88_U_Actl 1;
BA_ "U_CD542_MY2021_Rx" SG_ 1185 BattTracCell88_U_Actl 1;
BA_ "ECGUsedRxSignal" SG_ 1185 BattTracCell88_U_Actl 1;
BA_ "GenSigStartValue" SG_ 1185 BattTracCell88_U_Actl 4094;
BA_ "GenSigStartValueInteger" SG_ 1185 BattTracCell88_U_Actl 4094;
BA_ "U_CD542_MY2021_Tx" SG_ 1185 BattTracCell87_U_Actl 1;
BA_ "U_CX727_MY2021_Tx" SG_ 1185 BattTracCell87_U_Actl 1;
BA_ "U_U55X_MY2022_Rx" SG_ 1185 BattTracCell87_U_Actl 1;
BA_ "U_CD542_MY2021_Rx" SG_ 1185 BattTracCell87_U_Actl 1;
BA_ "ECGUsedRxSignal" SG_ 1185 BattTracCell87_U_Actl 1;
BA_ "GenSigStartValue" SG_ 1185 BattTracCell87_U_Actl 4094;
BA_ "GenSigStartValueInteger" SG_ 1185 BattTracCell87_U_Actl 4094;
BA_ "U_CD542_MY2021_Tx" SG_ 1185 BattTracCell86_U_Actl 1;
BA_ "U_CX727_MY2021_Tx" SG_ 1185 BattTracCell86_U_Actl 1;
BA_ "U_U55X_MY2022_Rx" SG_ 1185 BattTracCell86_U_Actl 1;
BA_ "U_CD542_MY2021_Rx" SG_ 1185 BattTracCell86_U_Actl 1;
BA_ "ECGUsedRxSignal" SG_ 1185 BattTracCell86_U_Actl 1;
BA_ "GenSigStartValue" SG_ 1185 BattTracCell86_U_Actl 4094;
BA_ "GenSigStartValueInteger" SG_ 1185 BattTracCell86_U_Actl 4094;
BA_ "U_CD542_MY2021_Tx" SG_ 1184 BattTracCell85_U_Actl 1;
BA_ "U_CX727_MY2021_Tx" SG_ 1184 BattTracCell85_U_Actl 1;
BA_ "U_U55X_MY2022_Rx" SG_ 1184 BattTracCell85_U_Actl 1;
BA_ "U_CD542_MY2021_Rx" SG_ 1184 BattTracCell85_U_Actl 1;
BA_ "ECGUsedRxSignal" SG_ 1184 BattTracCell85_U_Actl 1;
BA_ "GenSigStartValue" SG_ 1184 BattTracCell85_U_Actl 4094;
BA_ "GenSigStartValueInteger" SG_ 1184 BattTracCell85_U_Actl 4094;
BA_ "U_CD542_MY2021_Tx" SG_ 1184 BattTracCell84_U_Actl 1;
BA_ "U_CX727_MY2021_Tx" SG_ 1184 BattTracCell84_U_Actl 1;
BA_ "U_U55X_MY2022_Rx" SG_ 1184 BattTracCell84_U_Actl 1;
BA_ "U_CD542_MY2021_Rx" SG_ 1184 BattTracCell84_U_Actl 1;
BA_ "ECGUsedRxSignal" SG_ 1184 BattTracCell84_U_Actl 1;
BA_ "GenSigStartValue" SG_ 1184 BattTracCell84_U_Actl 4094;
BA_ "GenSigStartValueInteger" SG_ 1184 BattTracCell84_U_Actl 4094;
BA_ "U_CD542_MY2021_Tx" SG_ 1184 BattTracCell83_U_Actl 1;
BA_ "U_CX727_MY2021_Tx" SG_ 1184 BattTracCell83_U_Actl 1;
BA_ "U_U55X_MY2022_Rx" SG_ 1184 BattTracCell83_U_Actl 1;
BA_ "U_CD542_MY2021_Rx" SG_ 1184 BattTracCell83_U_Actl 1;
BA_ "ECGUsedRxSignal" SG_ 1184 BattTracCell83_U_Actl 1;
BA_ "GenSigStartValue" SG_ 1184 BattTracCell83_U_Actl 4094;
BA_ "GenSigStartValueInteger" SG_ 1184 BattTracCell83_U_Actl 4094;
BA_ "U_CD542_MY2021_Tx" SG_ 1184 BattTracCell82_U_Actl 1;
BA_ "U_CX727_MY2021_Tx" SG_ 1184 BattTracCell82_U_Actl 1;
BA_ "U_U55X_MY2022_Rx" SG_ 1184 BattTracCell82_U_Actl 1;
BA_ "U_CD542_MY2021_Rx" SG_ 1184 BattTracCell82_U_Actl 1;
BA_ "ECGUsedRxSignal" SG_ 1184 BattTracCell82_U_Actl 1;
BA_ "GenSigStartValue" SG_ 1184 BattTracCell82_U_Actl 4094;
BA_ "GenSigStartValueInteger" SG_ 1184 BattTracCell82_U_Actl 4094;
BA_ "U_CD542_MY2021_Tx" SG_ 1184 BattTracCell81_U_Actl 1;
BA_ "U_CX727_MY2021_Tx" SG_ 1184 BattTracCell81_U_Actl 1;
BA_ "U_U55X_MY2022_Rx" SG_ 1184 BattTracCell81_U_Actl 1;
BA_ "U_CD542_MY2021_Rx" SG_ 1184 BattTracCell81_U_Actl 1;
BA_ "ECGUsedRxSignal" SG_ 1184 BattTracCell81_U_Actl 1;
BA_ "GenSigStartValue" SG_ 1184 BattTracCell81_U_Actl 4094;
BA_ "GenSigStartValueInteger" SG_ 1184 BattTracCell81_U_Actl 4094;
BA_ "U_CD542_MY2021_Tx" SG_ 1183 BattTracCell80_U_Actl 1;
BA_ "U_CX727_MY2021_Tx" SG_ 1183 BattTracCell80_U_Actl 1;
BA_ "U_U55X_MY2022_Rx" SG_ 1183 BattTracCell80_U_Actl 1;
BA_ "U_CD542_MY2021_Rx" SG_ 1183 BattTracCell80_U_Actl 1;
BA_ "ECGUsedRxSignal" SG_ 1183 BattTracCell80_U_Actl 1;
BA_ "GenSigStartValue" SG_ 1183 BattTracCell80_U_Actl 4094;
BA_ "GenSigStartValueInteger" SG_ 1183 BattTracCell80_U_Actl 4094;
BA_ "U_CD542_MY2021_Tx" SG_ 1183 BattTracCell79_U_Actl 1;
BA_ "U_CX727_MY2021_Tx" SG_ 1183 BattTracCell79_U_Actl 1;
BA_ "U_U55X_MY2022_Rx" SG_ 1183 BattTracCell79_U_Actl 1;
BA_ "U_CD542_MY2021_Rx" SG_ 1183 BattTracCell79_U_Actl 1;
BA_ "ECGUsedRxSignal" SG_ 1183 BattTracCell79_U_Actl 1;
BA_ "GenSigStartValue" SG_ 1183 BattTracCell79_U_Actl 4094;
BA_ "GenSigStartValueInteger" SG_ 1183 BattTracCell79_U_Actl 4094;
BA_ "U_CD542_MY2021_Tx" SG_ 1183 BattTracCell78_U_Actl 1;
BA_ "U_CX727_MY2021_Tx" SG_ 1183 BattTracCell78_U_Actl 1;
BA_ "U_U55X_MY2022_Rx" SG_ 1183 BattTracCell78_U_Actl 1;
BA_ "U_CD542_MY2021_Rx" SG_ 1183 BattTracCell78_U_Actl 1;
BA_ "ECGUsedRxSignal" SG_ 1183 BattTracCell78_U_Actl 1;
BA_ "GenSigStartValue" SG_ 1183 BattTracCell78_U_Actl 4094;
BA_ "GenSigStartValueInteger" SG_ 1183 BattTracCell78_U_Actl 4094;
BA_ "U_CD542_MY2021_Tx" SG_ 1183 BattTracCell77_U_Actl 1;
BA_ "U_CX727_MY2021_Tx" SG_ 1183 BattTracCell77_U_Actl 1;
BA_ "U_U55X_MY2022_Rx" SG_ 1183 BattTracCell77_U_Actl 1;
BA_ "U_CD542_MY2021_Rx" SG_ 1183 BattTracCell77_U_Actl 1;
BA_ "ECGUsedRxSignal" SG_ 1183 BattTracCell77_U_Actl 1;
BA_ "GenSigStartValue" SG_ 1183 BattTracCell77_U_Actl 4094;
BA_ "GenSigStartValueInteger" SG_ 1183 BattTracCell77_U_Actl 4094;
BA_ "U_CD542_MY2021_Tx" SG_ 1183 BattTracCell76_U_Actl 1;
BA_ "U_CX727_MY2021_Tx" SG_ 1183 BattTracCell76_U_Actl 1;
BA_ "U_U55X_MY2022_Rx" SG_ 1183 BattTracCell76_U_Actl 1;
BA_ "U_CD542_MY2021_Rx" SG_ 1183 BattTracCell76_U_Actl 1;
BA_ "ECGUsedRxSignal" SG_ 1183 BattTracCell76_U_Actl 1;
BA_ "GenSigStartValue" SG_ 1183 BattTracCell76_U_Actl 4094;
BA_ "GenSigStartValueInteger" SG_ 1183 BattTracCell76_U_Actl 4094;
BA_ "U_CD542_MY2021_Tx" SG_ 1182 BattTracCell75_U_Actl 1;
BA_ "U_CX727_MY2021_Tx" SG_ 1182 BattTracCell75_U_Actl 1;
BA_ "U_U55X_MY2022_Rx" SG_ 1182 BattTracCell75_U_Actl 1;
BA_ "U_CD542_MY2021_Rx" SG_ 1182 BattTracCell75_U_Actl 1;
BA_ "ECGUsedRxSignal" SG_ 1182 BattTracCell75_U_Actl 1;
BA_ "GenSigStartValue" SG_ 1182 BattTracCell75_U_Actl 4094;
BA_ "GenSigStartValueInteger" SG_ 1182 BattTracCell75_U_Actl 4094;
BA_ "U_CD542_MY2021_Tx" SG_ 1182 BattTracCell74_U_Actl 1;
BA_ "U_CX727_MY2021_Tx" SG_ 1182 BattTracCell74_U_Actl 1;
BA_ "U_U55X_MY2022_Rx" SG_ 1182 BattTracCell74_U_Actl 1;
BA_ "U_CD542_MY2021_Rx" SG_ 1182 BattTracCell74_U_Actl 1;
BA_ "ECGUsedRxSignal" SG_ 1182 BattTracCell74_U_Actl 1;
BA_ "GenSigStartValue" SG_ 1182 BattTracCell74_U_Actl 4094;
BA_ "GenSigStartValueInteger" SG_ 1182 BattTracCell74_U_Actl 4094;
BA_ "U_CD542_MY2021_Tx" SG_ 1182 BattTracCell73_U_Actl 1;
BA_ "U_CX727_MY2021_Tx" SG_ 1182 BattTracCell73_U_Actl 1;
BA_ "U_U55X_MY2022_Rx" SG_ 1182 BattTracCell73_U_Actl 1;
BA_ "U_CD542_MY2021_Rx" SG_ 1182 BattTracCell73_U_Actl 1;
BA_ "ECGUsedRxSignal" SG_ 1182 BattTracCell73_U_Actl 1;
BA_ "GenSigStartValue" SG_ 1182 BattTracCell73_U_Actl 4094;
BA_ "GenSigStartValueInteger" SG_ 1182 BattTracCell73_U_Actl 4094;
BA_ "U_CD542_MY2021_Tx" SG_ 1182 BattTracCell72_U_Actl 1;
BA_ "U_CX727_MY2021_Tx" SG_ 1182 BattTracCell72_U_Actl 1;
BA_ "U_U55X_MY2022_Rx" SG_ 1182 BattTracCell72_U_Actl 1;
BA_ "U_CD542_MY2021_Rx" SG_ 1182 BattTracCell72_U_Actl 1;
BA_ "ECGUsedRxSignal" SG_ 1182 BattTracCell72_U_Actl 1;
BA_ "GenSigStartValue" SG_ 1182 BattTracCell72_U_Actl 4094;
BA_ "GenSigStartValueInteger" SG_ 1182 BattTracCell72_U_Actl 4094;
BA_ "U_CD542_MY2021_Tx" SG_ 1182 BattTracCell71_U_Actl 1;
BA_ "U_CX727_MY2021_Tx" SG_ 1182 BattTracCell71_U_Actl 1;
BA_ "U_U55X_MY2022_Rx" SG_ 1182 BattTracCell71_U_Actl 1;
BA_ "U_CD542_MY2021_Rx" SG_ 1182 BattTracCell71_U_Actl 1;
BA_ "ECGUsedRxSignal" SG_ 1182 BattTracCell71_U_Actl 1;
BA_ "GenSigStartValue" SG_ 1182 BattTracCell71_U_Actl 4094;
BA_ "GenSigStartValueInteger" SG_ 1182 BattTracCell71_U_Actl 4094;
BA_ "U_CD542_MY2021_Tx" SG_ 1181 BattTracCell70_U_Actl 1;
BA_ "U_CX727_MY2021_Tx" SG_ 1181 BattTracCell70_U_Actl 1;
BA_ "U_U55X_MY2022_Rx" SG_ 1181 BattTracCell70_U_Actl 1;
BA_ "U_CD542_MY2021_Rx" SG_ 1181 BattTracCell70_U_Actl 1;
BA_ "ECGUsedRxSignal" SG_ 1181 BattTracCell70_U_Actl 1;
BA_ "GenSigStartValue" SG_ 1181 BattTracCell70_U_Actl 4094;
BA_ "GenSigStartValueInteger" SG_ 1181 BattTracCell70_U_Actl 4094;
BA_ "U_CD542_MY2021_Tx" SG_ 1181 BattTracCell69_U_Actl 1;
BA_ "U_CX727_MY2021_Tx" SG_ 1181 BattTracCell69_U_Actl 1;
BA_ "U_U55X_MY2022_Rx" SG_ 1181 BattTracCell69_U_Actl 1;
BA_ "U_CD542_MY2021_Rx" SG_ 1181 BattTracCell69_U_Actl 1;
BA_ "ECGUsedRxSignal" SG_ 1181 BattTracCell69_U_Actl 1;
BA_ "GenSigStartValue" SG_ 1181 BattTracCell69_U_Actl 4094;
BA_ "GenSigStartValueInteger" SG_ 1181 BattTracCell69_U_Actl 4094;
BA_ "U_CD542_MY2021_Tx" SG_ 1181 BattTracCell68_U_Actl 1;
BA_ "U_CX727_MY2021_Tx" SG_ 1181 BattTracCell68_U_Actl 1;
BA_ "U_U55X_MY2022_Rx" SG_ 1181 BattTracCell68_U_Actl 1;
BA_ "U_CD542_MY2021_Rx" SG_ 1181 BattTracCell68_U_Actl 1;
BA_ "ECGUsedRxSignal" SG_ 1181 BattTracCell68_U_Actl 1;
BA_ "GenSigStartValue" SG_ 1181 BattTracCell68_U_Actl 4094;
BA_ "GenSigStartValueInteger" SG_ 1181 BattTracCell68_U_Actl 4094;
BA_ "U_CD542_MY2021_Tx" SG_ 1181 BattTracCell67_U_Actl 1;
BA_ "U_CX727_MY2021_Tx" SG_ 1181 BattTracCell67_U_Actl 1;
BA_ "U_U55X_MY2022_Rx" SG_ 1181 BattTracCell67_U_Actl 1;
BA_ "U_CD542_MY2021_Rx" SG_ 1181 BattTracCell67_U_Actl 1;
BA_ "ECGUsedRxSignal" SG_ 1181 BattTracCell67_U_Actl 1;
BA_ "GenSigStartValue" SG_ 1181 BattTracCell67_U_Actl 4094;
BA_ "GenSigStartValueInteger" SG_ 1181 BattTracCell67_U_Actl 4094;
BA_ "U_CD542_MY2021_Tx" SG_ 1181 BattTracCell66_U_Actl 1;
BA_ "U_CX727_MY2021_Tx" SG_ 1181 BattTracCell66_U_Actl 1;
BA_ "U_U55X_MY2022_Rx" SG_ 1181 BattTracCell66_U_Actl 1;
BA_ "U_CD542_MY2021_Rx" SG_ 1181 BattTracCell66_U_Actl 1;
BA_ "ECGUsedRxSignal" SG_ 1181 BattTracCell66_U_Actl 1;
BA_ "GenSigStartValue" SG_ 1181 BattTracCell66_U_Actl 4094;
BA_ "GenSigStartValueInteger" SG_ 1181 BattTracCell66_U_Actl 4094;
BA_ "U_CD542_MY2021_Tx" SG_ 1180 BattTracCell65_U_Actl 1;
BA_ "U_CX727_MY2021_Tx" SG_ 1180 BattTracCell65_U_Actl 1;
BA_ "U_U55X_MY2022_Rx" SG_ 1180 BattTracCell65_U_Actl 1;
BA_ "U_CD542_MY2021_Rx" SG_ 1180 BattTracCell65_U_Actl 1;
BA_ "ECGUsedRxSignal" SG_ 1180 BattTracCell65_U_Actl 1;
BA_ "GenSigStartValue" SG_ 1180 BattTracCell65_U_Actl 4094;
BA_ "GenSigStartValueInteger" SG_ 1180 BattTracCell65_U_Actl 4094;
BA_ "U_CD542_MY2021_Tx" SG_ 1180 BattTracCell64_U_Actl 1;
BA_ "U_CX727_MY2021_Tx" SG_ 1180 BattTracCell64_U_Actl 1;
BA_ "U_U55X_MY2022_Rx" SG_ 1180 BattTracCell64_U_Actl 1;
BA_ "U_CD542_MY2021_Rx" SG_ 1180 BattTracCell64_U_Actl 1;
BA_ "ECGUsedRxSignal" SG_ 1180 BattTracCell64_U_Actl 1;
BA_ "GenSigStartValue" SG_ 1180 BattTracCell64_U_Actl 4094;
BA_ "GenSigStartValueInteger" SG_ 1180 BattTracCell64_U_Actl 4094;
BA_ "U_CD542_MY2021_Tx" SG_ 1180 BattTracCell63_U_Actl 1;
BA_ "U_CX727_MY2021_Tx" SG_ 1180 BattTracCell63_U_Actl 1;
BA_ "U_U55X_MY2022_Rx" SG_ 1180 BattTracCell63_U_Actl 1;
BA_ "U_CD542_MY2021_Rx" SG_ 1180 BattTracCell63_U_Actl 1;
BA_ "ECGUsedRxSignal" SG_ 1180 BattTracCell63_U_Actl 1;
BA_ "GenSigStartValue" SG_ 1180 BattTracCell63_U_Actl 4094;
BA_ "GenSigStartValueInteger" SG_ 1180 BattTracCell63_U_Actl 4094;
BA_ "U_CD542_MY2021_Tx" SG_ 1180 BattTracCell62_U_Actl 1;
BA_ "U_CX727_MY2021_Tx" SG_ 1180 BattTracCell62_U_Actl 1;
BA_ "U_U55X_MY2022_Rx" SG_ 1180 BattTracCell62_U_Actl 1;
BA_ "U_CD542_MY2021_Rx" SG_ 1180 BattTracCell62_U_Actl 1;
BA_ "ECGUsedRxSignal" SG_ 1180 BattTracCell62_U_Actl 1;
BA_ "GenSigStartValue" SG_ 1180 BattTracCell62_U_Actl 4094;
BA_ "GenSigStartValueInteger" SG_ 1180 BattTracCell62_U_Actl 4094;
BA_ "U_CD542_MY2021_Tx" SG_ 1180 BattTracCell61_U_Actl 1;
BA_ "U_CX727_MY2021_Tx" SG_ 1180 BattTracCell61_U_Actl 1;
BA_ "U_U55X_MY2022_Rx" SG_ 1180 BattTracCell61_U_Actl 1;
BA_ "U_CD542_MY2021_Rx" SG_ 1180 BattTracCell61_U_Actl 1;
BA_ "ECGUsedRxSignal" SG_ 1180 BattTracCell61_U_Actl 1;
BA_ "GenSigStartValue" SG_ 1180 BattTracCell61_U_Actl 4094;
BA_ "GenSigStartValueInteger" SG_ 1180 BattTracCell61_U_Actl 4094;
BA_ "U_CD542_MY2021_Tx" SG_ 1179 BattTracCell60_U_Actl 1;
BA_ "U_CX727_MY2021_Tx" SG_ 1179 BattTracCell60_U_Actl 1;
BA_ "U_U55X_MY2022_Rx" SG_ 1179 BattTracCell60_U_Actl 1;
BA_ "U_CD542_MY2021_Rx" SG_ 1179 BattTracCell60_U_Actl 1;
BA_ "ECGUsedRxSignal" SG_ 1179 BattTracCell60_U_Actl 1;
BA_ "GenSigStartValue" SG_ 1179 BattTracCell60_U_Actl 4094;
BA_ "GenSigStartValueInteger" SG_ 1179 BattTracCell60_U_Actl 4094;
BA_ "U_CD542_MY2021_Tx" SG_ 1179 BattTracCell59_U_Actl 1;
BA_ "U_CX727_MY2021_Tx" SG_ 1179 BattTracCell59_U_Actl 1;
BA_ "U_U55X_MY2022_Rx" SG_ 1179 BattTracCell59_U_Actl 1;
BA_ "U_CD542_MY2021_Rx" SG_ 1179 BattTracCell59_U_Actl 1;
BA_ "ECGUsedRxSignal" SG_ 1179 BattTracCell59_U_Actl 1;
BA_ "GenSigStartValue" SG_ 1179 BattTracCell59_U_Actl 4094;
BA_ "GenSigStartValueInteger" SG_ 1179 BattTracCell59_U_Actl 4094;
BA_ "U_CD542_MY2021_Tx" SG_ 1179 BattTracCell58_U_Actl 1;
BA_ "U_CX727_MY2021_Tx" SG_ 1179 BattTracCell58_U_Actl 1;
BA_ "U_U55X_MY2022_Rx" SG_ 1179 BattTracCell58_U_Actl 1;
BA_ "U_CD542_MY2021_Rx" SG_ 1179 BattTracCell58_U_Actl 1;
BA_ "ECGUsedRxSignal" SG_ 1179 BattTracCell58_U_Actl 1;
BA_ "GenSigStartValue" SG_ 1179 BattTracCell58_U_Actl 4094;
BA_ "GenSigStartValueInteger" SG_ 1179 BattTracCell58_U_Actl 4094;
BA_ "U_CD542_MY2021_Tx" SG_ 1179 BattTracCell57_U_Actl 1;
BA_ "U_CX727_MY2021_Tx" SG_ 1179 BattTracCell57_U_Actl 1;
BA_ "U_U55X_MY2022_Rx" SG_ 1179 BattTracCell57_U_Actl 1;
BA_ "U_CD542_MY2021_Rx" SG_ 1179 BattTracCell57_U_Actl 1;
BA_ "ECGUsedRxSignal" SG_ 1179 BattTracCell57_U_Actl 1;
BA_ "GenSigStartValue" SG_ 1179 BattTracCell57_U_Actl 4094;
BA_ "GenSigStartValueInteger" SG_ 1179 BattTracCell57_U_Actl 4094;
BA_ "U_CD542_MY2021_Tx" SG_ 1179 BattTracCell56_U_Actl 1;
BA_ "U_CX727_MY2021_Tx" SG_ 1179 BattTracCell56_U_Actl 1;
BA_ "U_U55X_MY2022_Rx" SG_ 1179 BattTracCell56_U_Actl 1;
BA_ "U_CD542_MY2021_Rx" SG_ 1179 BattTracCell56_U_Actl 1;
BA_ "ECGUsedRxSignal" SG_ 1179 BattTracCell56_U_Actl 1;
BA_ "GenSigStartValue" SG_ 1179 BattTracCell56_U_Actl 4094;
BA_ "GenSigStartValueInteger" SG_ 1179 BattTracCell56_U_Actl 4094;
BA_ "U_CD542_MY2021_Tx" SG_ 1178 BattTracCell55_U_Actl 1;
BA_ "U_CX727_MY2021_Tx" SG_ 1178 BattTracCell55_U_Actl 1;
BA_ "U_U55X_MY2022_Rx" SG_ 1178 BattTracCell55_U_Actl 1;
BA_ "U_CD542_MY2021_Rx" SG_ 1178 BattTracCell55_U_Actl 1;
BA_ "ECGUsedRxSignal" SG_ 1178 BattTracCell55_U_Actl 1;
BA_ "GenSigStartValue" SG_ 1178 BattTracCell55_U_Actl 4094;
BA_ "GenSigStartValueInteger" SG_ 1178 BattTracCell55_U_Actl 4094;
BA_ "U_CD542_MY2021_Tx" SG_ 1178 BattTracCell54_U_Actl 1;
BA_ "U_CX727_MY2021_Tx" SG_ 1178 BattTracCell54_U_Actl 1;
BA_ "U_U55X_MY2022_Rx" SG_ 1178 BattTracCell54_U_Actl 1;
BA_ "U_CD542_MY2021_Rx" SG_ 1178 BattTracCell54_U_Actl 1;
BA_ "ECGUsedRxSignal" SG_ 1178 BattTracCell54_U_Actl 1;
BA_ "GenSigStartValue" SG_ 1178 BattTracCell54_U_Actl 4094;
BA_ "GenSigStartValueInteger" SG_ 1178 BattTracCell54_U_Actl 4094;
BA_ "U_CD542_MY2021_Tx" SG_ 1178 BattTracCell53_U_Actl 1;
BA_ "U_CX727_MY2021_Tx" SG_ 1178 BattTracCell53_U_Actl 1;
BA_ "U_U55X_MY2022_Rx" SG_ 1178 BattTracCell53_U_Actl 1;
BA_ "U_CD542_MY2021_Rx" SG_ 1178 BattTracCell53_U_Actl 1;
BA_ "ECGUsedRxSignal" SG_ 1178 BattTracCell53_U_Actl 1;
BA_ "GenSigStartValue" SG_ 1178 BattTracCell53_U_Actl 4094;
BA_ "GenSigStartValueInteger" SG_ 1178 BattTracCell53_U_Actl 4094;
BA_ "U_CD542_MY2021_Tx" SG_ 1178 BattTracCell52_U_Actl 1;
BA_ "U_CX727_MY2021_Tx" SG_ 1178 BattTracCell52_U_Actl 1;
BA_ "U_U55X_MY2022_Rx" SG_ 1178 BattTracCell52_U_Actl 1;
BA_ "U_CD542_MY2021_Rx" SG_ 1178 BattTracCell52_U_Actl 1;
BA_ "ECGUsedRxSignal" SG_ 1178 BattTracCell52_U_Actl 1;
BA_ "GenSigStartValue" SG_ 1178 BattTracCell52_U_Actl 4094;
BA_ "GenSigStartValueInteger" SG_ 1178 BattTracCell52_U_Actl 4094;
BA_ "U_CD542_MY2021_Tx" SG_ 1178 BattTracCell51_U_Actl 1;
BA_ "U_CX727_MY2021_Tx" SG_ 1178 BattTracCell51_U_Actl 1;
BA_ "U_U55X_MY2022_Rx" SG_ 1178 BattTracCell51_U_Actl 1;
BA_ "U_CD542_MY2021_Rx" SG_ 1178 BattTracCell51_U_Actl 1;
BA_ "ECGUsedRxSignal" SG_ 1178 BattTracCell51_U_Actl 1;
BA_ "GenSigStartValue" SG_ 1178 BattTracCell51_U_Actl 4094;
BA_ "GenSigStartValueInteger" SG_ 1178 BattTracCell51_U_Actl 4094;
BA_ "U_CD542_MY2021_Tx" SG_ 1177 BattTracCell50_U_Actl 1;
BA_ "U_CX727_MY2021_Tx" SG_ 1177 BattTracCell50_U_Actl 1;
BA_ "U_U55X_MY2022_Rx" SG_ 1177 BattTracCell50_U_Actl 1;
BA_ "U_CD542_MY2021_Rx" SG_ 1177 BattTracCell50_U_Actl 1;
BA_ "ECGUsedRxSignal" SG_ 1177 BattTracCell50_U_Actl 1;
BA_ "GenSigStartValue" SG_ 1177 BattTracCell50_U_Actl 4094;
BA_ "GenSigStartValueInteger" SG_ 1177 BattTracCell50_U_Actl 4094;
BA_ "U_CD542_MY2021_Tx" SG_ 1177 BattTracCell49_U_Actl 1;
BA_ "U_CX727_MY2021_Tx" SG_ 1177 BattTracCell49_U_Actl 1;
BA_ "U_U55X_MY2022_Rx" SG_ 1177 BattTracCell49_U_Actl 1;
BA_ "U_CD542_MY2021_Rx" SG_ 1177 BattTracCell49_U_Actl 1;
BA_ "ECGUsedRxSignal" SG_ 1177 BattTracCell49_U_Actl 1;
BA_ "GenSigStartValue" SG_ 1177 BattTracCell49_U_Actl 4094;
BA_ "GenSigStartValueInteger" SG_ 1177 BattTracCell49_U_Actl 4094;
BA_ "U_CD542_MY2021_Tx" SG_ 1177 BattTracCell48_U_Actl 1;
BA_ "U_CX727_MY2021_Tx" SG_ 1177 BattTracCell48_U_Actl 1;
BA_ "U_U55X_MY2022_Rx" SG_ 1177 BattTracCell48_U_Actl 1;
BA_ "U_CD542_MY2021_Rx" SG_ 1177 BattTracCell48_U_Actl 1;
BA_ "ECGUsedRxSignal" SG_ 1177 BattTracCell48_U_Actl 1;
BA_ "GenSigStartValue" SG_ 1177 BattTracCell48_U_Actl 4094;
BA_ "GenSigStartValueInteger" SG_ 1177 BattTracCell48_U_Actl 4094;
BA_ "U_CD542_MY2021_Tx" SG_ 1177 BattTracCell47_U_Actl 1;
BA_ "U_CX727_MY2021_Tx" SG_ 1177 BattTracCell47_U_Actl 1;
BA_ "U_U55X_MY2022_Rx" SG_ 1177 BattTracCell47_U_Actl 1;
BA_ "U_CD542_MY2021_Rx" SG_ 1177 BattTracCell47_U_Actl 1;
BA_ "ECGUsedRxSignal" SG_ 1177 BattTracCell47_U_Actl 1;
BA_ "GenSigStartValue" SG_ 1177 BattTracCell47_U_Actl 4094;
BA_ "GenSigStartValueInteger" SG_ 1177 BattTracCell47_U_Actl 4094;
BA_ "U_CD542_MY2021_Tx" SG_ 1177 BattTracCell46_U_Actl 1;
BA_ "U_CX727_MY2021_Tx" SG_ 1177 BattTracCell46_U_Actl 1;
BA_ "U_U55X_MY2022_Rx" SG_ 1177 BattTracCell46_U_Actl 1;
BA_ "U_CD542_MY2021_Rx" SG_ 1177 BattTracCell46_U_Actl 1;
BA_ "ECGUsedRxSignal" SG_ 1177 BattTracCell46_U_Actl 1;
BA_ "GenSigStartValue" SG_ 1177 BattTracCell46_U_Actl 4094;
BA_ "GenSigStartValueInteger" SG_ 1177 BattTracCell46_U_Actl 4094;
BA_ "U_CD542_MY2021_Tx" SG_ 1168 BattTracCell05_U_Actl 1;
BA_ "U_CX727_MY2021_Tx" SG_ 1168 BattTracCell05_U_Actl 1;
BA_ "U_U55X_MY2022_Rx" SG_ 1168 BattTracCell05_U_Actl 1;
BA_ "U_CD542_MY2021_Rx" SG_ 1168 BattTracCell05_U_Actl 1;
BA_ "ECGUsedRxSignal" SG_ 1168 BattTracCell05_U_Actl 1;
BA_ "GenSigStartValue" SG_ 1168 BattTracCell05_U_Actl 4094;
BA_ "GenSigStartValueInteger" SG_ 1168 BattTracCell05_U_Actl 4094;
BA_ "U_CD542_MY2021_Tx" SG_ 1168 BattTracCell04_U_Actl 1;
BA_ "U_CX727_MY2021_Tx" SG_ 1168 BattTracCell04_U_Actl 1;
BA_ "U_U55X_MY2022_Rx" SG_ 1168 BattTracCell04_U_Actl 1;
BA_ "U_CD542_MY2021_Rx" SG_ 1168 BattTracCell04_U_Actl 1;
BA_ "ECGUsedRxSignal" SG_ 1168 BattTracCell04_U_Actl 1;
BA_ "GenSigStartValue" SG_ 1168 BattTracCell04_U_Actl 4094;
BA_ "GenSigStartValueInteger" SG_ 1168 BattTracCell04_U_Actl 4094;
BA_ "U_CD542_MY2021_Tx" SG_ 1168 BattTracCell03_U_Actl 1;
BA_ "U_CX727_MY2021_Tx" SG_ 1168 BattTracCell03_U_Actl 1;
BA_ "U_U55X_MY2022_Rx" SG_ 1168 BattTracCell03_U_Actl 1;
BA_ "U_CD542_MY2021_Rx" SG_ 1168 BattTracCell03_U_Actl 1;
BA_ "ECGUsedRxSignal" SG_ 1168 BattTracCell03_U_Actl 1;
BA_ "GenSigStartValue" SG_ 1168 BattTracCell03_U_Actl 4094;
BA_ "GenSigStartValueInteger" SG_ 1168 BattTracCell03_U_Actl 4094;
BA_ "U_CD542_MY2021_Tx" SG_ 1168 BattTracCell02_U_Actl 1;
BA_ "U_CX727_MY2021_Tx" SG_ 1168 BattTracCell02_U_Actl 1;
BA_ "U_U55X_MY2022_Rx" SG_ 1168 BattTracCell02_U_Actl 1;
BA_ "U_CD542_MY2021_Rx" SG_ 1168 BattTracCell02_U_Actl 1;
BA_ "ECGUsedRxSignal" SG_ 1168 BattTracCell02_U_Actl 1;
BA_ "GenSigStartValue" SG_ 1168 BattTracCell02_U_Actl 4094;
BA_ "GenSigStartValueInteger" SG_ 1168 BattTracCell02_U_Actl 4094;
BA_ "U_CD542_MY2021_Tx" SG_ 1168 BattTracCell01_U_Actl 1;
BA_ "U_CX727_MY2021_Tx" SG_ 1168 BattTracCell01_U_Actl 1;
BA_ "U_U55X_MY2022_Rx" SG_ 1168 BattTracCell01_U_Actl 1;
BA_ "U_CD542_MY2021_Rx" SG_ 1168 BattTracCell01_U_Actl 1;
BA_ "ECGUsedRxSignal" SG_ 1168 BattTracCell01_U_Actl 1;
BA_ "GenSigStartValue" SG_ 1168 BattTracCell01_U_Actl 4094;
BA_ "GenSigStartValueInteger" SG_ 1168 BattTracCell01_U_Actl 4094;
BA_ "GenSigSendType" SG_ 1768 TesterPhysicalResACCMB 3;
BA_ "GenSigSendType" SG_ 1760 TesterPhysicalReqACCMB 3;
BA_ "GenSigSendType" SG_ 1807 TesterPhysicalResGFM3DCACB 3;
BA_ "GenSigSendType" SG_ 1799 TesterPhysicalReqGFM3DCACB 3;
BA_ "U_CD542_MY2021_Rx" SG_ 2612224204 PARSEDPushDCDCtoGWM_ECG 1;
BA_ "ECGUsedRxSignal" SG_ 2612224204 PARSEDPushDCDCtoGWM_ECG 1;
BA_ "GenSigSendType" SG_ 2612224204 PARSEDPushDCDCtoGWM_ECG 3;
BA_ "U_CD542_MY2021_Rx" SG_ 2611175628 PARSEDPhysDCDCtoGWM_ECG 1;
BA_ "ECGUsedRxSignal" SG_ 2611175628 PARSEDPhysDCDCtoGWM_ECG 1;
BA_ "GenSigSendType" SG_ 2611175628 PARSEDPhysDCDCtoGWM_ECG 3;
BA_ "U_CD542_MY2021_Tx" SG_ 2610114776 OTAPhysGWM_ECGtoDCDC 1;
BA_ "ECGUsedTxSignal" SG_ 2610114776 OTAPhysGWM_ECGtoDCDC 1;
BA_ "GenSigSendType" SG_ 2610114776 OTAPhysGWM_ECGtoDCDC 3;
BA_ "U_CD542_MY2021_Rx" SG_ 2610127052 OTAPhysDCDCtoGWM_ECG 1;
BA_ "ECGUsedRxSignal" SG_ 2610127052 OTAPhysDCDCtoGWM_ECG 1;
BA_ "GenSigSendType" SG_ 2610127052 OTAPhysDCDCtoGWM_ECG 3;
BA_ "U_CD764_MY2022_Rx" SG_ 621 IgnPsswrdActv_B_Stat 1;
BA_ "U_U55X_MY2022_Rx" SG_ 621 IgnPsswrdActv_B_Stat 1;
BA_ "U_CD542_MY2021_Rx" SG_ 621 IgnPsswrdActv_B_Stat 1;
BA_ "U_T6_MCA_MY2020_Rx" SG_ 621 IgnPsswrdActv_B_Stat 1;
BA_ "U_P702_MY2021_Rx" SG_ 621 IgnPsswrdActv_B_Stat 1;
BA_ "U_CX727_MY2021_Rx" SG_ 621 IgnPsswrdActv_B_Stat 1;
BA_ "U_CD764_MY2022_Rx" SG_ 621 FobTrgtZone_D_Rq 1;
BA_ "U_U55X_MY2022_Rx" SG_ 621 FobTrgtZone_D_Rq 1;
BA_ "U_CD542_MY2021_Rx" SG_ 621 FobTrgtZone_D_Rq 1;
BA_ "U_T6_MCA_MY2020_Rx" SG_ 621 FobTrgtZone_D_Rq 1;
BA_ "U_P702_MY2021_Rx" SG_ 621 FobTrgtZone_D_Rq 1;
BA_ "U_CX727_MY2021_Rx" SG_ 621 FobTrgtZone_D_Rq 1;
BA_ "U_CD764_MY2022_Rx" SG_ 621 FobTrgtType_D_Rq 1;
BA_ "U_U55X_MY2022_Rx" SG_ 621 FobTrgtType_D_Rq 1;
BA_ "U_CD542_MY2021_Rx" SG_ 621 FobTrgtType_D_Rq 1;
BA_ "U_T6_MCA_MY2020_Rx" SG_ 621 FobTrgtType_D_Rq 1;
BA_ "U_P702_MY2021_Rx" SG_ 621 FobTrgtType_D_Rq 1;
BA_ "U_CX727_MY2021_Rx" SG_ 621 FobTrgtType_D_Rq 1;
BA_ "U_CD764_MY2022_Rx" SG_ 621 FobTrgtRollCode_No_Rq 1;
BA_ "U_U55X_MY2022_Rx" SG_ 621 FobTrgtRollCode_No_Rq 1;
BA_ "U_CD542_MY2021_Rx" SG_ 621 FobTrgtRollCode_No_Rq 1;
BA_ "U_T6_MCA_MY2020_Rx" SG_ 621 FobTrgtRollCode_No_Rq 1;
BA_ "U_P702_MY2021_Rx" SG_ 621 FobTrgtRollCode_No_Rq 1;
BA_ "U_CX727_MY2021_Rx" SG_ 621 FobTrgtRollCode_No_Rq 1;
BA_ "U_CD764_MY2022_Rx" SG_ 621 FobTrgtPssvData_No_Rq 1;
BA_ "U_U55X_MY2022_Rx" SG_ 621 FobTrgtPssvData_No_Rq 1;
BA_ "U_CD542_MY2021_Rx" SG_ 621 FobTrgtPssvData_No_Rq 1;
BA_ "U_T6_MCA_MY2020_Rx" SG_ 621 FobTrgtPssvData_No_Rq 1;
BA_ "U_P702_MY2021_Rx" SG_ 621 FobTrgtPssvData_No_Rq 1;
BA_ "U_CX727_MY2021_Rx" SG_ 621 FobTrgtPssvData_No_Rq 1;
BA_ "GenSigSendType" SG_ 1763 TesterPhysicalReqFHCM 3;
BA_ "GenSigSendType" SG_ 1771 TesterPhysicalResFHCM 3;
BA_ "GenSigStartValue" SG_ 1531 FHCM_GWOnBoardTester 255;
BA_ "ContentDependant" SG_ 1531 FHCM_GWOnBoardTester 1;
BA_ "GenSigStartValueInteger" SG_ 1531 FHCM_GWOnBoardTester 255;
BA_ "GenSigStartValue" SG_ 1531 FHCM_GWNMProxy 255;
BA_ "ContentDependant" SG_ 1531 FHCM_GWNMProxy 1;
BA_ "GenSigStartValueInteger" SG_ 1531 FHCM_GWNMProxy 255;
BA_ "GenSigStartValue" SG_ 1531 FHCM_AutoSarNMReserved4 255;
BA_ "ContentDependant" SG_ 1531 FHCM_AutoSarNMReserved4 1;
BA_ "GenSigStartValueInteger" SG_ 1531 FHCM_AutoSarNMReserved4 255;
BA_ "GenSigStartValue" SG_ 1531 FHCM_AutoSarNMReserved3 255;
BA_ "ContentDependant" SG_ 1531 FHCM_AutoSarNMReserved3 1;
BA_ "GenSigStartValueInteger" SG_ 1531 FHCM_AutoSarNMReserved3 255;
BA_ "GenSigStartValue" SG_ 1531 FHCM_AutoSarNMReserved2 255;
BA_ "ContentDependant" SG_ 1531 FHCM_AutoSarNMReserved2 1;
BA_ "GenSigStartValueInteger" SG_ 1531 FHCM_AutoSarNMReserved2 255;
BA_ "GenSigStartValue" SG_ 1531 FHCM_AutoSarNMReserved1 255;
BA_ "ContentDependant" SG_ 1531 FHCM_AutoSarNMReserved1 1;
BA_ "GenSigStartValueInteger" SG_ 1531 FHCM_AutoSarNMReserved1 255;
BA_ "GenSigStartValue" SG_ 1531 FHCM_AutoSarNMNodeId 251;
BA_ "ContentDependant" SG_ 1531 FHCM_AutoSarNMNodeId 1;
BA_ "GenSigStartValueInteger" SG_ 1531 FHCM_AutoSarNMNodeId 150;
BA_ "ContentDependant" SG_ 1531 FHCM_AutoSarNMControl 1;
BA_ "U_CD542_MY2021_Tx" SG_ 2611163352 PARSEDPhysGWM_ECGtoDCDC 1;
BA_ "ECGUsedTxSignal" SG_ 2611163352 PARSEDPhysGWM_ECGtoDCDC 1;
BA_ "GenSigSendType" SG_ 2611163352 PARSEDPhysGWM_ECGtoDCDC 3;
BA_ "U_CD542_MY2021_Tx" SG_ 2612211928 PARSEDPushFcGWM_ECGtoDCDC 1;
BA_ "ECGUsedTxSignal" SG_ 2612211928 PARSEDPushFcGWM_ECGtoDCDC 1;
BA_ "GenSigSendType" SG_ 2612211928 PARSEDPushFcGWM_ECGtoDCDC 3;
BA_ "GenSigStartValue" SG_ 1149 BattTracPerf_Pc_Dsply 254;
BA_ "GenSigStartValue" SG_ 1149 BattTracPerf_Pc_Actl 254;
BA_ "U_CD764_MY2022_Rx" SG_ 626 PaakCtlRollCd2_No_Copy 1;
BA_ "U_CD542_MY2021_Rx" SG_ 626 PaakCtlRollCd2_No_Copy 1;
BA_ "WakeupSignal" SG_ 626 PaakCtlRollCd2_No_Copy 1;
BA_ "U_CD764_MY2022_Rx" SG_ 626 PaakCtlIndx8_D_Stat 1;
BA_ "U_CD542_MY2021_Rx" SG_ 626 PaakCtlIndx8_D_Stat 1;
BA_ "WakeupSignal" SG_ 626 PaakCtlIndx8_D_Stat 1;
BA_ "U_CD764_MY2022_Rx" SG_ 626 PaakCtlIndx7_D_Stat 1;
BA_ "U_CD542_MY2021_Rx" SG_ 626 PaakCtlIndx7_D_Stat 1;
BA_ "WakeupSignal" SG_ 626 PaakCtlIndx7_D_Stat 1;
BA_ "U_CD764_MY2022_Rx" SG_ 626 PaakCtlIndx6_D_Stat 1;
BA_ "U_CD542_MY2021_Rx" SG_ 626 PaakCtlIndx6_D_Stat 1;
BA_ "WakeupSignal" SG_ 626 PaakCtlIndx6_D_Stat 1;
BA_ "U_CD764_MY2022_Rx" SG_ 626 PaakCtlIndx5_D_Stat 1;
BA_ "U_CD542_MY2021_Rx" SG_ 626 PaakCtlIndx5_D_Stat 1;
BA_ "WakeupSignal" SG_ 626 PaakCtlIndx5_D_Stat 1;
BA_ "U_CD764_MY2022_Rx" SG_ 626 PaakCtlIndx4_D_Stat 1;
BA_ "U_CD542_MY2021_Rx" SG_ 626 PaakCtlIndx4_D_Stat 1;
BA_ "WakeupSignal" SG_ 626 PaakCtlIndx4_D_Stat 1;
BA_ "U_CD764_MY2022_Rx" SG_ 626 PaakCtlIndx3_D_Stat 1;
BA_ "U_CD542_MY2021_Rx" SG_ 626 PaakCtlIndx3_D_Stat 1;
BA_ "WakeupSignal" SG_ 626 PaakCtlIndx3_D_Stat 1;
BA_ "U_CD764_MY2022_Rx" SG_ 626 PaakCtlIndx2_D_Stat 1;
BA_ "U_CD542_MY2021_Rx" SG_ 626 PaakCtlIndx2_D_Stat 1;
BA_ "WakeupSignal" SG_ 626 PaakCtlIndx2_D_Stat 1;
BA_ "U_CD764_MY2022_Rx" SG_ 626 PaakCtlIndx1_D_Stat 1;
BA_ "U_CD542_MY2021_Rx" SG_ 626 PaakCtlIndx1_D_Stat 1;
BA_ "WakeupSignal" SG_ 626 PaakCtlIndx1_D_Stat 1;
BA_ "GenSigStartValue" SG_ 770 ScMnSoc_Pc_Actl 100;
BA_ "GenSigStartValue" SG_ 770 CurntTrgtSoc_Pc_Rq 100;
BA_ "GenSigStartValue" SG_ 770 CurntTrgtSoc_Pc_Dsply 100;
BA_ "U_CD764_MY2022_Rx" SG_ 1161 DrSwtchInnrRr_No_Rq_UB 1;
BA_ "U_CD542_MY2021_Rx" SG_ 1161 DrSwtchInnrRr_No_Rq_UB 1;
BA_ "U_CD764_MY2022_Rx" SG_ 1161 DrSwtchInnrRr_No_Rq 1;
BA_ "U_CD542_MY2021_Rx" SG_ 1161 DrSwtchInnrRr_No_Rq 1;
BA_ "GenSigSendType" SG_ 1161 DrSwtchInnrRr_No_Rq 3;
BA_ "WakeupSignal" SG_ 1161 DrSwtchInnrRr_No_Rq 1;
BA_ "U_CD764_MY2022_Rx" SG_ 1161 DrSwtchInnrRl_No_Rq_UB 1;
BA_ "U_CD542_MY2021_Rx" SG_ 1161 DrSwtchInnrRl_No_Rq_UB 1;
BA_ "U_CD764_MY2022_Rx" SG_ 1161 DrSwtchInnrRl_No_Rq 1;
BA_ "U_CD542_MY2021_Rx" SG_ 1161 DrSwtchInnrRl_No_Rq 1;
BA_ "GenSigSendType" SG_ 1161 DrSwtchInnrRl_No_Rq 3;
BA_ "WakeupSignal" SG_ 1161 DrSwtchInnrRl_No_Rq 1;
BA_ "U_CD764_MY2022_Rx" SG_ 1161 DrLatchRolCdRr_No_Locl_UB 1;
BA_ "U_CD542_MY2021_Rx" SG_ 1161 DrLatchRolCdRr_No_Locl_UB 1;
BA_ "U_CD764_MY2022_Rx" SG_ 1161 DrLatchRolCdRr_No_Locl 1;
BA_ "U_CD542_MY2021_Rx" SG_ 1161 DrLatchRolCdRr_No_Locl 1;
BA_ "GenSigSendType" SG_ 1161 DrLatchRolCdRr_No_Locl 3;
BA_ "U_CD764_MY2022_Rx" SG_ 1161 DrLatchRolCdRl_No_Locl_UB 1;
BA_ "U_CD542_MY2021_Rx" SG_ 1161 DrLatchRolCdRl_No_Locl_UB 1;
BA_ "U_CD764_MY2022_Rx" SG_ 1161 DrLatchRolCdRl_No_Locl 1;
BA_ "U_CD542_MY2021_Rx" SG_ 1161 DrLatchRolCdRl_No_Locl 1;
BA_ "GenSigSendType" SG_ 1161 DrLatchRolCdRl_No_Locl 3;
BA_ "U_CD764_MY2022_Tx" SG_ 960 DrLatchRolCdRr_No_Actl 1;
BA_ "U_CD542_MY2021_Tx" SG_ 960 DrLatchRolCdRr_No_Actl 1;
BA_ "GenSigSendType" SG_ 960 DrLatchRolCdRr_No_Actl 3;
BA_ "U_CD764_MY2022_Tx" SG_ 960 DrLatchRolCdRl_No_Actl 1;
BA_ "U_CD542_MY2021_Tx" SG_ 960 DrLatchRolCdRl_No_Actl 1;
BA_ "GenSigSendType" SG_ 960 DrLatchRolCdRl_No_Actl 3;
BA_ "U_CD764_MY2022_Tx" SG_ 960 DrLatchRolCdFr_No_Actl 1;
BA_ "U_CD542_MY2021_Tx" SG_ 960 DrLatchRolCdFr_No_Actl 1;
BA_ "GenSigSendType" SG_ 960 DrLatchRolCdFr_No_Actl 3;
BA_ "U_CD764_MY2022_Tx" SG_ 960 DrLatchRolCdFl_No_Actl 1;
BA_ "U_CD542_MY2021_Tx" SG_ 960 DrLatchRolCdFl_No_Actl 1;
BA_ "GenSigSendType" SG_ 960 DrLatchRolCdFl_No_Actl 3;
BA_ "U_CD764_MY2022_Tx" SG_ 957 DrSwtchInnrRr_No_Actl 1;
BA_ "U_CD542_MY2021_Tx" SG_ 957 DrSwtchInnrRr_No_Actl 1;
BA_ "GenSigSendType" SG_ 957 DrSwtchInnrRr_No_Actl 3;
BA_ "U_CD764_MY2022_Tx" SG_ 957 DrSwtchInnrRl_No_Actl 1;
BA_ "U_CD542_MY2021_Tx" SG_ 957 DrSwtchInnrRl_No_Actl 1;
BA_ "GenSigSendType" SG_ 957 DrSwtchInnrRl_No_Actl 3;
BA_ "U_CD764_MY2022_Tx" SG_ 957 DrSwtchInnrFr_No_Actl 1;
BA_ "U_CD542_MY2021_Tx" SG_ 957 DrSwtchInnrFr_No_Actl 1;
BA_ "GenSigSendType" SG_ 957 DrSwtchInnrFr_No_Actl 3;
BA_ "U_CD764_MY2022_Tx" SG_ 957 DrSwtchInnrFl_No_Actl 1;
BA_ "U_CD542_MY2021_Tx" SG_ 957 DrSwtchInnrFl_No_Actl 1;
BA_ "GenSigSendType" SG_ 957 DrSwtchInnrFl_No_Actl 3;
BA_ "U_CD764_MY2022_Tx" SG_ 957 DrSwtchExtRr_No_Actl 1;
BA_ "U_CD542_MY2021_Tx" SG_ 957 DrSwtchExtRr_No_Actl 1;
BA_ "GenSigSendType" SG_ 957 DrSwtchExtRr_No_Actl 3;
BA_ "U_CD764_MY2022_Tx" SG_ 957 DrSwtchExtRl_No_Actl 1;
BA_ "U_CD542_MY2021_Tx" SG_ 957 DrSwtchExtRl_No_Actl 1;
BA_ "GenSigSendType" SG_ 957 DrSwtchExtRl_No_Actl 3;
BA_ "U_CD764_MY2022_Tx" SG_ 957 DrSwtchExtFr_No_Actl 1;
BA_ "U_CD542_MY2021_Tx" SG_ 957 DrSwtchExtFr_No_Actl 1;
BA_ "GenSigSendType" SG_ 957 DrSwtchExtFr_No_Actl 3;
BA_ "U_CD764_MY2022_Tx" SG_ 957 DrSwtchExtFl_No_Actl 1;
BA_ "U_CD542_MY2021_Tx" SG_ 957 DrSwtchExtFl_No_Actl 1;
BA_ "GenSigSendType" SG_ 957 DrSwtchExtFl_No_Actl 3;
BA_ "U_CD764_MY2022_Rx" SG_ 1159 WakeAlarm2_B_Typ_UB 1;
BA_ "U_U55X_MY2022_Rx" SG_ 1159 WakeAlarm2_B_Typ_UB 1;
BA_ "U_CD764_MY2022_Rx" SG_ 1159 WakeAlarm2_T_Rq_UB 1;
BA_ "U_U55X_MY2022_Rx" SG_ 1159 WakeAlarm2_T_Rq_UB 1;
BA_ "U_CD764_MY2022_Rx" SG_ 1159 WakeAlarm2_T_Rq 1;
BA_ "U_U55X_MY2022_Rx" SG_ 1159 WakeAlarm2_T_Rq 1;
BA_ "GenSigSendType" SG_ 1159 WakeAlarm2_T_Rq 3;
BA_ "GenSigStartValue" SG_ 1159 WakeAlarm2_T_Rq 32767;
BA_ "GenSigStartValueInteger" SG_ 1159 WakeAlarm2_T_Rq 32767;
BA_ "U_CD764_MY2022_Rx" SG_ 1159 WakeAlarm2_B_Typ 1;
BA_ "U_U55X_MY2022_Rx" SG_ 1159 WakeAlarm2_B_Typ 1;
BA_ "GenSigSendType" SG_ 1159 WakeAlarm2_B_Typ 3;
BA_ "U_CD764_MY2022_Rx" SG_ 1159 DrLatchRolCdFr_No_Locl_UB 1;
BA_ "U_CD542_MY2021_Rx" SG_ 1159 DrLatchRolCdFr_No_Locl_UB 1;
BA_ "U_CD764_MY2022_Rx" SG_ 1159 DrLatchRolCdFr_No_Locl 1;
BA_ "U_CD542_MY2021_Rx" SG_ 1159 DrLatchRolCdFr_No_Locl 1;
BA_ "GenSigSendType" SG_ 1159 DrLatchRolCdFr_No_Locl 3;
BA_ "U_CD764_MY2022_Rx" SG_ 1159 DrLatchRolCdFl_No_Locl_UB 1;
BA_ "U_CD542_MY2021_Rx" SG_ 1159 DrLatchRolCdFl_No_Locl_UB 1;
BA_ "U_CD764_MY2022_Rx" SG_ 1159 DrLatchRolCdFl_No_Locl 1;
BA_ "U_CD542_MY2021_Rx" SG_ 1159 DrLatchRolCdFl_No_Locl 1;
BA_ "GenSigSendType" SG_ 1159 DrLatchRolCdFl_No_Locl 3;
BA_ "U_CD764_MY2022_Rx" SG_ 1159 DrSwtchInnrFr_No_Rq_UB 1;
BA_ "U_CD542_MY2021_Rx" SG_ 1159 DrSwtchInnrFr_No_Rq_UB 1;
BA_ "U_CD764_MY2022_Rx" SG_ 1159 DrSwtchInnrFl_No_Rq_UB 1;
BA_ "U_CD542_MY2021_Rx" SG_ 1159 DrSwtchInnrFl_No_Rq_UB 1;
BA_ "U_CD764_MY2022_Rx" SG_ 1159 DrSwtchInnrFr_No_Rq 1;
BA_ "U_CD542_MY2021_Rx" SG_ 1159 DrSwtchInnrFr_No_Rq 1;
BA_ "GenSigSendType" SG_ 1159 DrSwtchInnrFr_No_Rq 3;
BA_ "WakeupSignal" SG_ 1159 DrSwtchInnrFr_No_Rq 1;
BA_ "U_CD764_MY2022_Rx" SG_ 1159 DrSwtchInnrFl_No_Rq 1;
BA_ "U_CD542_MY2021_Rx" SG_ 1159 DrSwtchInnrFl_No_Rq 1;
BA_ "GenSigSendType" SG_ 1159 DrSwtchInnrFl_No_Rq 3;
BA_ "WakeupSignal" SG_ 1159 DrSwtchInnrFl_No_Rq 1;
BA_ "U_CX727_MY2021_Tx" SG_ 72 immoTarget2Status 1;
BA_ "U_CD764_MY2022_Rx" SG_ 72 immoTarget2Status 1;
BA_ "U_U55X_MY2022_Rx" SG_ 72 immoTarget2Status 1;
BA_ "U_CD542_MY2021_Rx" SG_ 72 immoTarget2Status 1;
BA_ "U_T6_MCA_MY2020_Rx" SG_ 72 immoTarget2Status 1;
BA_ "U_P702_MY2021_Rx" SG_ 72 immoTarget2Status 1;
BA_ "U_CX727_MY2021_Rx" SG_ 72 immoTarget2Status 1;
BA_ "U_CX727_MY2021_Tx" SG_ 72 immoTarget2Data 1;
BA_ "U_CD764_MY2022_Rx" SG_ 72 immoTarget2Data 1;
BA_ "U_U55X_MY2022_Rx" SG_ 72 immoTarget2Data 1;
BA_ "U_CD542_MY2021_Rx" SG_ 72 immoTarget2Data 1;
BA_ "U_T6_MCA_MY2020_Rx" SG_ 72 immoTarget2Data 1;
BA_ "U_P702_MY2021_Rx" SG_ 72 immoTarget2Data 1;
BA_ "U_CX727_MY2021_Rx" SG_ 72 immoTarget2Data 1;
BA_ "U_CX727_MY2021_Tx" SG_ 72 immoTarget2Cmd 1;
BA_ "U_CD764_MY2022_Rx" SG_ 72 immoTarget2Cmd 1;
BA_ "U_U55X_MY2022_Rx" SG_ 72 immoTarget2Cmd 1;
BA_ "U_CD542_MY2021_Rx" SG_ 72 immoTarget2Cmd 1;
BA_ "U_T6_MCA_MY2020_Rx" SG_ 72 immoTarget2Cmd 1;
BA_ "U_P702_MY2021_Rx" SG_ 72 immoTarget2Cmd 1;
BA_ "U_CX727_MY2021_Rx" SG_ 72 immoTarget2Cmd 1;
BA_ "U_U55X_MY2022_Rx" SG_ 2611175634 PARSEDPhysDCACAtoGWM_ECG 1;
BA_ "ECGUsedRxSignal" SG_ 2611175634 PARSEDPhysDCACAtoGWM_ECG 1;
BA_ "GenSigSendType" SG_ 2611175634 PARSEDPhysDCACAtoGWM_ECG 3;
BA_ "U_U55X_MY2022_Tx" SG_ 2611169496 PARSEDPhysGWM_ECGtoDCACA 1;
BA_ "U_CD542_MY2021_Tx" SG_ 2611169496 PARSEDPhysGWM_ECGtoDCACA 1;
BA_ "ECGUsedTxSignal" SG_ 2611169496 PARSEDPhysGWM_ECGtoDCACA 1;
BA_ "GenSigSendType" SG_ 2611169496 PARSEDPhysGWM_ECGtoDCACA 3;
BA_ "U_U55X_MY2022_Rx" SG_ 2612224210 PARSEDPushDCACAtoGWM_ECG 1;
BA_ "ECGUsedRxSignal" SG_ 2612224210 PARSEDPushDCACAtoGWM_ECG 1;
BA_ "GenSigSendType" SG_ 2612224210 PARSEDPushDCACAtoGWM_ECG 3;
BA_ "U_U55X_MY2022_Tx" SG_ 2612218072 PARSEDPushFcGWM_ECGtoDCACA 1;
BA_ "ECGUsedTxSignal" SG_ 2612218072 PARSEDPushFcGWM_ECGtoDCACA 1;
BA_ "GenSigSendType" SG_ 2612218072 PARSEDPushFcGWM_ECGtoDCACA 3;
BA_ "U_U55X_MY2022_Rx" SG_ 2610127058 OTAPhysDCACAtoGWM_ECG 1;
BA_ "ECGUsedRxSignal" SG_ 2610127058 OTAPhysDCACAtoGWM_ECG 1;
BA_ "GenSigSendType" SG_ 2610127058 OTAPhysDCACAtoGWM_ECG 3;
BA_ "U_U55X_MY2022_Tx" SG_ 2610120920 OTAPhysGWM_ECGtoDCACA 1;
BA_ "U_CD542_MY2021_Tx" SG_ 2610120920 OTAPhysGWM_ECGtoDCACA 1;
BA_ "ECGUsedTxSignal" SG_ 2610120920 OTAPhysGWM_ECGtoDCACA 1;
BA_ "GenSigSendType" SG_ 2610120920 OTAPhysGWM_ECGtoDCACA 3;
BA_ "U_CD764_MY2022_Rx" SG_ 1130 PaakCtlType_D_Stat 1;
BA_ "U_U55X_MY2022_Rx" SG_ 1130 PaakCtlType_D_Stat 1;
BA_ "U_CD542_MY2021_Rx" SG_ 1130 PaakCtlType_D_Stat 1;
BA_ "U_T6_MCA_MY2020_Rx" SG_ 1130 PaakCtlType_D_Stat 1;
BA_ "U_P702_MY2021_Rx" SG_ 1130 PaakCtlType_D_Stat 1;
BA_ "U_CX727_MY2021_Rx" SG_ 1130 PaakCtlType_D_Stat 1;
BA_ "WakeupSignal" SG_ 1130 PaakCtlType_D_Stat 1;
BA_ "U_CD764_MY2022_Rx" SG_ 1130 PaakCtlRollCode_No_Stat 1;
BA_ "U_U55X_MY2022_Rx" SG_ 1130 PaakCtlRollCode_No_Stat 1;
BA_ "U_CD542_MY2021_Rx" SG_ 1130 PaakCtlRollCode_No_Stat 1;
BA_ "U_T6_MCA_MY2020_Rx" SG_ 1130 PaakCtlRollCode_No_Stat 1;
BA_ "U_P702_MY2021_Rx" SG_ 1130 PaakCtlRollCode_No_Stat 1;
BA_ "U_CX727_MY2021_Rx" SG_ 1130 PaakCtlRollCode_No_Stat 1;
BA_ "WakeupSignal" SG_ 1130 PaakCtlRollCode_No_Stat 1;
BA_ "U_CD764_MY2022_Rx" SG_ 1130 PaakCtlPssvData_No_Actl 1;
BA_ "U_U55X_MY2022_Rx" SG_ 1130 PaakCtlPssvData_No_Actl 1;
BA_ "U_CD542_MY2021_Rx" SG_ 1130 PaakCtlPssvData_No_Actl 1;
BA_ "U_T6_MCA_MY2020_Rx" SG_ 1130 PaakCtlPssvData_No_Actl 1;
BA_ "U_P702_MY2021_Rx" SG_ 1130 PaakCtlPssvData_No_Actl 1;
BA_ "U_CX727_MY2021_Rx" SG_ 1130 PaakCtlPssvData_No_Actl 1;
BA_ "ContentDependant" SG_ 1130 PaakCtlPssvData_No_Actl 1;
BA_ "WakeupSignal" SG_ 1130 PaakCtlPssvData_No_Actl 1;
BA_ "U_CD764_MY2022_Rx" SG_ 1130 PaakCtlData_D_Stat 1;
BA_ "U_U55X_MY2022_Rx" SG_ 1130 PaakCtlData_D_Stat 1;
BA_ "U_CD542_MY2021_Rx" SG_ 1130 PaakCtlData_D_Stat 1;
BA_ "U_T6_MCA_MY2020_Rx" SG_ 1130 PaakCtlData_D_Stat 1;
BA_ "U_P702_MY2021_Rx" SG_ 1130 PaakCtlData_D_Stat 1;
BA_ "U_CX727_MY2021_Rx" SG_ 1130 PaakCtlData_D_Stat 1;
BA_ "WakeupSignal" SG_ 1130 PaakCtlData_D_Stat 1;
BA_ "U_CD764_MY2022_Rx" SG_ 1130 PaakLoclzd_D_Stat 1;
BA_ "U_U55X_MY2022_Rx" SG_ 1130 PaakLoclzd_D_Stat 1;
BA_ "U_CD542_MY2021_Rx" SG_ 1130 PaakLoclzd_D_Stat 1;
BA_ "WakeupSignal" SG_ 1130 PaakLoclzd_D_Stat 1;
BA_ "U_CD764_MY2022_Rx" SG_ 1132 PaakCtlIndx8_No_Actl 1;
BA_ "U_CD542_MY2021_Rx" SG_ 1132 PaakCtlIndx8_No_Actl 1;
BA_ "U_T6_MCA_MY2020_Rx" SG_ 1132 PaakCtlIndx8_No_Actl 1;
BA_ "U_P702_MY2021_Rx" SG_ 1132 PaakCtlIndx8_No_Actl 1;
BA_ "U_CX727_MY2021_Rx" SG_ 1132 PaakCtlIndx8_No_Actl 1;
BA_ "U_CD764_MY2022_Rx" SG_ 1132 PaakCtlIndx7_No_Actl 1;
BA_ "U_CD542_MY2021_Rx" SG_ 1132 PaakCtlIndx7_No_Actl 1;
BA_ "U_T6_MCA_MY2020_Rx" SG_ 1132 PaakCtlIndx7_No_Actl 1;
BA_ "U_P702_MY2021_Rx" SG_ 1132 PaakCtlIndx7_No_Actl 1;
BA_ "U_CX727_MY2021_Rx" SG_ 1132 PaakCtlIndx7_No_Actl 1;
BA_ "U_CD764_MY2022_Rx" SG_ 1132 PaakCtlIndx6_No_Actl 1;
BA_ "U_CD542_MY2021_Rx" SG_ 1132 PaakCtlIndx6_No_Actl 1;
BA_ "U_T6_MCA_MY2020_Rx" SG_ 1132 PaakCtlIndx6_No_Actl 1;
BA_ "U_P702_MY2021_Rx" SG_ 1132 PaakCtlIndx6_No_Actl 1;
BA_ "U_CX727_MY2021_Rx" SG_ 1132 PaakCtlIndx6_No_Actl 1;
BA_ "U_CD764_MY2022_Rx" SG_ 1132 PaakCtlIndx5_No_Actl 1;
BA_ "U_CD542_MY2021_Rx" SG_ 1132 PaakCtlIndx5_No_Actl 1;
BA_ "U_T6_MCA_MY2020_Rx" SG_ 1132 PaakCtlIndx5_No_Actl 1;
BA_ "U_P702_MY2021_Rx" SG_ 1132 PaakCtlIndx5_No_Actl 1;
BA_ "U_CX727_MY2021_Rx" SG_ 1132 PaakCtlIndx5_No_Actl 1;
BA_ "U_CD764_MY2022_Rx" SG_ 1132 PaakCtlIndx4_No_Actl 1;
BA_ "U_CD542_MY2021_Rx" SG_ 1132 PaakCtlIndx4_No_Actl 1;
BA_ "U_T6_MCA_MY2020_Rx" SG_ 1132 PaakCtlIndx4_No_Actl 1;
BA_ "U_P702_MY2021_Rx" SG_ 1132 PaakCtlIndx4_No_Actl 1;
BA_ "U_CX727_MY2021_Rx" SG_ 1132 PaakCtlIndx4_No_Actl 1;
BA_ "U_CD764_MY2022_Rx" SG_ 1132 PaakCtlIndx3_No_Actl 1;
BA_ "U_CD542_MY2021_Rx" SG_ 1132 PaakCtlIndx3_No_Actl 1;
BA_ "U_T6_MCA_MY2020_Rx" SG_ 1132 PaakCtlIndx3_No_Actl 1;
BA_ "U_P702_MY2021_Rx" SG_ 1132 PaakCtlIndx3_No_Actl 1;
BA_ "U_CX727_MY2021_Rx" SG_ 1132 PaakCtlIndx3_No_Actl 1;
BA_ "U_CD764_MY2022_Rx" SG_ 1132 PaakCtlIndx2_No_Actl 1;
BA_ "U_CD542_MY2021_Rx" SG_ 1132 PaakCtlIndx2_No_Actl 1;
BA_ "U_T6_MCA_MY2020_Rx" SG_ 1132 PaakCtlIndx2_No_Actl 1;
BA_ "U_P702_MY2021_Rx" SG_ 1132 PaakCtlIndx2_No_Actl 1;
BA_ "U_CX727_MY2021_Rx" SG_ 1132 PaakCtlIndx2_No_Actl 1;
BA_ "U_CD764_MY2022_Rx" SG_ 1132 PaakCtlIndx1_No_Actl 1;
BA_ "U_CD542_MY2021_Rx" SG_ 1132 PaakCtlIndx1_No_Actl 1;
BA_ "U_T6_MCA_MY2020_Rx" SG_ 1132 PaakCtlIndx1_No_Actl 1;
BA_ "U_P702_MY2021_Rx" SG_ 1132 PaakCtlIndx1_No_Actl 1;
BA_ "U_CX727_MY2021_Rx" SG_ 1132 PaakCtlIndx1_No_Actl 1;
BA_ "U_CD764_MY2022_Rx" SG_ 1132 PaakCtlRollCode_No_Copy 1;
BA_ "U_CD542_MY2021_Rx" SG_ 1132 PaakCtlRollCode_No_Copy 1;
BA_ "U_T6_MCA_MY2020_Rx" SG_ 1132 PaakCtlRollCode_No_Copy 1;
BA_ "U_P702_MY2021_Rx" SG_ 1132 PaakCtlRollCode_No_Copy 1;
BA_ "U_CX727_MY2021_Rx" SG_ 1132 PaakCtlRollCode_No_Copy 1;
BA_ "U_CD764_MY2022_Tx" SG_ 1129 PaaKMyKeyChng_D_Stat 1;
BA_ "GenSigSendType" SG_ 1129 PaaKMyKeyChng_D_Stat 3;
BA_ "U_CD764_MY2022_Tx" SG_ 1129 PaaKMyKeyChng_No_Actl 1;
BA_ "GenSigSendType" SG_ 1129 PaaKMyKeyChng_No_Actl 3;
BA_ "U_CD764_MY2022_Tx" SG_ 1129 PaakAddEraseIndx_No_Actl 1;
BA_ "U_U55X_MY2022_Tx" SG_ 1129 PaakAddEraseIndx_No_Actl 1;
BA_ "U_CD542_MY2021_Tx" SG_ 1129 PaakAddEraseIndx_No_Actl 1;
BA_ "U_T6_MCA_MY2020_Tx" SG_ 1129 PaakAddEraseIndx_No_Actl 1;
BA_ "U_P702_MY2021_Tx" SG_ 1129 PaakAddEraseIndx_No_Actl 1;
BA_ "U_CX727_MY2021_Tx" SG_ 1129 PaakAddEraseIndx_No_Actl 1;
BA_ "U_CD764_MY2022_Tx" SG_ 1129 PaakAddErase_D_Stat 1;
BA_ "U_U55X_MY2022_Tx" SG_ 1129 PaakAddErase_D_Stat 1;
BA_ "U_CD542_MY2021_Tx" SG_ 1129 PaakAddErase_D_Stat 1;
BA_ "U_T6_MCA_MY2020_Tx" SG_ 1129 PaakAddErase_D_Stat 1;
BA_ "U_P702_MY2021_Tx" SG_ 1129 PaakAddErase_D_Stat 1;
BA_ "U_CX727_MY2021_Tx" SG_ 1129 PaakAddErase_D_Stat 1;
BA_ "GenSigSendType" SG_ 1129 PaakAddErase_D_Stat 3;
BA_ "U_CD764_MY2022_Tx" SG_ 1129 PaakTrgtActvData_No_Rq 1;
BA_ "U_U55X_MY2022_Tx" SG_ 1129 PaakTrgtActvData_No_Rq 1;
BA_ "U_CD542_MY2021_Tx" SG_ 1129 PaakTrgtActvData_No_Rq 1;
BA_ "U_T6_MCA_MY2020_Tx" SG_ 1129 PaakTrgtActvData_No_Rq 1;
BA_ "U_P702_MY2021_Tx" SG_ 1129 PaakTrgtActvData_No_Rq 1;
BA_ "U_CX727_MY2021_Tx" SG_ 1129 PaakTrgtActvData_No_Rq 1;
BA_ "GenSigSendType" SG_ 1129 PaakTrgtActvData_No_Rq 3;
BA_ "ContentDependant" SG_ 1129 PaakTrgtActvData_No_Rq 1;
BA_ "U_CD764_MY2022_Rx" SG_ 1131 KeyPadCodeProg_D_Rq 1;
BA_ "U_U55X_MY2022_Rx" SG_ 1131 KeyPadCodeProg_D_Rq 1;
BA_ "U_CD542_MY2021_Rx" SG_ 1131 KeyPadCodeProg_D_Rq 1;
BA_ "U_T6_MCA_MY2020_Rx" SG_ 1131 KeyPadCodeProg_D_Rq 1;
BA_ "U_P702_MY2021_Rx" SG_ 1131 KeyPadCodeProg_D_Rq 1;
BA_ "U_CX727_MY2021_Rx" SG_ 1131 KeyPadCodeProg_D_Rq 1;
BA_ "U_CD764_MY2022_Rx" SG_ 1131 PaakCtlActv_No_Actl 1;
BA_ "U_U55X_MY2022_Rx" SG_ 1131 PaakCtlActv_No_Actl 1;
BA_ "U_CD542_MY2021_Rx" SG_ 1131 PaakCtlActv_No_Actl 1;
BA_ "U_T6_MCA_MY2020_Rx" SG_ 1131 PaakCtlActv_No_Actl 1;
BA_ "U_P702_MY2021_Rx" SG_ 1131 PaakCtlActv_No_Actl 1;
BA_ "U_CX727_MY2021_Rx" SG_ 1131 PaakCtlActv_No_Actl 1;
BA_ "U_CD764_MY2022_Rx" SG_ 1131 PaakCtlActv_D_Rq 1;
BA_ "U_U55X_MY2022_Rx" SG_ 1131 PaakCtlActv_D_Rq 1;
BA_ "U_CD542_MY2021_Rx" SG_ 1131 PaakCtlActv_D_Rq 1;
BA_ "U_T6_MCA_MY2020_Rx" SG_ 1131 PaakCtlActv_D_Rq 1;
BA_ "U_P702_MY2021_Rx" SG_ 1131 PaakCtlActv_D_Rq 1;
BA_ "U_CX727_MY2021_Rx" SG_ 1131 PaakCtlActv_D_Rq 1;
BA_ "WakeupSignal" SG_ 1131 PaakCtlActv_D_Rq 1;
BA_ "U_CD764_MY2022_Rx" SG_ 1131 PaakCtlActvData_No_Actl 1;
BA_ "U_U55X_MY2022_Rx" SG_ 1131 PaakCtlActvData_No_Actl 1;
BA_ "U_CD542_MY2021_Rx" SG_ 1131 PaakCtlActvData_No_Actl 1;
BA_ "U_T6_MCA_MY2020_Rx" SG_ 1131 PaakCtlActvData_No_Actl 1;
BA_ "U_P702_MY2021_Rx" SG_ 1131 PaakCtlActvData_No_Actl 1;
BA_ "U_CX727_MY2021_Rx" SG_ 1131 PaakCtlActvData_No_Actl 1;
BA_ "ContentDependant" SG_ 1131 PaakCtlActvData_No_Actl 1;
BA_ "U_CD764_MY2022_Tx" SG_ 1128 KeyPadCodeProg_D_Stat 1;
BA_ "U_U55X_MY2022_Tx" SG_ 1128 KeyPadCodeProg_D_Stat 1;
BA_ "U_CD542_MY2021_Tx" SG_ 1128 KeyPadCodeProg_D_Stat 1;
BA_ "U_T6_MCA_MY2020_Tx" SG_ 1128 KeyPadCodeProg_D_Stat 1;
BA_ "U_P702_MY2021_Tx" SG_ 1128 KeyPadCodeProg_D_Stat 1;
BA_ "U_CX727_MY2021_Tx" SG_ 1128 KeyPadCodeProg_D_Stat 1;
BA_ "GenSigSendType" SG_ 1128 KeyPadCodeProg_D_Stat 3;
BA_ "U_CD764_MY2022_Tx" SG_ 1128 PaakTrgtPssvData_No_Rq 1;
BA_ "U_U55X_MY2022_Tx" SG_ 1128 PaakTrgtPssvData_No_Rq 1;
BA_ "U_CD542_MY2021_Tx" SG_ 1128 PaakTrgtPssvData_No_Rq 1;
BA_ "U_T6_MCA_MY2020_Tx" SG_ 1128 PaakTrgtPssvData_No_Rq 1;
BA_ "U_P702_MY2021_Tx" SG_ 1128 PaakTrgtPssvData_No_Rq 1;
BA_ "U_CX727_MY2021_Tx" SG_ 1128 PaakTrgtPssvData_No_Rq 1;
BA_ "GenSigSendType" SG_ 1128 PaakTrgtPssvData_No_Rq 3;
BA_ "ContentDependant" SG_ 1128 PaakTrgtPssvData_No_Rq 1;
BA_ "U_CD764_MY2022_Tx" SG_ 1128 PaakTrgtType_D_Rq 1;
BA_ "U_U55X_MY2022_Tx" SG_ 1128 PaakTrgtType_D_Rq 1;
BA_ "U_CD542_MY2021_Tx" SG_ 1128 PaakTrgtType_D_Rq 1;
BA_ "U_T6_MCA_MY2020_Tx" SG_ 1128 PaakTrgtType_D_Rq 1;
BA_ "U_P702_MY2021_Tx" SG_ 1128 PaakTrgtType_D_Rq 1;
BA_ "U_CX727_MY2021_Tx" SG_ 1128 PaakTrgtType_D_Rq 1;
BA_ "GenSigSendType" SG_ 1128 PaakTrgtType_D_Rq 3;
BA_ "WakeupSignal" SG_ 1128 PaakTrgtType_D_Rq 1;
BA_ "U_CD764_MY2022_Tx" SG_ 1128 PaakTrgtRollCode_No_Rq 1;
BA_ "U_U55X_MY2022_Tx" SG_ 1128 PaakTrgtRollCode_No_Rq 1;
BA_ "U_CD542_MY2021_Tx" SG_ 1128 PaakTrgtRollCode_No_Rq 1;
BA_ "U_T6_MCA_MY2020_Tx" SG_ 1128 PaakTrgtRollCode_No_Rq 1;
BA_ "U_P702_MY2021_Tx" SG_ 1128 PaakTrgtRollCode_No_Rq 1;
BA_ "U_CX727_MY2021_Tx" SG_ 1128 PaakTrgtRollCode_No_Rq 1;
BA_ "GenSigSendType" SG_ 1128 PaakTrgtRollCode_No_Rq 3;
BA_ "U_CD764_MY2022_Tx" SG_ 1128 PaakTrgtZone_D_Rq 1;
BA_ "U_U55X_MY2022_Tx" SG_ 1128 PaakTrgtZone_D_Rq 1;
BA_ "U_CD542_MY2021_Tx" SG_ 1128 PaakTrgtZone_D_Rq 1;
BA_ "U_T6_MCA_MY2020_Tx" SG_ 1128 PaakTrgtZone_D_Rq 1;
BA_ "U_P702_MY2021_Tx" SG_ 1128 PaakTrgtZone_D_Rq 1;
BA_ "U_CX727_MY2021_Tx" SG_ 1128 PaakTrgtZone_D_Rq 1;
BA_ "GenSigSendType" SG_ 1128 PaakTrgtZone_D_Rq 3;
BA_ "U_CD764_MY2022_Tx" SG_ 1128 PaakTrgtData_D_Rq 1;
BA_ "U_U55X_MY2022_Tx" SG_ 1128 PaakTrgtData_D_Rq 1;
BA_ "U_CD542_MY2021_Tx" SG_ 1128 PaakTrgtData_D_Rq 1;
BA_ "U_T6_MCA_MY2020_Tx" SG_ 1128 PaakTrgtData_D_Rq 1;
BA_ "U_P702_MY2021_Tx" SG_ 1128 PaakTrgtData_D_Rq 1;
BA_ "U_CX727_MY2021_Tx" SG_ 1128 PaakTrgtData_D_Rq 1;
BA_ "GenSigSendType" SG_ 1128 PaakTrgtData_D_Rq 3;
BA_ "U_CD764_MY2022_Tx" SG_ 1128 PaakTrgtPreAuthrz_B_Rq 1;
BA_ "U_CD542_MY2021_Tx" SG_ 1128 PaakTrgtPreAuthrz_B_Rq 1;
BA_ "GenSigSendType" SG_ 1128 PaakTrgtPreAuthrz_B_Rq 3;
BA_ "WakeupSignal" SG_ 1128 PaakTrgtPreAuthrz_B_Rq 1;
BA_ "U_U55X_MY2022_Rx" SG_ 123 BattTrac_U2_Actl 1;
BA_ "U_CD542_MY2021_Rx" SG_ 123 BattTrac_U2_Actl 1;
BA_ "ECGUsedRxSignal" SG_ 123 BattTrac_U2_Actl 1;
BA_ "GenSigStartValue" SG_ 123 BattTrac_U2_Actl 4094;
BA_ "GenSigStartValueInteger" SG_ 123 BattTrac_U2_Actl 1022;
BA_ "U_U55X_MY2022_Rx" SG_ 123 BattTrac_I2_Actl 1;
BA_ "U_CD542_MY2021_Rx" SG_ 123 BattTrac_I2_Actl 1;
BA_ "ECGUsedRxSignal" SG_ 123 BattTrac_I2_Actl 1;
BA_ "GenSigStartValue" SG_ 123 BattTrac_I2_Actl 262142;
BA_ "GenSigStartValueInteger" SG_ 123 BattTrac_I2_Actl 15000;
BA_ "U_CD764_MY2022_Tx" SG_ 2612070616 PARSEDPushFcGWM_BCMC 1;
BA_ "U_U55X_MY2022_Tx" SG_ 2612070616 PARSEDPushFcGWM_BCMC 1;
BA_ "U_CD542_MY2021_Tx" SG_ 2612070616 PARSEDPushFcGWM_BCMC 1;
BA_ "ECGUsedTxSignal" SG_ 2612070616 PARSEDPushFcGWM_BCMC 1;
BA_ "U_CD764_MY2022_Rx" SG_ 2612070616 PARSEDPushFcGWM_BCMC 1;
BA_ "U_U55X_MY2022_Rx" SG_ 2612070616 PARSEDPushFcGWM_BCMC 1;
BA_ "U_CD542_MY2021_Rx" SG_ 2612070616 PARSEDPushFcGWM_BCMC 1;
BA_ "U_T6_MCA_MY2020_Rx" SG_ 2612070616 PARSEDPushFcGWM_BCMC 1;
BA_ "GenSigSendType" SG_ 2612070616 PARSEDPushFcGWM_BCMC 3;
BA_ "ECGUsedRxSignal" SG_ 2612224077 PARSEDPushOBCCtoGWM_ECG 1;
BA_ "GenSigSendType" SG_ 2612224077 PARSEDPushOBCCtoGWM_ECG 3;
BA_ "U_CD764_MY2022_Rx" SG_ 816 KeyPadCodeDgt7_D_Stat 1;
BA_ "U_CD542_MY2021_Rx" SG_ 816 KeyPadCodeDgt7_D_Stat 1;
BA_ "WakeupSignal" SG_ 816 KeyPadCodeDgt7_D_Stat 1;
BA_ "U_CD764_MY2022_Rx" SG_ 816 KeyPadCodeDgt6_D_Stat 1;
BA_ "U_CD542_MY2021_Rx" SG_ 816 KeyPadCodeDgt6_D_Stat 1;
BA_ "WakeupSignal" SG_ 816 KeyPadCodeDgt6_D_Stat 1;
BA_ "U_CD764_MY2022_Rx" SG_ 816 KeyPadCodeDgt5_D_Stat 1;
BA_ "U_CD542_MY2021_Rx" SG_ 816 KeyPadCodeDgt5_D_Stat 1;
BA_ "WakeupSignal" SG_ 816 KeyPadCodeDgt5_D_Stat 1;
BA_ "U_CD764_MY2022_Rx" SG_ 816 KeyPadCodeDgt4_D_Stat 1;
BA_ "U_CD542_MY2021_Rx" SG_ 816 KeyPadCodeDgt4_D_Stat 1;
BA_ "WakeupSignal" SG_ 816 KeyPadCodeDgt4_D_Stat 1;
BA_ "U_CD764_MY2022_Rx" SG_ 816 KeyPadCodeDgt3_D_Stat 1;
BA_ "U_CD542_MY2021_Rx" SG_ 816 KeyPadCodeDgt3_D_Stat 1;
BA_ "WakeupSignal" SG_ 816 KeyPadCodeDgt3_D_Stat 1;
BA_ "U_CD764_MY2022_Rx" SG_ 816 KeyPadCodeDgt2_D_Stat 1;
BA_ "U_CD542_MY2021_Rx" SG_ 816 KeyPadCodeDgt2_D_Stat 1;
BA_ "WakeupSignal" SG_ 816 KeyPadCodeDgt2_D_Stat 1;
BA_ "U_CD764_MY2022_Rx" SG_ 816 KeyPadCodeDgt1_D_Stat 1;
BA_ "U_CD542_MY2021_Rx" SG_ 816 KeyPadCodeDgt1_D_Stat 1;
BA_ "WakeupSignal" SG_ 816 KeyPadCodeDgt1_D_Stat 1;
BA_ "U_CD764_MY2022_Rx" SG_ 816 CntrStk2_D_RqAssoc 1;
BA_ "U_CD542_MY2021_Rx" SG_ 816 CntrStk2_D_RqAssoc 1;
BA_ "GenSigStartValue" SG_ 816 CntrStk2_D_RqAssoc 3;
BA_ "GenSigStartValueInteger" SG_ 816 CntrStk2_D_RqAssoc 3;
BA_ "WakeupSignal" SG_ 816 CntrStk2_D_RqAssoc 1;
BA_ "U_CD764_MY2022_Rx" SG_ 816 KeylessIdl_D_Rq 1;
BA_ "U_U55X_MY2022_Rx" SG_ 816 KeylessIdl_D_Rq 1;
BA_ "U_T6_MCA_MY2020_Rx" SG_ 816 KeylessIdl_D_Rq 1;
BA_ "U_U55X_MY2022_Rx" SG_ 2611175501 PARSEDPhysOBCCtoGWM_ECG 1;
BA_ "ECGUsedRxSignal" SG_ 2611175501 PARSEDPhysOBCCtoGWM_ECG 1;
BA_ "GenSigSendType" SG_ 2611175501 PARSEDPhysOBCCtoGWM_ECG 3;
BA_ "U_U55X_MY2022_Tx" SG_ 2611033304 PARSEDPhysGWM_ECGtoOBCC 1;
BA_ "ECGUsedTxSignal" SG_ 2611033304 PARSEDPhysGWM_ECGtoOBCC 1;
BA_ "GenSigSendType" SG_ 2611033304 PARSEDPhysGWM_ECGtoOBCC 3;
BA_ "U_CD542_MY2021_Tx" SG_ 2612066520 PARSEDPushFcGWM_ECGtoPACM 1;
BA_ "ECGUsedTxSignal" SG_ 2612066520 PARSEDPushFcGWM_ECGtoPACM 1;
BA_ "U_CD542_MY2021_Rx" SG_ 2612066520 PARSEDPushFcGWM_ECGtoPACM 1;
BA_ "GenSigSendType" SG_ 2612066520 PARSEDPushFcGWM_ECGtoPACM 3;
BA_ "U_U55X_MY2022_Tx" SG_ 2612081880 PARSEDPushFcGWM_ECGtoOBCC 1;
BA_ "ECGUsedTxSignal" SG_ 2612081880 PARSEDPushFcGWM_ECGtoOBCC 1;
BA_ "GenSigSendType" SG_ 2612081880 PARSEDPushFcGWM_ECGtoOBCC 3;
BA_ "U_CD764_MY2022_Tx" SG_ 966 TrnkFrontInhbt_B_Stat 1;
BA_ "GenSigSendType" SG_ 966 TrnkFrontInhbt_B_Stat 3;
BA_ "GenSigSendType" SG_ 966 ExtLghtRear_D_RqBody 3;
BA_ "U_CD764_MY2022_Tx" SG_ 966 TrnkFrontRleas_D_Src 1;
BA_ "U_U55X_MY2022_Tx" SG_ 966 TrnkFrontRleas_D_Src 1;
BA_ "GenSigSendType" SG_ 966 TrnkFrontRleas_D_Src 3;
BA_ "GenSigSendType" SG_ 966 TrnkFrontScnd_B_Falt 3;
BA_ "U_CD764_MY2022_Tx" SG_ 966 TrunkFrontOpen_No_Actl 1;
BA_ "U_U55X_MY2022_Tx" SG_ 966 TrunkFrontOpen_No_Actl 1;
BA_ "U_CD542_MY2021_Tx" SG_ 966 TrunkFrontOpen_No_Actl 1;
BA_ "GenSigSendType" SG_ 966 TrunkFrontOpen_No_Actl 3;
BA_ "WakeupSignal" SG_ 966 TrunkFrontOpen_No_Actl 1;
BA_ "U_CD764_MY2022_Tx" SG_ 966 TrunkFrontRolCd_No_Actl 1;
BA_ "U_U55X_MY2022_Tx" SG_ 966 TrunkFrontRolCd_No_Actl 1;
BA_ "U_CD542_MY2021_Tx" SG_ 966 TrunkFrontRolCd_No_Actl 1;
BA_ "GenSigSendType" SG_ 966 TrunkFrontRolCd_No_Actl 3;
BA_ "WakeupSignal" SG_ 966 TrunkFrontRolCd_No_Actl 1;
VAL_ 533 ClrExitAsstEnbl_D_RqMnu 3 "NotUsed" 0 "Inactive" 2 "Enable" 1 "Disable" ;
VAL_ 533 PaakMyKey_D_Rq 3 "NotUsed" 2 "ConfirmNewPaakMyKey" 1 "RequestNewPaakMyKey" 0 "None" ;
VAL_ 533 AutoEpbZoomView_B_Stat 1 "Active" 0 "Inactive" ;
VAL_ 533 AutoEpbButtn_B_Stat 1 "Pressed" 0 "Not_Pressed" ;
VAL_ 533 DcacPw_D_Rq 3 "High" 2 "Low" 1 "Off" 0 "Null" ;
VAL_ 533 DcacPwReset_B_Rq 1 "Reset" 0 "Null" ;
VAL_ 533 OtaTrg_D_Stat 3 "NotUsed_1" 2 "Accepted" 1 "NotAccepted" 0 "Null" ;
VAL_ 533 DcacPwLoButtn_B_Stat 1 "Pressed" 0 "Not_Pressed" ;
VAL_ 533 DcacPwOffButtn_B_Stat 1 "Pressed" 0 "Not_Pressed" ;
VAL_ 533 DcacPwHiButtn_B_Stat 1 "Pressed" 0 "Not_Pressed" ;
VAL_ 533 DcacPwResetButtn_B_Stat 1 "Pressed" 0 "Not_Pressed" ;
VAL_ 533 DcacPwButtn_B_Falt 1 "Faulted" 0 "NotFaulted" ;
VAL_ 533 OnbChrgGoTTouch_D_Rq 3 "NotUsed" 2 "On" 1 "Off" 0 "Null" ;
VAL_ 533 OnbChrgGoTPrcond_D_Rq 3 "High" 2 "Medium" 1 "Low" 0 "Off" ;
VAL_ 533 OnbChrgGoTOn_D_Rq 3 "NotUsed" 2 "On" 1 "Off" 0 "Null" ;
VAL_ 533 OnbChrgGoTMnte_D_Rq 15 "NotUsed_4" 14 "NotUsed_3" 13 "NotUsed_2" 12 "NotUsed_1" 11 "Minute_55" 10 "Minute_50" 9 "Minute_45" 8 "Minute_40" 7 "Minute_35" 6 "Minute_30" 5 "Minute_25" 4 "Minute_20" 3 "Minute_15" 2 "Minute_10" 1 "Minute_5" 0 "Minute_0" ;
VAL_ 533 OnbChrgGoTHr_T_Rq 31 "Faulty" 30 "NoDataExists" ;
VAL_ 533 OnbChrgGoTExtHtr_D_Rq 3 "NotUsed" 2 "On" 1 "Off" 0 "Null" ;
VAL_ 533 OnbChrgGoTDelete_B_Rq 1 "Request" 0 "NoRequest" ;
VAL_ 533 OnbChrgClearAll_B_Rq 1 "Request" 0 "NoRequest" ;
VAL_ 533 OnbChrgGoTUpdate_B_Rq 1 "Request" 0 "NoRequest" ;
VAL_ 533 TrlrAidMde_D_Rq 3 "Mode_3" 2 "Mode_2" 1 "Mode_1" 0 "NoRequest" ;
VAL_ 533 TCU_Init_Actvtn_St 3 "NotUsed" 2 "InitialActivateDeny" 1 "InitialActivateAccept" 0 "Invalid" ;
VAL_ 533 TCU_Final_Actvtn_St 3 "NotUsed" 2 "FinalActivateDeny" 1 "FinalActivateAccept" 0 "Invalid" ;
VAL_ 533 TrlrAlarmButtn_B_Stat 1 "On" 0 "Off" ;
VAL_ 533 DcacMdeButtn_B_Stat 1 "Pressed" 0 "Not_Pressed" ;
VAL_ 533 LghtAmbDrvMde_D_Rq 3 "NotUsed" 2 "Automatic" 1 "Manual" 0 "Null" ;
VAL_ 533 DcacGfciTestBttn_B_Stat 1 "Pressed" 0 "Not_Pressed" ;
VAL_ 533 TrlrHitch_D_RqMnu 15 "NotUsed_10" 14 "NotUsed_9" 13 "NotUsed_8" 12 "NotUsed_7" 11 "NotUsed_6" 10 "NotUsed_5" 9 "NotUsed_4" 8 "NotUsed_3" 7 "NotUsed_2" 6 "NotUsed_1" 5 "GoToTraileringDomain" 4 "Confirm" 3 "TurnOnTba" 2 "TurnOnAutohitch" 1 "CancelAutohitch" 0 "NoRequest" ;
VAL_ 533 DcacPwButtn_B_Stat 1 "Pressed" 0 "Not_Pressed" ;
VAL_ 1012 ChrgLocSaved_B_Dsply 1 "Yes" 0 "No" ;
VAL_ 1012 ChrgLocLongPostv_B_Sav 1 "Yes" 0 "No" ;
VAL_ 1012 ChrgLocLattPostv_B_Sav 1 "Yes" 0 "No" ;
VAL_ 1012 AirCondRec_B_RqVehEl 1 "Yes" 0 "No" ;
VAL_ 1012 ChrgNowCurnt_B_Dsply 1 "On" 0 "Off" ;
VAL_ 874 AirCondCluOpen_D_Falt 3 "NotUsed" 2 "Pass" 1 "Fail" 0 "Not_Diagnose_Yet" ;
VAL_ 874 AirCondClu_D_Stat 7 "NotUsed" 6 "FetLifeLimitReached" 5 "FetOpenCircuit" 4 "FetOutputShortToPower" 3 "FetOutputShortToGround" 2 "FetNotControlled" 1 "OnPowerToLoad" 0 "OffNoPowerToLoad" ;
VAL_ 874 BattTracShrtGrnd_D_Falt 3 "NotUsed" 2 "Pass" 1 "Fail" 0 "Not_Diagnose_Yet" ;
VAL_ 874 BattTracShrtBatt_D_Falt 3 "NotUsed" 2 "Pass" 1 "Fail" 0 "Not_Diagnose_Yet" ;
VAL_ 874 BattTracOpnCirct_D_Falt 3 "NotUsed" 2 "Pass" 1 "Fail" 0 "Not_Diagnose_Yet" ;
VAL_ 874 BattTracLifeLim_D_Falt 3 "NotUsed" 2 "Pass" 1 "Fail" 0 "Not_Diagnose_Yet" ;
VAL_ 874 BattChlrShrtGrnd_D_Falt 3 "NotUsed" 2 "Pass" 1 "Fail" 0 "Not_Diagnose_Yet" ;
VAL_ 874 BattChlrShrtBatt_D_Falt 3 "NotUsed" 2 "Pass" 1 "Fail" 0 "Not_Diagnose_Yet" ;
VAL_ 874 BattChlrOpnCirct_D_Falt 3 "NotUsed" 2 "Pass" 1 "Fail" 0 "Not_Diagnose_Yet" ;
VAL_ 874 BattChlrLifeLim_D_Falt 3 "NotUsed" 2 "Pass" 1 "Fail" 0 "Not_Diagnose_Yet" ;
VAL_ 874 AirCondCluLife_D_Falt 3 "NotUsed" 2 "Pass" 1 "Fail" 0 "Not_Diagnose_Yet" ;
VAL_ 874 AirCondCluGnd_D_Falt 3 "NotUsed" 2 "Pass" 1 "Fail" 0 "Not_Diagnose_Yet" ;
VAL_ 874 AirCondCluBatt_D_Falt 3 "NotUsed" 2 "Pass" 1 "Fail" 0 "Not_Diagnose_Yet" ;
VAL_ 874 BattTracLow_D_Falt 3 "NotUsed" 2 "Pass" 1 "Fail" 0 "Not_Diagnose_Yet" ;
VAL_ 912 AdasRelay_B_Stat 1 "On" 0 "Off" ;
VAL_ 912 GearPrkMtr_D_Stat 7 "NotUsed_1" 6 "FetLifeLimitReached" 5 "FetOpenCircuit" 4 "FetOutputShortToPower" 3 "FetOutputShortToGround" 2 "FetNotControlled" 1 "OnPowerToLoad" 0 "OffNoPowerToLoad" ;
VAL_ 912 GearPrkLck_D_Stat 7 "NotUsed_1" 6 "FetLifeLimitReached" 5 "FetOpenCircuit" 4 "FetOutputShortToPower" 3 "FetOutputShortToGround" 2 "FetNotControlled" 1 "OnPowerToLoad" 0 "OffNoPowerToLoad" ;
VAL_ 912 HeatCoreSovRear_D_Stat 7 "FetLowSideOpenOrShort" 6 "FetLifeLimitReached" 5 "FetOpenCircuit" 4 "FetOutputShortToPower" 3 "FetOutputShortToGround" 2 "FetNotControlled" 1 "OnPowerToLoad" 0 "OffNoPowerToLoad" ;
VAL_ 912 CabnEvapSovRear_D_Stat 7 "NotUsed_1" 6 "FetLifeLimitReached" 5 "FetOpenCircuit" 4 "FetOutputShortToPower" 3 "FetOutputShortToGround" 2 "FetNotControlled" 1 "OnPowerToLoad" 0 "OffNoPowerToLoad" ;
VAL_ 912 CabnEvapSovFront_D_Stat 7 "NotUsed_1" 6 "FetLifeLimitReached" 5 "FetOpenCircuit" 4 "FetOutputShortToPower" 3 "FetOutputShortToGround" 2 "FetNotControlled" 1 "OnPowerToLoad" 0 "OffNoPowerToLoad" ;
VAL_ 912 BattTracSov_D_Stat 7 "NotUsed_1" 6 "FetLifeLimitReached" 5 "FetOpenCircuit" 4 "FetOutputShortToPower" 3 "FetOutputShortToGround" 2 "FetNotControlled" 1 "OnPowerToLoad" 0 "OffNoPowerToLoad" ;
VAL_ 912 BattChlrSov_D_Stat 7 "NotUsed_1" 6 "FetLifeLimitReached" 5 "FetOpenCircuit" 4 "FetOutputShortToPower" 3 "FetOutputShortToGround" 2 "FetNotControlled" 1 "OnPowerToLoad" 0 "OffNoPowerToLoad" ;
VAL_ 912 BattTracClntVlv_D_Stat 7 "FetLowSideOpenOrShort" 6 "FetLifeLimitReached" 5 "FetOpenCircuit" 4 "FetOutputShortToPower" 3 "FetOutputShortToGround" 2 "FetNotControlled" 1 "OnPowerToLoad" 0 "OffNoPowerToLoad" ;
VAL_ 1176 BattTracCell45_U_Actl 4095 "Fault" 4094 "NoDataExists" ;
VAL_ 1176 BattTracCell44_U_Actl 4095 "Fault" 4094 "NoDataExists" ;
VAL_ 1176 BattTracCell43_U_Actl 4095 "Fault" 4094 "NoDataExists" ;
VAL_ 1176 BattTracCell42_U_Actl 4095 "Fault" 4094 "NoDataExists" ;
VAL_ 1176 BattTracCell41_U_Actl 4095 "Fault" 4094 "NoDataExists" ;
VAL_ 1175 BattTracCell40_U_Actl 4095 "Fault" 4094 "NoDataExists" ;
VAL_ 1175 BattTracCell39_U_Actl 4095 "Fault" 4094 "NoDataExists" ;
VAL_ 1175 BattTracCell38_U_Actl 4095 "Fault" 4094 "NoDataExists" ;
VAL_ 1175 BattTracCell37_U_Actl 4095 "Fault" 4094 "NoDataExists" ;
VAL_ 1175 BattTracCell36_U_Actl 4095 "Fault" 4094 "NoDataExists" ;
VAL_ 931 VehOnSrc_D_Stat 15 "NotUsed_11" 14 "NotUsed_10" 13 "NotUsed_9" 12 "NotUsed_8" 11 "NotUsed_7" 10 "NotUsed_6" 9 "EsclRssd" 8 "AutonomousVehicle" 7 "SecureIdle" 6 "FleetVehicleInhibit" 5 "StolenVehicleInhibit" 4 "OverTheAir" 3 "RemoteParkAssist" 2 "RemoteStart" 1 "Manual" 0 "Off" ;
VAL_ 931 EngStrtActv_B_Stat 1 "Active" 0 "Inactive" ;
VAL_ 931 EngStrt_B_Rq 1 "Request" 0 "NoRequest" ;
VAL_ 931 DrvInCtl_B_Stat 1 "Yes" 0 "No" ;
VAL_ 931 PtWakeReas_D_Stat 15 "NotUsed_9" 14 "NotUsed_8" 13 "NotUsed_7" 12 "NotUsed_6" 11 "NotUsed_5" 10 "NotUsed_4" 9 "NotUsed_3" 8 "NotUsed_2" 7 "NotUsed_1" 6 "ElapsedTime" 5 "ThirdPartyWakeup" 4 "DoorAjar" 3 "EarlyWake" 2 "NonMotiveStart" 1 "MotiveStart" 0 "Null" ;
VAL_ 931 CrnkInhbt_B_Stat 1 "Inhibit" 0 "NoInhibit" ;
VAL_ 931 IgnPreOffActv_B_Stat 1 "Active" 0 "Inactive" ;
VAL_ 1247 TrlrBrkCtl3_B_Falt 1 "True" 0 "False" ;
VAL_ 1247 StopLamp_B_RqTrlrAft 1 "True" 0 "False" ;
VAL_ 1167 PrplAxlScnd_Tq_ActlMntr 65535 "Faulty" 65534 "NoDataExists" ;
VAL_ 1167 Inv4TeAlrm_B_ActlMntr 1 "Active" 0 "Inactive" ;
VAL_ 1167 Inv4Ain_U_ActlMntr 1023 "Faulty" 1022 "NoDataExists" ;
VAL_ 1167 Inv4Ain_I_ActlMntr 32767 "Faulty" 32766 "NoDataExists" ;
VAL_ 1167 Inv4_Te_ActlMntr 255 "Faulty" 254 "NoDataExists" ;
VAL_ 1199 Mtr4TeAlrm_B_ActlMntr 1 "Active" 0 "Inactive" ;
VAL_ 1199 Mtr4Aout_W_ActlMntr 1023 "Faulty" ;
VAL_ 1199 Mtr4_Te_ActlMntr 255 "Faulty" 254 "NoDataExists" ;
VAL_ 1199 Mtr4_D_StatMntr 7 "Faulty" 6 "NotDataExists" 5 "NotUsed" 4 "ReadinessState" 3 "DeactivationState" 2 "PowerGeneration" 1 "PowerConsumption" 0 "Null" ;
VAL_ 563 DrvBhavAudioAlrt_D_Rq 58 "NotUsed_51" 57 "NotUsed_50" 56 "NotUsed_49" 55 "NotUsed_48" 54 "NotUsed_47" 53 "NotUsed_46" 52 "NotUsed_45" 25 "NotUsed_18" 24 "NotUsed_17" 23 "NotUsed_16" 22 "NotUsed_15" 21 "NotUsed_14" 20 "NotUsed_13" 19 "NotUsed_12" 18 "NotUsed_11" 17 "NotUsed_10" 16 "NotUsed_9" 15 "NotUsed_8" 14 "NotUsed_7" 13 "NotUsed_6" 12 "NotUsed_5" 11 "NotUsed_4" 10 "NotUsed_3" 9 "NotUsed_2" 8 "NotUsed_1" 7 "ExcessiveIdleAndUnbuckled" 6 "ExcessiveSpeedAndUnbuckled" 5 "SeatbeltUnbuckled" 4 "HardBrakingBegin" 3 "HardAccelerationBegin" 2 "ExcessiveSpeedBegin" 1 "ExcessiveIdleBegin" 0 "NoMessage" 63 "NotUsed_56" 62 "NotUsed_55" 61 "NotUsed_54" 60 "NotUsed_53" 59 "NotUsed_52" ;
VAL_ 563 NtfyDrvTrgtDist_L2_Rq 8191 "Faulty" 8190 "NoDataExists" ;
VAL_ 563 BattChrgStrtStop_D_Rq 3 "ReturnToSettings" 2 "StopCharge" 1 "StartCharge" 0 "NoNewRequest" ;
VAL_ 563 DrvBhavWarn_B_Rq 1 "On" 0 "Off" ;
VAL_ 563 OfbChrgSetSync_D_Rq 3 "Fail" 2 "Success" 1 "InProgress" 0 "NoSyncInProgress" ;
VAL_ 563 KeyOffPwMde_D_Stat 7 "NotUsed_6" 6 "NotUsed_5" 5 "NotUsed_4" 4 "NotUsed_3" 0 "Inactive" 1 "On" 2 "NotUsed_1" 3 "NotUsed_2" ;
VAL_ 563 ModemReset_D_Stat 15 "NotUsed_10" 14 "NotUsed_9" 13 "NotUsed_8" 12 "NotUsed_7" 11 "NotUsed_6" 10 "NotUsed_5" 9 "NotUsed_4" 8 "NotUsed_3" 7 "NotUsed_2" 6 "NotUsed_1" 5 "WifiHotSpotResetComplete" 4 "CcsResetComplete" 3 "OnlineTrafficResetComplete" 2 "PaakResetComplete" 1 "ResetNotComplete" 0 "Null" ;
VAL_ 563 FactoryReset_St 3 "NotUsed_2" 2 "NotUsed_1" 1 "FactoryDefaultsRestored" 0 "Null" ;
VAL_ 1174 BattTracCell35_U_Actl 4095 "Fault" 4094 "NoDataExists" ;
VAL_ 1174 BattTracCell34_U_Actl 4095 "Fault" 4094 "NoDataExists" ;
VAL_ 1174 BattTracCell33_U_Actl 4095 "Fault" 4094 "NoDataExists" ;
VAL_ 1174 BattTracCell32_U_Actl 4095 "Fault" 4094 "NoDataExists" ;
VAL_ 1174 BattTracCell31_U_Actl 4095 "Fault" 4094 "NoDataExists" ;
VAL_ 1173 BattTracCell30_U_Actl 4095 "Fault" 4094 "NoDataExists" ;
VAL_ 1173 BattTracCell29_U_Actl 4095 "Fault" 4094 "NoDataExists" ;
VAL_ 1173 BattTracCell28_U_Actl 4095 "Fault" 4094 "NoDataExists" ;
VAL_ 1173 BattTracCell27_U_Actl 4095 "Fault" 4094 "NoDataExists" ;
VAL_ 1173 BattTracCell26_U_Actl 4095 "Fault" 4094 "NoDataExists" ;
VAL_ 1172 BattTracCell25_U_Actl 4095 "Fault" 4094 "NoDataExists" ;
VAL_ 1172 BattTracCell24_U_Actl 4095 "Fault" 4094 "NoDataExists" ;
VAL_ 1172 BattTracCell23_U_Actl 4095 "Fault" 4094 "NoDataExists" ;
VAL_ 1172 BattTracCell22_U_Actl 4095 "Fault" 4094 "NoDataExists" ;
VAL_ 1172 BattTracCell21_U_Actl 4095 "Fault" 4094 "NoDataExists" ;
VAL_ 1171 BattTracCell20_U_Actl 4095 "Fault" 4094 "NoDataExists" ;
VAL_ 1171 BattTracCell19_U_Actl 4095 "Fault" 4094 "NoDataExists" ;
VAL_ 1171 BattTracCell18_U_Actl 4095 "Fault" 4094 "NoDataExists" ;
VAL_ 1171 BattTracCell17_U_Actl 4095 "Fault" 4094 "NoDataExists" ;
VAL_ 1171 BattTracCell16_U_Actl 4095 "Fault" 4094 "NoDataExists" ;
VAL_ 1170 BattTracCell15_U_Actl 4095 "Fault" 4094 "NoDataExists" ;
VAL_ 1170 BattTracCell14_U_Actl 4095 "Fault" 4094 "NoDataExists" ;
VAL_ 1170 BattTracCell13_U_Actl 4095 "Fault" 4094 "NoDataExists" ;
VAL_ 1170 BattTracCell12_U_Actl 4095 "Fault" 4094 "NoDataExists" ;
VAL_ 1170 BattTracCell11_U_Actl 4095 "Fault" 4094 "NoDataExists" ;
VAL_ 1191 BattTracTe14_Te_Actl 255 "Faulty" 254 "NoDataExists" ;
VAL_ 1191 BattTracTe19_Te_Actl 255 "Faulty" 254 "NoDataExists" ;
VAL_ 1191 BattTracTe18_Te_Actl 255 "Faulty" 254 "NoDataExists" ;
VAL_ 1191 BattTracTe17_Te_Actl 255 "Faulty" 254 "NoDataExists" ;
VAL_ 1191 BattTracTe16_Te_Actl 255 "Faulty" 254 "NoDataExists" ;
VAL_ 1191 BattTracTe15_Te_Actl 255 "Faulty" 254 "NoDataExists" ;
VAL_ 1189 BattTracUMxArry_No_Actl 31 "Faulty" ;
VAL_ 1189 BattTracCellUMx_No_Actl 255 "Faulty" 254 "NoDataExists" ;
VAL_ 1189 BattChrgUMx_B_Falt 1 "Yes" 0 "No" ;
VAL_ 1189 BattTracCellUMn_No_Actl 255 "Faulty" 254 "NoDataExists" ;
VAL_ 1189 BattTracCellCnt_No_Actl 255 "Faulty" 254 "NoDataExists" ;
VAL_ 1189 BattChrgIsltn_B_Falt 1 "Yes" 0 "No" ;
VAL_ 1189 BattTracCellDiff_B_Falt 1 "Yes" 0 "No" ;
VAL_ 1189 BattChrgSocMx_B_Falt 1 "Yes" 0 "No" ;
VAL_ 1189 BattChrgSocMn_B_Falt 1 "Yes" 0 "No" ;
VAL_ 1189 BattChrgSocErrtc_B_Falt 1 "Yes" 0 "No" ;
VAL_ 1189 BattTracUMx_B_Falt 1 "Yes" 0 "No" ;
VAL_ 1189 BattTracUMn_B_Falt 1 "Yes" 0 "No" ;
VAL_ 1189 BattTracTeMx_No_Actl 255 "Faulty" 254 "NoDataExists" ;
VAL_ 1189 BattTracTeMx_B_Falt 1 "Yes" 0 "No" ;
VAL_ 1189 BattTracTeMn_No_Actl 255 "Faulty" 254 "NoDataExists" ;
VAL_ 1189 BattTracTeDelta_B_Falt 1 "Yes" 0 "No" ;
VAL_ 1189 BattTracTeCnt_No_Actl 255 "Faulty" 254 "NoDataExists" ;
VAL_ 1189 BattTracSoftware_B_Falt 1 "Yes" 0 "No" ;
VAL_ 1188 BattTracTe13_Te_Actl 255 "Faulty" 254 "NoDataExists" ;
VAL_ 1188 BattTracTe12_Te_Actl 255 "Faulty" 254 "NoDataExists" ;
VAL_ 1188 BattTracTe11_Te_Actl 255 "Faulty" 254 "NoDataExists" ;
VAL_ 1188 BattTracTe10_Te_Actl 255 "Faulty" 254 "NoDataExists" ;
VAL_ 1188 BattTracTe09_Te_Actl 255 "Faulty" 254 "NoDataExists" ;
VAL_ 1188 BattTracTe08_Te_Actl 255 "Faulty" 254 "NoDataExists" ;
VAL_ 1188 BattTracTe07_Te_Actl 255 "Faulty" 254 "NoDataExists" ;
VAL_ 1187 BattTracTe06_Te_Actl 255 "Faulty" 254 "NoDataExists" ;
VAL_ 1187 BattTracTe05_Te_Actl 255 "Faulty" 254 "NoDataExists" ;
VAL_ 1187 BattTracTe04_Te_Actl 255 "Faulty" 254 "NoDataExists" ;
VAL_ 1187 BattTracTe03_Te_Actl 255 "Faulty" 254 "NoDataExists" ;
VAL_ 1187 BattTracTe02_Te_Actl 255 "Faulty" 254 "NoDataExists" ;
VAL_ 1187 BattTracTe01_Te_Actl 255 "Faulty" 254 "NoDataExists" ;
VAL_ 1187 BattTracCell96_U_Actl 4095 "Fault" 4094 "NoDataExists" ;
VAL_ 1169 BattTracCell10_U_Actl 4095 "Fault" 4094 "NoDataExists" ;
VAL_ 1169 BattTracCell09_U_Actl 4095 "Fault" 4094 "NoDataExists" ;
VAL_ 1169 BattTracCell08_U_Actl 4095 "Fault" 4094 "NoDataExists" ;
VAL_ 1169 BattTracCell07_U_Actl 4095 "Fault" 4094 "NoDataExists" ;
VAL_ 1169 BattTracCell06_U_Actl 4095 "Fault" 4094 "NoDataExists" ;
VAL_ 1186 BattTracCell95_U_Actl 4095 "Fault" 4094 "NoDataExists" ;
VAL_ 1186 BattTracCell94_U_Actl 4095 "Fault" 4094 "NoDataExists" ;
VAL_ 1186 BattTracCell93_U_Actl 4095 "Fault" 4094 "NoDataExists" ;
VAL_ 1186 BattTracCell92_U_Actl 4095 "Fault" 4094 "NoDataExists" ;
VAL_ 1186 BattTracCell91_U_Actl 4095 "Fault" 4094 "NoDataExists" ;
VAL_ 1185 BattTracCell90_U_Actl 4095 "Fault" 4094 "NoDataExists" ;
VAL_ 1185 BattTracCell89_U_Actl 4095 "Fault" 4094 "NoDataExists" ;
VAL_ 1185 BattTracCell88_U_Actl 4095 "Fault" 4094 "NoDataExists" ;
VAL_ 1185 BattTracCell87_U_Actl 4095 "Fault" 4094 "NoDataExists" ;
VAL_ 1185 BattTracCell86_U_Actl 4095 "Fault" 4094 "NoDataExists" ;
VAL_ 1184 BattTracCell85_U_Actl 4095 "Fault" 4094 "NoDataExists" ;
VAL_ 1184 BattTracCell84_U_Actl 4095 "Fault" 4094 "NoDataExists" ;
VAL_ 1184 BattTracCell83_U_Actl 4095 "Fault" 4094 "NoDataExists" ;
VAL_ 1184 BattTracCell82_U_Actl 4095 "Fault" 4094 "NoDataExists" ;
VAL_ 1184 BattTracCell81_U_Actl 4095 "Fault" 4094 "NoDataExists" ;
VAL_ 1183 BattTracCell80_U_Actl 4095 "Fault" 4094 "NoDataExists" ;
VAL_ 1183 BattTracCell79_U_Actl 4095 "Fault" 4094 "NoDataExists" ;
VAL_ 1183 BattTracCell78_U_Actl 4095 "Fault" 4094 "NoDataExists" ;
VAL_ 1183 BattTracCell77_U_Actl 4095 "Fault" 4094 "NoDataExists" ;
VAL_ 1183 BattTracCell76_U_Actl 4095 "Fault" 4094 "NoDataExists" ;
VAL_ 1182 BattTracCell75_U_Actl 4095 "Fault" 4094 "NoDataExists" ;
VAL_ 1182 BattTracCell74_U_Actl 4095 "Fault" 4094 "NoDataExists" ;
VAL_ 1182 BattTracCell73_U_Actl 4095 "Fault" 4094 "NoDataExists" ;
VAL_ 1182 BattTracCell72_U_Actl 4095 "Fault" 4094 "NoDataExists" ;
VAL_ 1182 BattTracCell71_U_Actl 4095 "Fault" 4094 "NoDataExists" ;
VAL_ 1181 BattTracCell70_U_Actl 4095 "Fault" 4094 "NoDataExists" ;
VAL_ 1181 BattTracCell69_U_Actl 4095 "Fault" 4094 "NoDataExists" ;
VAL_ 1181 BattTracCell68_U_Actl 4095 "Fault" 4094 "NoDataExists" ;
VAL_ 1181 BattTracCell67_U_Actl 4095 "Fault" 4094 "NoDataExists" ;
VAL_ 1181 BattTracCell66_U_Actl 4095 "Fault" 4094 "NoDataExists" ;
VAL_ 1180 BattTracCell65_U_Actl 4095 "Fault" 4094 "NoDataExists" ;
VAL_ 1180 BattTracCell64_U_Actl 4095 "Fault" 4094 "NoDataExists" ;
VAL_ 1180 BattTracCell63_U_Actl 4095 "Fault" 4094 "NoDataExists" ;
VAL_ 1180 BattTracCell62_U_Actl 4095 "Fault" 4094 "NoDataExists" ;
VAL_ 1180 BattTracCell61_U_Actl 4095 "Fault" 4094 "NoDataExists" ;
VAL_ 1179 BattTracCell60_U_Actl 4095 "Fault" 4094 "NoDataExists" ;
VAL_ 1179 BattTracCell59_U_Actl 4095 "Fault" 4094 "NoDataExists" ;
VAL_ 1179 BattTracCell58_U_Actl 4095 "Fault" 4094 "NoDataExists" ;
VAL_ 1179 BattTracCell57_U_Actl 4095 "Fault" 4094 "NoDataExists" ;
VAL_ 1179 BattTracCell56_U_Actl 4095 "Fault" 4094 "NoDataExists" ;
VAL_ 1178 BattTracCell55_U_Actl 4095 "Fault" 4094 "NoDataExists" ;
VAL_ 1178 BattTracCell54_U_Actl 4095 "Fault" 4094 "NoDataExists" ;
VAL_ 1178 BattTracCell53_U_Actl 4095 "Fault" 4094 "NoDataExists" ;
VAL_ 1178 BattTracCell52_U_Actl 4095 "Fault" 4094 "NoDataExists" ;
VAL_ 1178 BattTracCell51_U_Actl 4095 "Fault" 4094 "NoDataExists" ;
VAL_ 1177 BattTracCell50_U_Actl 4095 "Fault" 4094 "NoDataExists" ;
VAL_ 1177 BattTracCell49_U_Actl 4095 "Fault" 4094 "NoDataExists" ;
VAL_ 1177 BattTracCell48_U_Actl 4095 "Fault" 4094 "NoDataExists" ;
VAL_ 1177 BattTracCell47_U_Actl 4095 "Fault" 4094 "NoDataExists" ;
VAL_ 1177 BattTracCell46_U_Actl 4095 "Fault" 4094 "NoDataExists" ;
VAL_ 1168 BattTracCell05_U_Actl 4095 "Fault" 4094 "NoDataExists" ;
VAL_ 1168 BattTracCell04_U_Actl 4095 "Fault" 4094 "NoDataExists" ;
VAL_ 1168 BattTracCell03_U_Actl 4095 "Fault" 4094 "NoDataExists" ;
VAL_ 1168 BattTracCell02_U_Actl 4095 "Fault" 4094 "NoDataExists" ;
VAL_ 1168 BattTracCell01_U_Actl 4095 "Fault" 4094 "NoDataExists" ;
VAL_ 621 IgnPsswrdActv_B_Stat 1 "Active" 0 "Inactive" ;
VAL_ 621 FobTrgtZone_D_Rq 15 "NotUsed_9" 14 "NotUsed_8" 13 "NotUsed_7" 12 "NotUsed_6" 11 "NotUsed_5" 10 "NotUsed_4" 9 "NotUsed_3" 8 "NotUsed_2" 7 "NotUsed_1" 6 "Approach" 5 "RearInterior" 4 "RearExterior" 3 "Passenger" 2 "Driver" 1 "Interior" 0 "Null" ;
VAL_ 621 FobTrgtType_D_Rq 7 "NotUsed_4" 6 "NotUsed_3" 5 "NotUsed_2" 4 "NotUsed_1" 3 "Polling" 2 "Registry" 1 "Crypto" 0 "Null" ;
VAL_ 621 RmtCtlSelSlot_D_Rq 7 "NotUsed_3" 6 "NotUsed_2" 5 "NotUsed_1" 4 "Right" 3 "Left" 2 "Rear" 1 "Front" 0 "None" ;
VAL_ 621 RmtCtlSelPrkMde_D_Rq 3 "NotUsed" 2 "FreeDrive" 1 "ParkIn" 0 "None" ;
VAL_ 621 RmtCtlSelMoveDir_D_Rq 3 "NotUsed" 2 "Backward" 1 "Forward" 0 "None" ;
VAL_ 621 RmtCtlRjctAutoCfg_B_Rq 1 "Yes" 0 "No" ;
VAL_ 1149 BattTracPerf_Pc_Dsply 255 "Faulty" 254 "NoDataExists" ;
VAL_ 1149 BattTracPerf_Pc_Actl 255 "Faulty" 254 "NoDataExists" ;
VAL_ 626 PaakCtlIndx8_D_Stat 15 "NotUsed_9" 14 "NotUsed_8" 13 "NotUsed_7" 12 "NotUsed_6" 11 "NotUsed_5" 10 "NotUsed_4" 9 "NotUsed_3" 8 "NotUsed_2" 7 "NotUsed_1" 6 "Approach" 5 "RearInterior" 4 "RearExterior" 3 "Passenger" 2 "Driver" 1 "Interior" 0 "Null" ;
VAL_ 626 PaakCtlIndx7_D_Stat 15 "NotUsed_9" 14 "NotUsed_8" 13 "NotUsed_7" 12 "NotUsed_6" 11 "NotUsed_5" 10 "NotUsed_4" 9 "NotUsed_3" 8 "NotUsed_2" 7 "NotUsed_1" 6 "Approach" 5 "RearInterior" 4 "RearExterior" 3 "Passenger" 2 "Driver" 1 "Interior" 0 "Null" ;
VAL_ 626 PaakCtlIndx6_D_Stat 15 "NotUsed_9" 14 "NotUsed_8" 13 "NotUsed_7" 12 "NotUsed_6" 11 "NotUsed_5" 10 "NotUsed_4" 9 "NotUsed_3" 8 "NotUsed_2" 7 "NotUsed_1" 6 "Approach" 5 "RearInterior" 4 "RearExterior" 3 "Passenger" 2 "Driver" 1 "Interior" 0 "Null" ;
VAL_ 626 PaakCtlIndx5_D_Stat 15 "NotUsed_9" 14 "NotUsed_8" 13 "NotUsed_7" 12 "NotUsed_6" 11 "NotUsed_5" 10 "NotUsed_4" 9 "NotUsed_3" 8 "NotUsed_2" 7 "NotUsed_1" 6 "Approach" 5 "RearInterior" 4 "RearExterior" 3 "Passenger" 2 "Driver" 1 "Interior" 0 "Null" ;
VAL_ 626 PaakCtlIndx4_D_Stat 15 "NotUsed_9" 14 "NotUsed_8" 13 "NotUsed_7" 12 "NotUsed_6" 11 "NotUsed_5" 10 "NotUsed_4" 9 "NotUsed_3" 8 "NotUsed_2" 7 "NotUsed_1" 6 "Approach" 5 "RearInterior" 4 "RearExterior" 3 "Passenger" 2 "Driver" 1 "Interior" 0 "Null" ;
VAL_ 626 PaakCtlIndx3_D_Stat 15 "NotUsed_9" 14 "NotUsed_8" 13 "NotUsed_7" 12 "NotUsed_6" 11 "NotUsed_5" 10 "NotUsed_4" 9 "NotUsed_3" 8 "NotUsed_2" 7 "NotUsed_1" 6 "Approach" 5 "RearInterior" 4 "RearExterior" 3 "Passenger" 2 "Driver" 1 "Interior" 0 "Null" ;
VAL_ 626 PaakCtlIndx2_D_Stat 15 "NotUsed_9" 14 "NotUsed_8" 13 "NotUsed_7" 12 "NotUsed_6" 11 "NotUsed_5" 10 "NotUsed_4" 9 "NotUsed_3" 8 "NotUsed_2" 7 "NotUsed_1" 6 "Approach" 5 "RearInterior" 4 "RearExterior" 3 "Passenger" 2 "Driver" 1 "Interior" 0 "Null" ;
VAL_ 626 PaakCtlIndx1_D_Stat 15 "NotUsed_9" 14 "NotUsed_8" 13 "NotUsed_7" 12 "NotUsed_6" 11 "NotUsed_5" 10 "NotUsed_4" 9 "NotUsed_3" 8 "NotUsed_2" 7 "NotUsed_1" 6 "Approach" 5 "RearInterior" 4 "RearExterior" 3 "Passenger" 2 "Driver" 1 "Interior" 0 "Null" ;
VAL_ 770 BattTracVrtOck_B_Stat 1 "Yes" 0 "No" ;
VAL_ 770 ScEnbl_B_Stat 1 "On" 0 "Off" ;
VAL_ 1161 DrSwtchInnrRr_No_Rq_UB 1 "Fresh_data" 0 "Unchanged_data" ;
VAL_ 1161 DrSwtchInnrRl_No_Rq_UB 1 "Fresh_data" 0 "Unchanged_data" ;
VAL_ 1161 DrLatchRolCdRr_No_Locl_UB 1 "Fresh_data" 0 "Unchanged_data" ;
VAL_ 1161 DrLatchRolCdRl_No_Locl_UB 1 "Fresh_data" 0 "Unchanged_data" ;
VAL_ 1159 WakeAlarm2_B_Typ_UB 1 "Fresh_data" 0 "Unchanged_data" ;
VAL_ 1159 WakeAlarm2_T_Rq_UB 1 "Fresh_data" 0 "Unchanged_data" ;
VAL_ 1159 WakeAlarm2_B_Typ 1 "CanAndEcuDriveCircuit" 0 "CanOnly" ;
VAL_ 1159 DrLatchRolCdFr_No_Locl_UB 1 "Fresh_data" 0 "Unchanged_data" ;
VAL_ 1159 DrLatchRolCdFl_No_Locl_UB 1 "Fresh_data" 0 "Unchanged_data" ;
VAL_ 1159 DrSwtchInnrFr_No_Rq_UB 1 "Fresh_data" 0 "Unchanged_data" ;
VAL_ 1159 DrSwtchInnrFl_No_Rq_UB 1 "Fresh_data" 0 "Unchanged_data" ;
VAL_ 72 immoTarget2Status 7 "Unused4" 6 "Unused3" 5 "Unused2" 4 "ENABLED_LIMITEDMOTIVE_STAR" 3 "DISABLED_RESET   " 2 "ENABLED_NONMOTIVE_START" 1 "ENABLED_MOTIVE_START" 0 "DISABLED" ;
VAL_ 72 immoTarget2Cmd 7 "Unused4" 6 "Unused3" 5 "Unused2" 4 "Unused1" 3 "TARGET1_IDBLOCK2" 2 "TARGET1_IDBLOCK1" 1 "CHALLENGE" 0 "IDLE" ;
VAL_ 1130 PaakCtlType_D_Stat 3 "NotUsed" 2 "Valid" 1 "Invalid" 0 "Null" ;
VAL_ 1130 PaakCtlData_D_Stat 7 "NotUsed_3" 6 "NotUsed_2" 5 "NotUsed_1" 4 "Response" 3 "EchoTargetIdBlock1" 2 "RequestTargetIdBlock2" 1 "RequestTargetIdBlock1" 0 "Idle" ;
VAL_ 1130 IgnPsswrdLckout_B_Stat 1 "Active" 0 "Inactive" ;
VAL_ 1130 IgnPsswrdSetup_B_Rq 1 "Active" 0 "Inactive" ;
VAL_ 1130 PaakLoclzd_D_Stat 15 "NotUsed_12" 14 "NotUsed_11" 13 "NotUsed_10" 12 "NotUsed_9" 11 "NotUsed_8" 10 "NotUsed_7" 9 "NotUsed_6" 8 "NotUsed_5" 7 "NotUsed_4" 6 "NotUsed_3" 5 "NotUsed_2" 4 "NotUsed_1" 3 "FullLoc" 2 "PausedLoc" 1 "MaintainLink" 0 "BackgroundScan" ;
VAL_ 1129 PaaKMyKeyChng_D_Stat 3 "NotUsed" 2 "ClearAll" 1 "MyKey" 0 "Null" ;
VAL_ 1129 PaakAddErase_D_Stat 3 "EraseAll" 2 "Erase" 1 "Add" 0 "Null" ;
VAL_ 1131 KeyPadCodeProg_D_Rq 7 "NotUsed_3" 6 "NotUsed_2" 5 "NotUsed_1" 4 "DeleteAll" 3 "Delete" 2 "Add" 1 "ProgrammingMode" 0 "Null" ;
VAL_ 1131 PaakCnnct_D_Stat 3 "NotUsed" 2 "Connected" 1 "NotConnected" 0 "Null" ;
VAL_ 1131 PaakCtlActv_D_Rq 31 "NotUsed_13" 30 "NotUsed_12" 29 "NotUsed_11" 28 "NotUsed_10" 27 "NotUsed_9" 26 "NotUsed_8" 25 "NotUsed_7" 24 "NotUsed_6" 23 "NotUsed_5" 22 "NotUsed_4" 21 "NotUsed_3" 20 "TrunkFrontRelease" 19 "RemoteStop" 18 "RemoteStart" 17 "PowerDecklid" 16 "RightPowerSlidingDoor" 15 "LeftPowerSlidingDoor" 14 "PowerLiftgate" 13 "GlobalClose" 12 "GlobalOpen" 11 "PanicOff" 10 "PanicOn" 9 "LiftgateGlassRelease" 8 "LiftgateRelease" 7 "DecklidRelease" 6 "DoubleLock" 5 "LockAll" 4 "UnlockAllDoorsPlusCargo" 3 "UnlockCargoDoor" 2 "UnlockAllDoors" 1 "UnlockDriverDoor" 0 "Null" ;
VAL_ 1128 KeyPadCodeProg_D_Stat 7 "NotUsed_2" 6 "Duplicate" 5 "ProgrammingFailure" 4 "DeleteAll" 3 "Delete" 2 "Add" 1 "LearningMode" 0 "NormalMode" ;
VAL_ 1128 PaakTrgtType_D_Rq 7 "NotUsed_4" 6 "NotUsed_3" 5 "NotUsed_2" 4 "NotUsed_1" 3 "Polling" 2 "Registry" 1 "Crypto" 0 "Null" ;
VAL_ 1128 PaakTrgtZone_D_Rq 15 "NotUsed_9" 14 "NotUsed_8" 13 "NotUsed_7" 12 "NotUsed_6" 11 "NotUsed_5" 10 "NotUsed_4" 9 "NotUsed_3" 8 "NotUsed_2" 7 "NotUsed_1" 6 "Approach" 5 "RearInterior" 4 "RearExterior" 3 "Passenger" 2 "Driver" 1 "Interior" 0 "Null" ;
VAL_ 1128 PaakTrgtData_D_Rq 5 "NotUsed_2" 4 "Not_Used1" 3 "Target1_IdBlock2" 2 "Target1_IdBlock1" 1 "Challenge" 0 "Idle" 7 "NotUsed_4" 6 "NotUsed_3" ;
VAL_ 1128 PaakTrgtPreAuthrz_B_Rq 1 "Enable" 0 "Disable" ;
VAL_ 123 BattTrac_U2_Actl 4095 "Faulty" 4094 "NoDataExists" ;
VAL_ 123 BattTrac_I2_Actl 262143 "Faulty" 262142 "NoDataExists" ;
VAL_ 816 KeyPadCodeDgt7_D_Stat 15 "NotUsed_4" 14 "NotUsed_3" 13 "NotUsed_2" 12 "NotUsed_1" 11 "Button7_8and9_0" 10 "Button0" 9 "Button9_0or9" 8 "Button8" 7 "Button7_8or7" 6 "Button6" 5 "Button5_6or5" 4 "Button4" 3 "Button3_4or3" 2 "Button2" 1 "Button1_2or1" 0 "EndofString" ;
VAL_ 816 KeyPadCodeDgt6_D_Stat 15 "NotUsed_4" 14 "NotUsed_3" 13 "NotUsed_2" 12 "NotUsed_1" 11 "Button7_8and9_0" 10 "Button0" 9 "Button9_0or9" 8 "Button8" 7 "Button7_8or7" 6 "Button6" 5 "Button5_6or5" 4 "Button4" 3 "Button3_4or3" 2 "Button2" 1 "Button1_2or1" 0 "EndofString" ;
VAL_ 816 KeyPadCodeDgt5_D_Stat 15 "NotUsed_4" 14 "NotUsed_3" 13 "NotUsed_2" 12 "NotUsed_1" 11 "Button7_8and9_0" 10 "Button0" 9 "Button9_0or9" 8 "Button8" 7 "Button7_8or7" 6 "Button6" 5 "Button5_6or5" 4 "Button4" 3 "Button3_4or3" 2 "Button2" 1 "Button1_2or1" 0 "EndofString" ;
VAL_ 816 KeyPadCodeDgt4_D_Stat 15 "NotUsed_4" 14 "NotUsed_3" 13 "NotUsed_2" 12 "NotUsed_1" 11 "Button7_8and9_0" 10 "Button0" 9 "Button9_0or9" 8 "Button8" 7 "Button7_8or7" 6 "Button6" 5 "Button5_6or5" 4 "Button4" 3 "Button3_4or3" 2 "Button2" 1 "Button1_2or1" 0 "EndofString" ;
VAL_ 816 KeyPadCodeDgt3_D_Stat 15 "NotUsed_4" 14 "NotUsed_3" 13 "NotUsed_2" 12 "NotUsed_1" 11 "Button7_8and9_0" 10 "Button0" 9 "Button9_0or9" 8 "Button8" 7 "Button7_8or7" 6 "Button6" 5 "Button5_6or5" 4 "Button4" 3 "Button3_4or3" 2 "Button2" 1 "Button1_2or1" 0 "EndofString" ;
VAL_ 816 KeyPadCodeDgt2_D_Stat 15 "NotUsed_4" 14 "NotUsed_3" 13 "NotUsed_2" 12 "NotUsed_1" 11 "Button7_8and9_0" 10 "Button0" 9 "Button9_0or9" 8 "Button8" 7 "Button7_8or7" 6 "Button6" 5 "Button5_6or5" 4 "Button4" 3 "Button3_4or3" 2 "Button2" 1 "Button1_2or1" 0 "EndofString" ;
VAL_ 816 KeyPadCodeDgt1_D_Stat 15 "NotUsed_4" 14 "NotUsed_3" 13 "NotUsed_2" 12 "NotUsed_1" 11 "Button7_8and9_0" 10 "Button0" 9 "Button9_0or9" 8 "Button8" 7 "Button7_8or7" 6 "Button6" 5 "Button5_6or5" 4 "Button4" 3 "Button3_4or3" 2 "Button2" 1 "Button1_2or1" 0 "EndofString" ;
VAL_ 816 CntrStk2_D_RqAssoc 7 "Unused_2" 6 "Cancel" 5 "Set_Keycode" 4 "RKE" 3 "Null" 2 "Key" 1 "Erase_KeyCode" 0 "Check_KeyCode" ;
VAL_ 816 KeylessIdl_D_Rq 3 "Cancel" 2 "IgnitionOff" 1 "Active" 0 "Inactive" ;
VAL_ 879 WndwRearHeat_I_Actl 2047 "Faulty" ;
VAL_ 879 WndwRearHeat_D_Stat 7 "NotUsed" 6 "FetLiftLimitReached" 5 "FetOpenCircuit" 4 "FetOutputShortToPower" 3 "FetOutputShortToGround" 2 "FetNotControlled" 1 "OnPowerToLoad" 0 "OffNoPowerToLoad" ;
VAL_ 966 TrnkFrontInhbt_B_Stat 1 "Inhibit" 0 "NoInhibit" ;
VAL_ 966 ExtLghtRear_D_RqBody 3 "NotUsed" 2 "On" 1 "Off" 0 "Null" ;
VAL_ 966 TrnkFrontRleas_D_Src 7 "NotUsed_3" 6 "NotUsed_2" 5 "NotUsed_1" 4 "Cpp" 3 "Sync" 2 "Keypad" 1 "Remote" 0 "Null" ;
VAL_ 966 TrnkFrontScnd_B_Falt 1 "Fault" 0 "No_Fault" ;
